VERSION "ADD"

NS_ :

BS_:

BU_: ADD

BO_ 341 ADD_ChassisCANFD_0x155: 32 ADD
 SG_ HPPAVPRecoverIndCtrl : 135|2@0+ (1,0) [0|3] "" Vector__XXX
 SG_ HPPAVPSteerReqSigGrpChks : 103|8@0+ (1,0) [0|255] "" Vector__XXX
 SG_ HPPAVPSteerReqSigGrpCntr : 107|4@0+ (1,0) [0|15] "" Vector__XXX
 SG_ HPPAVPSteerWhlAglReqVal : 119|15@0- (0.0625,0) [-780|780] "deg" Vector__XXX
 SG_ HPPAVPSteerWhlCtrlReqSts : 133|2@0+ (1,0) [0|3] "" Vector__XXX
 SG_ ParkAPBReqMainFrmADD : 73|2@0+ (1,0) [0|3] "" Vector__XXX
 SG_ ParkEPSLateralCtrlTypeFrmADD : 186|3@0+ (1,0) [0|7] "" Vector__XXX
 SG_ ParkRecoverIndCtrlFrmADD : 188|2@0+ (1,0) [0|3] "" Vector__XXX
 SG_ ParkSteerWhlAglReqValFrmADD : 199|15@0- (0.0625,0) [-1024|1023.9375] "deg" Vector__XXX
 SG_ ParkSteerWhlAngReqSigGrpChks : 175|8@0+ (1,0) [0|255] "" Vector__XXX
 SG_ ParkSteerWhlAngReqSigGrpCntr : 179|4@0+ (1,0) [0|15] "" Vector__XXX
 SG_ ParkSteerWhlCtrlReqStsFrmADD : 214|2@0+ (1,0) [0|3] "" Vector__XXX
 SG_ PASBrkFcnModMainFrmADD : 15|3@0+ (1,0) [0|7] "" Vector__XXX
 SG_ PASBrkFrmADDSigGrpChks : 7|8@0+ (1,0) [0|255] "" Vector__XXX
 SG_ PASBrkFrmADDSigGrpCntr : 11|4@0+ (1,0) [0|15] "" Vector__XXX
 SG_ PASEmgyBrkReqMainFrmADD : 77|1@0+ (1,0) [0|1] "" Vector__XXX
 SG_ PASLoLimForAccrCmftMainFrmADD : 47|8@0+ (0.01,0) [0|2.55] "mps2" Vector__XXX
 SG_ PASMaxAllwdJerkOfAccrMainFrmADD : 87|8@0+ (0.1,0) [0|25.5] "mps3" Vector__XXX
 SG_ PASMinAllwdJerkOfAccrMainFrmADD : 71|8@0+ (0.1,0) [0|25.5] "mps3" Vector__XXX
 SG_ PASRemaDstMainFrmADD : 55|12@0+ (1,0) [0|4095] "" Vector__XXX
 SG_ PASReqAccCtrlEnaMainFrmADD : 12|1@0+ (1,0) [0|1] "" Vector__XXX
 SG_ PASReqBrkPrfeMainFrmADD : 27|1@0+ (1,0) [0|1] "" Vector__XXX
 SG_ PASReqDclUtiStslMainFrmADD : 78|1@0+ (1,0) [0|1] "" Vector__XXX
 SG_ PASReqDrvOffMainFrmADD : 79|1@0+ (1,0) [0|1] "" Vector__XXX
 SG_ PASShdModReqMainFrmADD : 75|2@0+ (1,0) [0|3] "" Vector__XXX
 SG_ PASUpprLimForAccrCmftMainFrmADD : 39|8@0+ (0.01,0) [0|2.55] "mps2" Vector__XXX
 SG_ PASVlcTarAccFromPASMainFrmADD : 23|12@0+ (0.01,-10) [-10|30.95] "mps2" Vector__XXX

BO_ 483 ADD_ChassisCANFD_0x1E3: 16 ADD
 SG_ ADSBSDLCAEnableForSRR : 31|2@0+ (1,0) [0|3] "" Vector__XXX
 SG_ ADSDOWEnableForSRR : 29|2@0+ (1,0) [0|3] "" Vector__XXX
 SG_ ADSRCTABEnableForSRR : 27|2@0+ (1,0) [0|3] "" Vector__XXX
 SG_ ADSRCWEnableForSRR : 25|2@0+ (1,0) [0|3] "" Vector__XXX
 SG_ DvrSpclOpratDistFrmADD : 39|9@0+ (1,0) [0|500] "" Vector__XXX
 SG_ DvrSpclOpratIndFrmADD : 46|4@0+ (1,0) [0|10] "" Vector__XXX
 SG_ GroundAdhereConf : 7|7@0+ (1,0) [0|127] "" Vector__XXX
 SG_ GroundAdhereType : 23|3@0+ (1,0) [0|7] "" Vector__XXX
 SG_ GroundLayingConf : 15|7@0+ (1,0) [0|127] "" Vector__XXX
 SG_ GroundLayingType : 20|3@0+ (1,0) [0|7] "" Vector__XXX
 SG_ RoadMueDistFrmADD : 64|9@0+ (1,0) [0|500] "" Vector__XXX
 SG_ RoadMueFrmADD : 70|4@0+ (0.1,0) [0|1.5] "" Vector__XXX
 SG_ RoadMueLenthFrmADD : 87|9@0+ (1,0) [0|500] "" Vector__XXX

BO_ 769 ADD_ChassisCANFD_0x301: 24 ADD
 SG_ ACCInitSpdSwtFbFrmADD : 79|3@0+ (1,0) [0|7] "" Vector__XXX
 SG_ ACCInitSpdSwtUnavlRsnFrmADD : 135|3@0+ (1,0) [0|7] "" Vector__XXX
 SG_ ADSAEBFCWSwtFbFrmADD : 87|3@0+ (1,0) [0|5] "" Vector__XXX
 SG_ ADSAEBSwtUnavlRsnFrmADD : 95|4@0+ (1,0) [0|11] "" Vector__XXX
 SG_ ADSAESESSSwtFbFrmADD : 23|2@0+ (1,0) [0|3] "" Vector__XXX
 SG_ ADSAudModSwtStsFrmADD : 21|3@0+ (1,0) [0|7] "" Vector__XXX
 SG_ ADSBSDLCASwtFbFrmADD : 18|3@0+ (1,0) [0|7] "" Vector__XXX
 SG_ ADSBSDLCASwtUnavlRsnFrmADD : 91|4@0+ (1,0) [0|11] "" Vector__XXX
 SG_ ADSDOWSwtFbFrmADD : 76|3@0+ (1,0) [0|7] "" Vector__XXX
 SG_ ADSDOWSwtUnavlRsnFrmADD : 103|4@0+ (1,0) [0|11] "" Vector__XXX
 SG_ ADSELKSwtFbFrmADD : 26|3@0+ (1,0) [0|4] "" Vector__XXX
 SG_ ADSELKSwtUnavlRsnFrmADD : 99|4@0+ (1,0) [0|11] "" Vector__XXX
 SG_ ADSLDPWarnTypSwtUnavlRsnFrmADD : 111|4@0+ (1,0) [0|12] "" Vector__XXX
 SG_ ADSLDWPSwtFbFrmADD : 36|3@0+ (1,0) [0|4] "" Vector__XXX
 SG_ ADSLDWPSwtUnavlRsnFrmADD : 107|4@0+ (1,0) [0|11] "" Vector__XXX
 SG_ ADSLDWPWarnTypSwtFbFrmADD : 84|3@0+ (1,0) [0|4] "" Vector__XXX
 SG_ ADSMAISwtFbFrmADD : 175|3@0+ (1,0) [0|7] "" Vector__XXX
 SG_ ADSMAISwtUnavlRsnFrmADD : 179|4@0+ (1,0) [0|15] "" Vector__XXX
 SG_ ADSParkAudModSwtStsFrmADD : 29|3@0+ (1,0) [0|7] "" Vector__XXX
 SG_ ADSRCTABSwtFbFrmADD : 46|3@0+ (1,0) [0|7] "" Vector__XXX
 SG_ ADSRCTABSwtUnavlRsnFrmADD : 119|4@0+ (1,0) [0|11] "" Vector__XXX
 SG_ ADSRCWSwtFbFrmADD : 41|2@0+ (1,0) [0|3] "" Vector__XXX
 SG_ ADSRCWSwtUnavlRsnFrmADD : 115|4@0+ (1,0) [0|11] "" Vector__XXX
 SG_ ADSTLASwtFbFrmADD : 187|2@0+ (1,0) [0|3] "" Vector__XXX
 SG_ ADSTLASwtUnavlRsnFrmADD : 183|4@0+ (1,0) [0|11] "" Vector__XXX
 SG_ ADSwtStsSigGrpChks : 7|8@0+ (1,0) [0|255] "" Vector__XXX
 SG_ ADSwtStsSigGrpCntr : 11|4@0+ (1,0) [0|15] "" Vector__XXX
 SG_ ALCSwtStsFrmADD : 55|3@0+ (1,0) [0|7] "" Vector__XXX
 SG_ ALCSwtUnavlRsnFrmADD : 127|4@0+ (1,0) [0|15] "" Vector__XXX
 SG_ FxdSpdModValSwtStsFrmADD : 143|6@0+ (1,0) [0|63] "" Vector__XXX
 SG_ LaneChgCnfmSwtStsFrmADD : 52|2@0+ (1,0) [0|3] "" Vector__XXX
 SG_ LowPwrReqFrLRRFrmADD : 185|2@0+ (1,0) [0|3] "" Vector__XXX
 SG_ LowPwrSwtFbFrmADD : 50|3@0+ (1,0) [0|7] "" Vector__XXX
 SG_ LowPwrSwtUnavlRsnFrmADD : 71|3@0+ (1,0) [0|5] "" Vector__XXX
 SG_ LowPwrWarnFrmADD : 63|3@0+ (1,0) [0|7] "" Vector__XXX
 SG_ NOAautoChangingSrAnimation : 191|2@0+ (1,0) [0|3] "" Vector__XXX
 SG_ NOACtySwtStsFrmADD : 162|3@0+ (1,0) [0|7] "" Vector__XXX
 SG_ NOAHWSwtStsFrmADD : 58|3@0+ (1,0) [0|7] "" Vector__XXX
 SG_ NOASwtUnavlRsnFrmADD : 123|4@0+ (1,0) [0|15] "" Vector__XXX
 SG_ PcntgeSpdModValSwtStsFrmADD : 148|5@0+ (1,0) [0|31] "" Vector__XXX
 SG_ PltSwtStsFrmADD : 68|3@0+ (1,0) [0|7] "" Vector__XXX
 SG_ PltSwtUnavlRsnFrmADD : 159|4@0+ (1,0) [0|15] "" Vector__XXX
 SG_ PntCldSwtFbFrmADD : 65|2@0+ (1,0) [0|3] "" Vector__XXX
 SG_ PntCldSwtUnavlRsnFrmADD : 155|4@0+ (1,0) [0|15] "" Vector__XXX
 SG_ PrivacyModIniStsFrmADD : 137|2@0+ (1,0) [0|3] "" Vector__XXX
 SG_ PrivacyModSwtFbFrmADD : 167|2@0+ (1,0) [0|3] "" Vector__XXX
 SG_ SRLidarCldReqFrmADD : 189|2@0+ (1,0) [0|3] "" Vector__XXX
 SG_ VehSpdDvtionModSwtStsFrmADD : 165|3@0+ (1,0) [0|7] "" Vector__XXX

BO_ 131 ADD_ChassisCANFD_0x83: 16 ADD
 SG_ ChecksumADD2Radar : 15|8@0+ (1,0) [0|255] "" Vector__XXX
 SG_ OfsTimeNSecADD2Radar : 103|32@0+ (1,0) [0|4294967295] "" Vector__XXX
 SG_ OfsTimeSecADD2Radar : 71|32@0+ (1,0) [0|4294967295] "" Vector__XXX
 SG_ SyncMsgOvsADD2Radar : 25|2@0+ (1,0) [0|3] "" Vector__XXX
 SG_ SyncMsgSequenceCounterADD2Radar : 19|4@0+ (1,0) [0|15] "" Vector__XXX
 SG_ SyncMsgSgwADDtoRadar : 26|1@0+ (1,0) [0|1] "" Vector__XXX
 SG_ SyncMsgSyncTimeADD2Radar : 39|32@0+ (1,0) [0|4294967295] "" Vector__XXX
 SG_ SyncMsgTimeDomainADD2Radar : 23|4@0+ (1,0) [0|15] "" Vector__XXX
 SG_ SyncMsgTypeADD2Radar : 7|8@0+ (1,0) [0|255] "" Vector__XXX

BO_ 177 ADD_ChassisCANFD_0xB1: 32 ADD
 SG_ ADSABALvlFrmADD : 183|3@0+ (1,0) [0|7] "" Vector__XXX
 SG_ ADSABAReqFrmADD : 180|1@0+ (1,0) [0|1] "" Vector__XXX
 SG_ ADSABPReqFrmADD : 179|1@0+ (1,0) [0|1] "" Vector__XXX
 SG_ ADSAEBReqFrmADD : 178|3@0+ (1,0) [0|7] "" Vector__XXX
 SG_ ADSAEBTarDecelFrmADD : 191|10@0+ (0.03125,-16) [-16|15.96875] "mps2" Vector__XXX
 SG_ ADSAWBAESLvlFrmADD : 197|3@0+ (1,0) [0|7] "" Vector__XXX
 SG_ ADSAWBAESReqFrmADD : 194|2@0+ (1,0) [0|3] "" Vector__XXX
 SG_ ADSMAIAccrPerReqFrmADD : 231|8@0+ (1,0) [0|255] "%" Vector__XXX
 SG_ ADSMAIAccrPerReqVldFrmADD : 223|1@0+ (1,0) [0|1] "" Vector__XXX
 SG_ ADSMAIReqFrmADD : 222|1@0+ (1,0) [0|1] "" Vector__XXX
 SG_ ADSMAIReqVldFrmADD : 221|1@0+ (1,0) [0|1] "" Vector__XXX
 SG_ ADSVibActvFrmADD : 143|1@0+ (1,0) [0|1] "" Vector__XXX
 SG_ DrvAxTarEnaMainFrmADD : 31|1@0+ (1,0) [0|1] "" Vector__XXX
 SG_ DrvAxTarLowerComfBandMainFrmADD : 30|7@0+ (0.01,0) [0|1.27] "mps2" Vector__XXX
 SG_ DrvAxTarReqMainFrmADD : 55|15@0+ (0.001,-20.48) [-20.48|12.287] "mps2" Vector__XXX
 SG_ DrvAxTarUpperComfBandMainFrmADD : 22|7@0+ (0.01,0) [0|1.27] "mps2" Vector__XXX
 SG_ DrvBrakePreferredMainFrmADD : 47|1@0+ (1,0) [0|1] "" Vector__XXX
 SG_ DrvCtrlAvailabilityMainFrmADD : 15|1@0+ (1,0) [0|1] "" Vector__XXX
 SG_ DrvdAxTarLowerLimitMainFrmADD : 46|7@0+ (0.1,0) [0|12.7] "mps3" Vector__XXX
 SG_ DrvdAxTarUpperLimitMainFrmADD : 70|7@0+ (0.1,0) [0|12.7] "mps3" Vector__XXX
 SG_ DrvDriveAwayReqMainFrmADD : 36|1@0+ (1,0) [0|1] "" Vector__XXX
 SG_ DrvFcn2FrmADDSigGrpChks : 7|8@0+ (1,0) [0|255] "" Vector__XXX
 SG_ DrvFcn2FrmADDSigGrpCntr : 11|4@0+ (1,0) [0|15] "" Vector__XXX
 SG_ DrvFcn3FrmADDSigGrpChks : 167|8@0+ (1,0) [0|255] "" Vector__XXX
 SG_ DrvFcn3FrmADDSigGrpCntr : 171|4@0+ (1,0) [0|15] "" Vector__XXX
 SG_ DrvFcn4FrmADDSigGrpChks : 215|8@0+ (1,0) [0|255] "" Vector__XXX
 SG_ DrvFcn4FrmADDSigGrpCntr : 219|4@0+ (1,0) [0|15] "" Vector__XXX
 SG_ DrvPinStrAglReqStsFrmADD : 129|2@0+ (1,0) [0|3] "" Vector__XXX
 SG_ DrvPinStrAglReqValFrmADD : 102|15@0+ (0.05,-819.2) [-819.2|819.15] "deg" Vector__XXX
 SG_ DrvPrecsReqFrmADD : 142|7@0+ (1,0) [0|126] "%" Vector__XXX
 SG_ DrvReqModeMainFrmADD : 13|2@0+ (1,0) [0|3] "" Vector__XXX
 SG_ DrvReqTypeMainFrmADD : 14|1@0+ (1,0) [0|1] "" Vector__XXX
 SG_ DrvSecureReqMainFrmADD : 23|1@0+ (1,0) [0|1] "" Vector__XXX
 SG_ DrvShutdownModeMainFrmADD : 38|2@0+ (1,0) [0|3] "" Vector__XXX
 SG_ DrvSteerWhlReqFrmADDSigGrpChks : 87|8@0+ (1,0) [0|255] "" Vector__XXX
 SG_ DrvSteerWhlReqFrmADDSigGrpCntr : 91|4@0+ (1,0) [0|15] "" Vector__XXX
 SG_ DrvSteerWhlTqLimFrmADD : 119|11@0+ (0.01,-10.24) [-10.24|10.23] "Nm" Vector__XXX
 SG_ DrvUseUpperComfBandMainFrmADD : 39|1@0+ (1,0) [0|1] "" Vector__XXX
 SG_ DrvVehStopReqMainFrmADD : 56|1@0+ (1,0) [0|1] "" Vector__XXX

BO_ 193 ADD_ChassisCANFD_0xC1: 16 ADD
 SG_ ADASGearFcnModMainFrmADD : 55|3@0+ (1,0) [0|7] "" Vector__XXX
 SG_ ADASParkDrvFcnModMainFrmADD : 52|3@0+ (1,0) [0|7] "" Vector__XXX
 SG_ ADASParkDrvModOverrideFrmADD : 49|2@0+ (1,0) [0|3] "" Vector__XXX
 SG_ ADASParkDrvVehWheelTqEnaFrmADD : 63|1@0+ (1,0) [0|1] "" Vector__XXX
 SG_ ADASParkDrvVehWheelTqReqFrmADD : 39|16@0+ (1,-30000) [-30000|30000] "" Vector__XXX
 SG_ ADSAVHReqFrmADD : 62|2@0+ (1,0) [0|3] "" Vector__XXX
 SG_ ADSBCSTqReqChks : 7|8@0+ (1,0) [0|255] "" Vector__XXX
 SG_ ADSBCSTqReqCntr : 11|4@0+ (1,0) [0|15] "" Vector__XXX
 SG_ ADSEPBReqMainFrmADD : 13|2@0+ (1,0) [0|3] "" Vector__XXX
 SG_ ADSReqModeMainFrmADD : 60|3@0+ (1,0) [0|7] "" Vector__XXX
 SG_ ADSTqTarEnaMainTypeFrmADD : 57|2@0+ (1,0) [0|3] "" Vector__XXX
 SG_ ADSTqTarReqMainFrmADD : 23|16@0+ (1,-30000) [-30000|0] "" Vector__XXX

BO_ 237 ADD_ChassisCANFD_0xED: 16 ADD
 SG_ ADSACCStsFrmADD : 18|3@0+ (1,0) [0|7] "" Vector__XXX
 SG_ ADSWarnRemdSigGrpChks : 39|8@0+ (1,0) [0|255] "" Vector__XXX
 SG_ ADSWarnRemdSigGrpCntr : 43|4@0+ (1,0) [0|15] "" Vector__XXX
 SG_ CNOAAlrtWarnLv1FrmADD : 93|3@0+ (1,0) [0|7] "" Vector__XXX
 SG_ CNOAAlrtWarnLv3FrmADD : 90|3@0+ (1,0) [0|7] "" Vector__XXX
 SG_ CNOAIntrctvCompntTypFrmADD : 119|5@0+ (1,0) [0|31] "" Vector__XXX
 SG_ CNOARemd2FrmADD : 47|4@0+ (1,0) [0|15] "" Vector__XXX
 SG_ CNOARemdFrmADD : 127|5@0+ (1,0) [0|31] "" Vector__XXX
 SG_ DistLvlLmtDispFrmADD : 55|2@0+ (1,0) [0|3] "" Vector__XXX
 SG_ DrvAlrtWarnLv1FrmADD : 53|3@0+ (1,0) [0|7] "" Vector__XXX
 SG_ DrvAlrtWarnLv2FrmADD : 50|3@0+ (1,0) [0|7] "" Vector__XXX
 SG_ DrvAlrtWarnLv3FrmADD : 71|3@0+ (1,0) [0|7] "" Vector__XXX
 SG_ DrvFcn1FrmADDSigGrpChks : 7|8@0+ (1,0) [0|255] "" Vector__XXX
 SG_ DrvFcn1FrmADDSigGrpCntr : 11|4@0+ (1,0) [0|15] "" Vector__XXX
 SG_ DrvFltStsFrmADD : 21|3@0+ (1,0) [0|7] "" Vector__XXX
 SG_ DrvFltStsVldFrmADD : 22|1@0+ (1,0) [0|1] "" Vector__XXX
 SG_ DrvLatIcnDispStsFrmADD : 63|4@0+ (1,0) [0|15] "" Vector__XXX
 SG_ DrvLongIcnDispFrmADD : 68|3@0+ (1,0) [0|7] "" Vector__XXX
 SG_ DrvRemd2FrmADD : 59|4@0+ (1,0) [0|15] "" Vector__XXX
 SG_ DrvRemdFrmADD : 103|7@0+ (1,0) [0|127] "" Vector__XXX
 SG_ DrvrSelTarSpdFrmADD : 96|9@0+ (1,0) [0|255] "kmph" Vector__XXX
 SG_ DrvSteerWhlBtnLi : 65|2@0+ (1,0) [0|3] "" Vector__XXX
 SG_ DrvStlDispFrmADD : 79|3@0+ (1,0) [0|7] "" Vector__XXX
 SG_ IntrctvCompntTypFrmADD : 87|6@0+ (1,0) [0|63] "" Vector__XXX
 SG_ LaneChangeModFrmADD : 76|2@0+ (1,0) [0|3] "" Vector__XXX
 SG_ ScrnDrvFuncTypFrmADD : 74|3@0+ (1,0) [0|7] "" Vector__XXX
 SG_ SpdLvlLmtDispFrmADD : 81|2@0+ (1,0) [0|3] "" Vector__XXX
 SG_ TarSpdSetMothodFrmADD : 95|2@0+ (1,0) [0|3] "" Vector__XXX

BO_ 1329 ADDChassisCanfdNMFrA: 8 ADD
 SG_ ADDChassisCanfdActiveWakeup : 12|1@0+ (1,0) [0|1] "" Vector__XXX
 SG_ ADDChassisCanfdNodeAddress : 7|8@0+ (1,0) [0|255] "" Vector__XXX
 SG_ ADDChassisCanfdRepeatMsgReq : 8|1@0+ (1,0) [0|1] "" Vector__XXX
 SG_ ADDChassisCanfdRepeatMsgSt : 16|1@0+ (1,0) [0|1] "" Vector__XXX
 SG_ NMKeepAwkRsnADD : 48|9@0+ (1,0) [0|511] "" Vector__XXX
 SG_ UDB17ADD : 17|1@0+ (1,0) [0|1] "" Vector__XXX
 SG_ UDB18ADD : 18|1@0+ (1,0) [0|1] "" Vector__XXX
 SG_ UDB19ADD : 19|1@0+ (1,0) [0|1] "" Vector__XXX
 SG_ UDB20ADD : 20|1@0+ (1,0) [0|1] "" Vector__XXX
 SG_ UDB21ADD : 21|1@0+ (1,0) [0|1] "" Vector__XXX
 SG_ UDB22ADD : 22|1@0+ (1,0) [0|1] "" Vector__XXX
 SG_ UDB23ADD : 23|1@0+ (1,0) [0|1] "" Vector__XXX
 SG_ UDB24ADD : 24|1@0+ (1,0) [0|1] "" Vector__XXX
 SG_ UDB25ADD : 25|1@0+ (1,0) [0|1] "" Vector__XXX
 SG_ UDB26ADD : 26|1@0+ (1,0) [0|1] "" Vector__XXX
 SG_ UDB27ADD : 27|1@0+ (1,0) [0|1] "" Vector__XXX
 SG_ UDB28ADD : 28|1@0+ (1,0) [0|1] "" Vector__XXX
 SG_ UDB29ADD : 29|1@0+ (1,0) [0|1] "" Vector__XXX
 SG_ UDB30ADD : 30|1@0+ (1,0) [0|1] "" Vector__XXX
 SG_ UDB31ADD : 31|1@0+ (1,0) [0|1] "" Vector__XXX
 SG_ UDB32ADD : 32|1@0+ (1,0) [0|1] "" Vector__XXX
 SG_ UDB33ADD : 33|1@0+ (1,0) [0|1] "" Vector__XXX
 SG_ UDB34ADD : 34|1@0+ (1,0) [0|1] "" Vector__XXX
 SG_ UDB35ADD : 35|1@0+ (1,0) [0|1] "" Vector__XXX
 SG_ UDB36ADD : 36|1@0+ (1,0) [0|1] "" Vector__XXX
 SG_ UDB37ADD : 37|1@0+ (1,0) [0|1] "" Vector__XXX
 SG_ UDB38ADD : 38|1@0+ (1,0) [0|1] "" Vector__XXX
 SG_ UDB39ADD : 39|1@0+ (1,0) [0|1] "" Vector__XXX
 SG_ UDB40ADD : 40|1@0+ (1,0) [0|1] "" Vector__XXX
 SG_ UDB41ADD : 41|1@0+ (1,0) [0|1] "" Vector__XXX
 SG_ UDB42ADD : 42|1@0+ (1,0) [0|1] "" Vector__XXX
 SG_ UDB43ADD : 43|1@0+ (1,0) [0|1] "" Vector__XXX
 SG_ UDB44ADD : 44|1@0+ (1,0) [0|1] "" Vector__XXX
 SG_ UDB45ADD : 45|1@0+ (1,0) [0|1] "" Vector__XXX
 SG_ UDB46ADD : 46|1@0+ (1,0) [0|1] "" Vector__XXX
 SG_ UDB47ADD : 47|1@0+ (1,0) [0|1] "" Vector__XXX

BO_ 1325 ADDChassisCanfdNMFrB: 8 ADD
 SG_ ADDChassisCanfdActiveWakeup1 : 12|1@0+ (1,0) [0|1] "" Vector__XXX
 SG_ ADDChassisCanfdNodeAddress1 : 7|8@0+ (1,0) [0|255] "" Vector__XXX
 SG_ ADDChassisCanfdRepeatMsgReq1 : 8|1@0+ (1,0) [0|1] "" Vector__XXX
 SG_ ADDChassisCanfdRepeatMsgSt1 : 16|1@0+ (1,0) [0|1] "" Vector__XXX
 SG_ NMKeepAwkRsnADD : 48|9@0+ (1,0) [0|511] "" Vector__XXX
 SG_ UDB17ADD : 17|1@0+ (1,0) [0|1] "" Vector__XXX
 SG_ UDB18ADD : 18|1@0+ (1,0) [0|1] "" Vector__XXX
 SG_ UDB19ADD : 19|1@0+ (1,0) [0|1] "" Vector__XXX
 SG_ UDB20ADD : 20|1@0+ (1,0) [0|1] "" Vector__XXX
 SG_ UDB21ADD : 21|1@0+ (1,0) [0|1] "" Vector__XXX
 SG_ UDB22ADD : 22|1@0+ (1,0) [0|1] "" Vector__XXX
 SG_ UDB23ADD : 23|1@0+ (1,0) [0|1] "" Vector__XXX
 SG_ UDB24ADD : 24|1@0+ (1,0) [0|1] "" Vector__XXX
 SG_ UDB25ADD : 25|1@0+ (1,0) [0|1] "" Vector__XXX
 SG_ UDB26ADD : 26|1@0+ (1,0) [0|1] "" Vector__XXX
 SG_ UDB27ADD : 27|1@0+ (1,0) [0|1] "" Vector__XXX
 SG_ UDB28ADD : 28|1@0+ (1,0) [0|1] "" Vector__XXX
 SG_ UDB29ADD : 29|1@0+ (1,0) [0|1] "" Vector__XXX
 SG_ UDB30ADD : 30|1@0+ (1,0) [0|1] "" Vector__XXX
 SG_ UDB31ADD : 31|1@0+ (1,0) [0|1] "" Vector__XXX
 SG_ UDB32ADD : 32|1@0+ (1,0) [0|1] "" Vector__XXX
 SG_ UDB33ADD : 33|1@0+ (1,0) [0|1] "" Vector__XXX
 SG_ UDB34ADD : 34|1@0+ (1,0) [0|1] "" Vector__XXX
 SG_ UDB35ADD : 35|1@0+ (1,0) [0|1] "" Vector__XXX
 SG_ UDB36ADD : 36|1@0+ (1,0) [0|1] "" Vector__XXX
 SG_ UDB37ADD : 37|1@0+ (1,0) [0|1] "" Vector__XXX
 SG_ UDB38ADD : 38|1@0+ (1,0) [0|1] "" Vector__XXX
 SG_ UDB39ADD : 39|1@0+ (1,0) [0|1] "" Vector__XXX
 SG_ UDB40ADD : 40|1@0+ (1,0) [0|1] "" Vector__XXX
 SG_ UDB41ADD : 41|1@0+ (1,0) [0|1] "" Vector__XXX
 SG_ UDB42ADD : 42|1@0+ (1,0) [0|1] "" Vector__XXX
 SG_ UDB43ADD : 43|1@0+ (1,0) [0|1] "" Vector__XXX
 SG_ UDB44ADD : 44|1@0+ (1,0) [0|1] "" Vector__XXX
 SG_ UDB45ADD : 45|1@0+ (1,0) [0|1] "" Vector__XXX
 SG_ UDB46ADD : 46|1@0+ (1,0) [0|1] "" Vector__XXX
 SG_ UDB47ADD : 47|1@0+ (1,0) [0|1] "" Vector__XXX

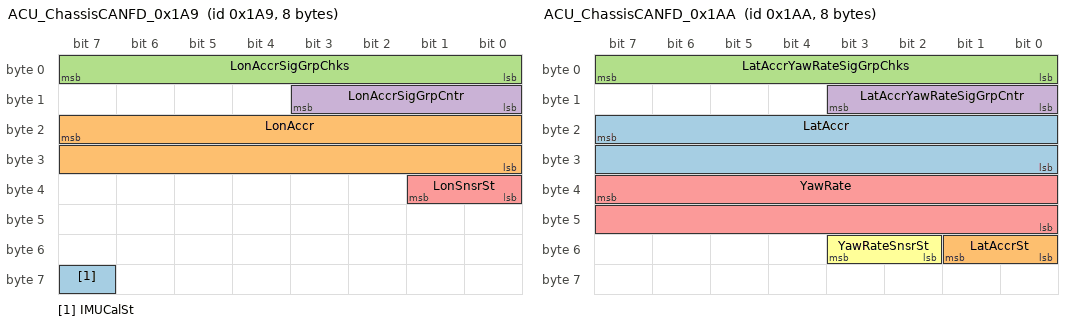
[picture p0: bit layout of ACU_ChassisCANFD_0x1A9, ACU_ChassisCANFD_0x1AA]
BO_ 425 ACU_ChassisCANFD_0x1A9: 8 Vector__XXX
 SG_ IMUCalSt : 63|1@0+ (1,0) [0|1] ""  ADD
 SG_ LonAccr : 23|16@0+ (0.0002,-5) [-5|5] "g"  ADD
 SG_ LonAccrSigGrpChks : 7|8@0+ (1,0) [0|255] ""  ADD
 SG_ LonAccrSigGrpCntr : 11|4@0+ (1,0) [0|15] ""  ADD
 SG_ LonSnsrSt : 33|2@0+ (1,0) [0|3] ""  ADD

BO_ 426 ACU_ChassisCANFD_0x1AA: 8 Vector__XXX
 SG_ LatAccr : 23|16@0+ (0.0002,-5) [-5|5] "g"  ADD
 SG_ LatAccrSt : 49|2@0+ (1,0) [0|3] ""  ADD
 SG_ LatAccrYawRateSigGrpChks : 7|8@0+ (1,0) [0|255] ""  ADD
 SG_ LatAccrYawRateSigGrpCntr : 11|4@0+ (1,0) [0|15] ""  ADD
 SG_ YawRate : 39|16@0+ (0.01,-300) [-300|300] "deg/s"  ADD
 SG_ YawRateSnsrSt : 51|2@0+ (1,0) [0|3] ""  ADD

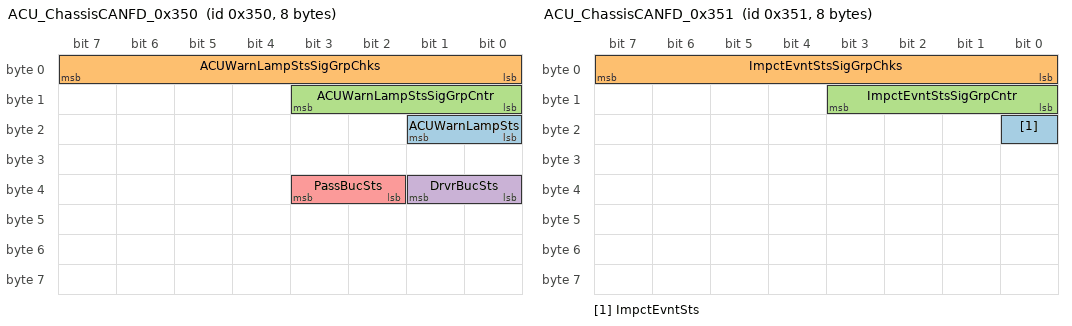
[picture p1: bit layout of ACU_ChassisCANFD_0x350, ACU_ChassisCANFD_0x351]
BO_ 848 ACU_ChassisCANFD_0x350: 8 Vector__XXX
 SG_ ACUWarnLampSts : 17|2@0+ (1,0) [0|3] ""  ADD
 SG_ ACUWarnLampStsSigGrpChks : 7|8@0+ (1,0) [0|255] ""  ADD
 SG_ ACUWarnLampStsSigGrpCntr : 11|4@0+ (1,0) [0|15] ""  ADD
 SG_ DrvrBucSts : 33|2@0+ (1,0) [0|3] ""  ADD
 SG_ PassBucSts : 35|2@0+ (1,0) [0|3] ""  ADD

BO_ 849 ACU_ChassisCANFD_0x351: 8 Vector__XXX
 SG_ ImpctEvntSts : 16|1@0+ (1,0) [0|1] ""  ADD
 SG_ ImpctEvntStsSigGrpChks : 7|8@0+ (1,0) [0|255] ""  ADD
 SG_ ImpctEvntStsSigGrpCntr : 11|4@0+ (1,0) [0|15] ""  ADD

BO_ 336 BCP_ChassisCANFD_0x150: 16 Vector__XXX
 SG_ ABAActv : 94|1@0+ (1,0) [0|1] ""  ADD
 SG_ ABAAvl : 95|1@0+ (1,0) [0|1] ""  ADD
 SG_ APBAplAvlBCP : 61|2@0+ (1,0) [0|2] ""  ADD
 SG_ APBRelAvlBCP : 59|2@0+ (1,0) [0|3] ""  ADD
 SG_ APBStsBkp : 91|3@0+ (1,0) [0|7] ""  ADD
 SG_ BCPBrkLiIllmnReq : 19|1@0+ (1,0) [0|1] ""  ADD
 SG_ BCPBrkSysWarnText : 45|3@0+ (1,0) [0|7] ""  ADD
 SG_ BCPMstCylP : 57|10@0+ (0.3,-30) [-30|276.6] "bar"  ADD
 SG_ BCPMstCylPVld : 15|2@0+ (1,0) [0|2] ""  ADD
 SG_ BCPSimulatorP : 41|10@0+ (0.3,-30) [-30|276.6] "bar"  ADD
 SG_ BCPSimulatorPVld : 63|2@0+ (1,0) [0|2] ""  ADD
 SG_ BCPSysSts : 47|2@0+ (1,0) [0|3] ""  ADD
 SG_ BcpSysStsSigGrpChks : 7|8@0+ (1,0) [0|255] ""  ADD
 SG_ BcpSysStsSigGrpCntr : 11|4@0+ (1,0) [0|15] ""  ADD
 SG_ BrkAssSigGrpChks : 79|8@0+ (1,0) [0|255] ""  ADD
 SG_ BrkAssSigGrpCntr : 83|4@0+ (1,0) [0|15] ""  ADD
 SG_ BrkFldWarn : 23|1@0+ (1,0) [0|1] ""  ADD
 SG_ BrkFldWarnVld : 42|1@0+ (1,0) [0|1] ""  ADD
 SG_ BrkPedlAppld : 22|1@0+ (1,0) [0|1] ""  ADD
 SG_ BrkPedlAppldVld : 21|2@0+ (1,0) [0|3] ""  ADD
 SG_ BrkPedlPerct : 38|7@0+ (1,0) [0|100] "%"  ADD
 SG_ BrkPedlPerctVld : 39|1@0+ (1,0) [0|1] ""  ADD
 SG_ HBAActv : 92|1@0+ (1,0) [0|1] ""  ADD
 SG_ HBAAvl : 93|1@0+ (1,0) [0|1] ""  ADD
 SG_ HBBActv : 110|1@0+ (1,0) [0|1] ""  ADD
 SG_ InpRodStk : 17|10@0+ (0.05,-5) [-5|46.1] "mm"  ADD
 SG_ InpRodStkVld : 18|1@0+ (1,0) [0|1] ""  ADD

BO_ 337 BCS_ChassisCANFD_0x151: 32 Vector__XXX
 SG_ ABPActv : 191|1@0+ (1,0) [0|1] ""  ADD
 SG_ ABPAvl : 197|1@0+ (1,0) [0|1] ""  ADD
 SG_ ABSActv : 16|1@0+ (1,0) [0|1] ""  ADD
 SG_ ABSErrDetd : 29|1@0+ (1,0) [0|1] ""  ADD
 SG_ AEBActv : 189|1@0+ (1,0) [0|1] ""  ADD
 SG_ AEBAvl : 190|1@0+ (1,0) [0|1] ""  ADD
 SG_ APBAplAvlBCS : 135|2@0+ (1,0) [0|2] ""  ADD
 SG_ APBErrDetd : 115|2@0+ (1,0) [0|3] ""  ADD
 SG_ APBRelAvlBCS : 133|2@0+ (1,0) [0|3] ""  ADD
 SG_ APBSts : 118|3@0+ (1,0) [0|7] ""  ADD
 SG_ APBTxtDip : 43|4@0+ (1,0) [0|15] ""  ADD
 SG_ AVHAvl : 139|1@0+ (1,0) [0|1] ""  ADD
 SG_ AVHSts : 141|2@0+ (1,0) [0|3] ""  ADD
 SG_ AWBActv : 198|1@0+ (1,0) [0|1] ""  ADD
 SG_ AWBAvl : 199|1@0+ (1,0) [0|1] ""  ADD
 SG_ BcsBasicFcnSigGrpChks : 87|8@0+ (1,0) [0|255] ""  ADD
 SG_ BcsBasicFcnSigGrpCntr : 91|4@0+ (1,0) [0|15] ""  ADD
 SG_ BCSBrkSysWarnText : 52|3@0+ (1,0) [0|7] ""  ADD
 SG_ BcsExtdFcnSigGrpChks : 175|8@0+ (1,0) [0|255] ""  ADD
 SG_ BcsExtdFcnSigGrpCntr : 179|4@0+ (1,0) [0|15] ""  ADD
 SG_ BcsSysCtrSigGrpChks : 7|8@0+ (1,0) [0|255] ""  ADD
 SG_ BcsSysCtrSigGrpCntr : 11|4@0+ (1,0) [0|15] ""  ADD
 SG_ BrkLiIllmnReq : 15|1@0+ (1,0) [0|1] ""  ADD
 SG_ BrkSysWarnLamp : 23|2@0+ (1,0) [0|3] ""  ADD
 SG_ CDPActv : 137|1@0+ (1,0) [0|1] ""  ADD
 SG_ CDPAvl : 136|1@0+ (1,0) [0|1] ""  ADD
 SG_ CSTSts : 58|2@0+ (1,0) [0|3] ""  ADD
 SG_ DrvOffTqThd : 103|15@0+ (1,0) [0|30000] "Nm"  ADD
 SG_ DSTActv : 119|1@0+ (1,0) [0|1] ""  ADD
 SG_ DSTSteerTqReq : 112|9@0- (0.1,0) [-6|6] "Nm"  ADD
 SG_ EBAActv : 188|1@0+ (1,0) [0|1] ""  ADD
 SG_ EBDActv : 31|1@0+ (1,0) [0|1] ""  ADD
 SG_ EBDErrDetd : 28|1@0+ (1,0) [0|1] ""  ADD
 SG_ EmgyBrkLiReq : 27|1@0+ (1,0) [0|1] ""  ADD
 SG_ ESCErrDetd : 30|1@0+ (1,0) [0|1] ""  ADD
 SG_ ESCIntvLamp : 19|1@0+ (1,0) [0|1] ""  ADD
 SG_ ESCPataLamp : 21|2@0+ (1,0) [0|3] ""  ADD
 SG_ ESCSwitchAvl : 55|3@0+ (1,0) [0|7] ""  ADD
 SG_ EstimdSumOfVehHydBrkEachWhl : 71|15@0+ (8,-250000) [-250000|0] "N"  ADD
 SG_ HBBActive : 72|1@0+ (1,0) [0|1] ""  ADD
 SG_ HBBSts : 63|2@0+ (1,0) [0|3] ""  ADD
 SG_ HBCActv : 56|1@0+ (1,0) [0|1] ""  ADD
 SG_ HDCAvl : 61|1@0+ (1,0) [0|1] ""  ADD
 SG_ HDCCtrlSts : 60|2@0+ (1,0) [0|3] ""  ADD
 SG_ HHCActv : 143|1@0+ (1,0) [0|1] ""  ADD
 SG_ HHCAvl : 142|1@0+ (1,0) [0|1] ""  ADD
 SG_ HRBActv : 25|1@0+ (1,0) [0|1] ""  ADD
 SG_ HRBAvl : 26|1@0+ (1,0) [0|1] ""  ADD
 SG_ HydBrkFExist : 14|1@0+ (1,0) [0|1] ""  ADD
 SG_ MstCylPCmp : 39|12@0+ (0.1,0) [0|250] "bar"  ADD
 SG_ MstCylPVld : 48|1@0+ (1,0) [0|1] ""  ADD
 SG_ SCMActv : 104|1@0+ (1,0) [0|1] ""  ADD
 SG_ SCMAvl : 138|1@0+ (1,0) [0|1] ""  ADD
 SG_ TCSActv : 17|1@0+ (1,0) [0|1] ""  ADD
 SG_ VDCActv : 18|1@0+ (1,0) [0|1] ""  ADD
 SG_ VehStandStillIndcr : 13|1@0+ (1,0) [0|1] ""  ADD
 SG_ VehStandStillIndcrVld : 12|1@0+ (1,0) [0|1] ""  ADD

BO_ 338 BCS_ChassisCANFD_0x152: 24 Vector__XXX
 SG_ APAActrAvl : 163|1@0+ (1,0) [0|1] ""  ADD
 SG_ APCActvVehHld : 175|1@0+ (1,0) [0|1] ""  ADD
 SG_ APCDrvrBrkOvrdFlg : 174|1@0+ (1,0) [0|1] ""  ADD
 SG_ APCFailrSts : 167|4@0+ (1,0) [0|15] ""  ADD
 SG_ ApcFcnSigGrpChks : 151|8@0+ (1,0) [0|255] ""  ADD
 SG_ ApcFcnSigGrpCntr : 155|4@0+ (1,0) [0|15] ""  ADD
 SG_ APCSts : 162|3@0+ (1,0) [0|4] ""  ADD
 SG_ BCSLgtCtrlPtTarTq : 39|16@0- (1,0) [-30000|30000] "Nm"  ADD
 SG_ BCSLgtCtrlPtTarTqEna : 24|1@0+ (1,0) [0|1] ""  ADD
 SG_ BcsTqCtrlSigGrpChks : 7|8@0+ (1,0) [0|255] ""  ADD
 SG_ BcsTqCtrlSigGrpCntr : 11|4@0+ (1,0) [0|15] ""  ADD
 SG_ BiasMaxFrntAxle : 119|7@0+ (1,0) [0|100] "%"  ADD
 SG_ BiasMaxReAxle : 127|7@0+ (1,0) [0|100] "%"  ADD
 SG_ CstRgnBlendSts : 135|2@0+ (1,0) [0|3] ""  ADD
 SG_ CstRgnBlendTqReqFA : 55|16@0- (1,0) [-30000|30000] "Nm"  ADD
 SG_ CstRgnBlendTqReqRA : 71|16@0- (1,0) [-30000|30000] "Nm"  ADD
 SG_ DrgTqCtrlActvFA : 112|1@0+ (1,0) [0|1] ""  ADD
 SG_ DrgTqCtrlActvRA : 120|1@0+ (1,0) [0|1] ""  ADD
 SG_ PtTqRednActvFA : 14|1@0+ (1,0) [0|1] ""  ADD
 SG_ PtTqRednActvRA : 15|1@0+ (1,0) [0|1] ""  ADD
 SG_ RPAAVPActrAvl : 173|2@0+ (1,0) [0|3] ""  ADD
 SG_ TarRdcdPtTqFA : 87|16@0- (1,0) [-30000|30000] "Nm"  ADD
 SG_ TarRdcdPtTqRA : 103|16@0- (1,0) [-30000|30000] "Nm"  ADD
 SG_ TarRecuTqReq : 23|15@0+ (1,-32767) [-32767|0] "Nm"  ADD
 SG_ TarRecuTqReqSts : 13|2@0+ (1,0) [0|3] ""  ADD

BO_ 352 BCS_ChassisCANFD_0x160: 32 Vector__XXX
 SG_ BcsDrvMonSigGrpChks : 39|8@0+ (1,0) [0|255] ""  ADD
 SG_ BcsDrvMonSigGrpCntr : 43|4@0+ (1,0) [0|15] ""  ADD
 SG_ BrkDiscTFrntLe : 55|8@0+ (5,-100) [-100|1000] "��"  ADD
 SG_ BrkDiscTFrntRi : 63|8@0+ (5,-100) [-100|1000] "��"  ADD
 SG_ BrkDiscTReLe : 71|8@0+ (5,-100) [-100|1000] "��"  ADD
 SG_ BrkDiscTReRi : 79|8@0+ (5,-100) [-100|1000] "��"  ADD
 SG_ BrkDiscTSts : 45|2@0+ (1,0) [0|3] ""  ADD
 SG_ BrkDiscTStsAval : 47|2@0+ (1,0) [0|2] ""  ADD
 SG_ RgnTqCorrnOffs1 : 87|16@0+ (0.05625,0) [0|360] ""  ADD
 SG_ RgnTqCorrnOffs2 : 103|8@0+ (1,-100) [-100|100] ""  ADD
 SG_ RgnTqCorrnOffs3 : 111|8@0+ (0.01,0) [0|1.5] ""  ADD
 SG_ RgnTqCorrnOffs4 : 119|16@0- (0.01,0) [-250|250] ""  ADD
 SG_ RgnTqCorrnOffs5 : 135|14@0+ (0.1,-100) [-100|1000] ""  ADD
 SG_ RgnTqCorrnOffs6 : 151|14@0+ (0.1,-100) [-100|1000] ""  ADD
 SG_ RgnTqCorrnOffs7 : 167|14@0+ (0.1,-100) [-100|1000] ""  ADD
 SG_ WhlPEstimdFrntLe : 199|8@0+ (1,0) [0|255] "bar"  ADD
 SG_ WhlPEstimdFrntLeVld : 231|1@0+ (1,0) [0|1] ""  ADD
 SG_ WhlPEstimdFrntRi : 207|8@0+ (1,0) [0|255] "bar"  ADD
 SG_ WhlPEstimdFrntRiVld : 230|1@0+ (1,0) [0|1] ""  ADD
 SG_ WhlPEstimdReLe : 215|8@0+ (1,0) [0|255] "bar"  ADD
 SG_ WhlPEstimdReLeVld : 229|1@0+ (1,0) [0|1] ""  ADD
 SG_ WhlPEstimdReRi : 223|8@0+ (1,0) [0|255] "bar"  ADD
 SG_ WhlPEstimdReRiVld : 228|1@0+ (1,0) [0|1] ""  ADD

BO_ 179 BCS_ChassisCANFD_0xB3: 32 Vector__XXX
 SG_ AdcFcnSigGrpChks : 223|8@0+ (1,0) [0|255] ""  ADD
 SG_ AdcFcnSigGrpCntr : 227|4@0+ (1,0) [0|15] ""  ADD
 SG_ BCSActrActvForADC : 231|2@0+ (1,0) [0|3] ""  ADD
 SG_ BCSActrAvlStsForADC : 239|3@0+ (1,0) [0|7] ""  ADD
 SG_ BCSActrAvlStsForADCL3 : 236|3@0+ (1,0) [0|7] ""  ADD
 SG_ BCSActrRampOffStsForADC : 229|2@0+ (1,0) [0|3] ""  ADD
 SG_ BCSActrVldForADC : 233|1@0+ (1,0) [0|1] ""  ADD
 SG_ VehSpd : 87|16@0+ (0.05625,0) [0|360] "kph"  ADD
 SG_ VehSpdVld : 103|1@0+ (1,0) [0|1] ""  ADD
 SG_ WhlDirFrntLe : 101|2@0+ (1,0) [0|3] ""  ADD
 SG_ WhlDirFrntLeVld : 102|1@0+ (1,0) [0|1] ""  ADD
 SG_ WhlDirFrntRi : 97|2@0+ (1,0) [0|3] ""  ADD
 SG_ WhlDirFrntRiVld : 98|1@0+ (1,0) [0|1] ""  ADD
 SG_ WhlDirReLe : 117|2@0+ (1,0) [0|3] ""  ADD
 SG_ WhlDirReLeVld : 118|1@0+ (1,0) [0|1] ""  ADD
 SG_ WhlDirReRi : 113|2@0+ (1,0) [0|3] ""  ADD
 SG_ WhlDirReRiVld : 114|1@0+ (1,0) [0|1] ""  ADD
 SG_ WhlDstTiStampFrntLe : 159|16@0+ (1,0) [0|65535] "ms"  ADD
 SG_ WhlDstTiStampFrntRi : 175|16@0+ (1,0) [0|65535] "ms"  ADD
 SG_ WhlDstTiStampReLe : 191|16@0+ (1,0) [0|65535] "ms"  ADD
 SG_ WhlDstTiStampReRi : 207|16@0+ (1,0) [0|65535] "ms"  ADD
 SG_ WhlSpdEdgeFrntLe : 111|8@0+ (1,0) [0|255] ""  ADD
 SG_ WhlSpdEdgeFrntLeVld : 99|1@0+ (1,0) [0|1] ""  ADD
 SG_ WhlSpdEdgeFrntRi : 127|8@0+ (1,0) [0|255] ""  ADD
 SG_ WhlSpdEdgeFrntRiVld : 119|1@0+ (1,0) [0|1] ""  ADD
 SG_ WhlSpdEdgeReLe : 135|8@0+ (1,0) [0|255] ""  ADD
 SG_ WhlSpdEdgeReLeVld : 115|1@0+ (1,0) [0|1] ""  ADD
 SG_ WhlSpdEdgeReRi : 151|8@0+ (1,0) [0|255] ""  ADD
 SG_ WhlSpdEdgeReRiVld : 143|1@0+ (1,0) [0|1] ""  ADD
 SG_ WhlSpdFrntLe : 23|16@0+ (0.05625,0) [0|360] "kph"  ADD
 SG_ WhlSpdFrntLeVld : 15|1@0+ (1,0) [0|1] ""  ADD
 SG_ WhlSpdFrntRi : 39|16@0+ (0.05625,0) [0|360] "kph"  ADD
 SG_ WhlSpdFrntRiVld : 14|1@0+ (1,0) [0|1] ""  ADD
 SG_ WhlSpdReLe : 55|16@0+ (0.05625,0) [0|360] "kph"  ADD
 SG_ WhlSpdReLeVld : 13|1@0+ (1,0) [0|1] ""  ADD
 SG_ WhlSpdReRi : 71|16@0+ (0.05625,0) [0|360] "kph"  ADD
 SG_ WhlSpdReRiVld : 12|1@0+ (1,0) [0|1] ""  ADD
 SG_ WhlStsSigGrpChks : 7|8@0+ (1,0) [0|255] ""  ADD
 SG_ WhlStsSigGrpCntr : 11|4@0+ (1,0) [0|15] ""  ADD

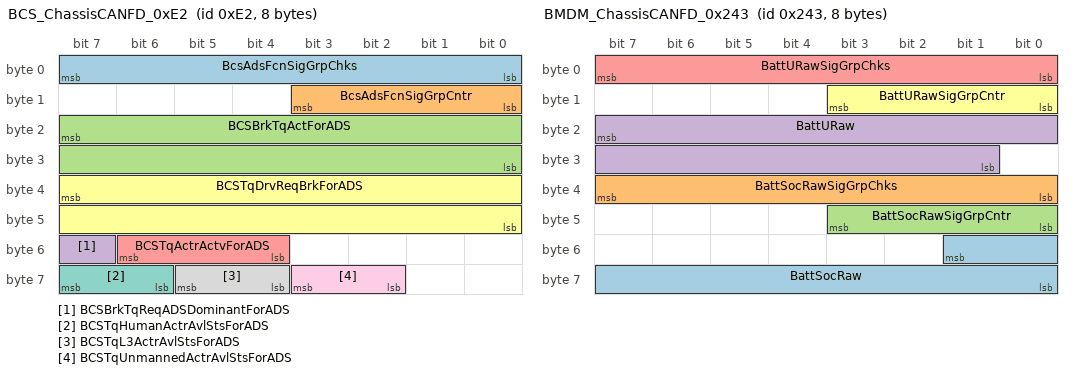
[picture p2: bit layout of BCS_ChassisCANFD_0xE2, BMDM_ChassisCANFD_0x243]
BO_ 226 BCS_ChassisCANFD_0xE2: 8 Vector__XXX
 SG_ BcsAdsFcnSigGrpChks : 7|8@0+ (1,0) [0|255] ""  ADD
 SG_ BcsAdsFcnSigGrpCntr : 11|4@0+ (1,0) [0|15] ""  ADD
 SG_ BCSBrkTqActForADS : 23|16@0+ (1,-30000) [-30000|0] ""  ADD
 SG_ BCSBrkTqReqADSDominantForADS : 55|1@0+ (1,0) [0|1] ""  ADD
 SG_ BCSTqActrActvForADS : 54|3@0+ (1,0) [0|7] ""  ADD
 SG_ BCSTqDrvReqBrkForADS : 39|16@0+ (1,0) [0|30000] ""  ADD
 SG_ BCSTqHumanActrAvlStsForADS : 63|2@0+ (1,0) [0|3] ""  ADD
 SG_ BCSTqL3ActrAvlStsForADS : 61|2@0+ (1,0) [0|3] ""  ADD
 SG_ BCSTqUnmannedActrAvlStsForADS : 59|2@0+ (1,0) [0|3] ""  ADD

BO_ 579 BMDM_ChassisCANFD_0x243: 8 Vector__XXX
 SG_ BattSocRaw : 49|10@0+ (0.1,0) [0|102.3] "%"  ADD
 SG_ BattSocRawSigGrpChks : 39|8@0+ (1,0) [0|255] ""  ADD
 SG_ BattSocRawSigGrpCntr : 43|4@0+ (1,0) [0|15] ""  ADD
 SG_ BattURaw : 23|15@0+ (0.001,0) [0|18] "V"  ADD
 SG_ BattURawSigGrpChks : 7|8@0+ (1,0) [0|255] ""  ADD
 SG_ BattURawSigGrpCntr : 11|4@0+ (1,0) [0|15] ""  ADD

BO_ 353 EPS_ChassisCANFD_0x161: 16 Vector__XXX
 SG_ AVPHPPCtrlAvlSts : 83|2@0+ (1,0) [0|3] ""  ADD
 SG_ AVPHPPCtrSts : 76|1@0+ (1,0) [0|1] ""  ADD
 SG_ AVPHPPReqFbSts : 79|3@0+ (1,0) [0|7] ""  ADD
 SG_ AVPHPPReqFltSts : 87|4@0+ (1,0) [0|15] ""  ADD
 SG_ DSTReqCtrlSts : 23|3@0+ (1,0) [0|7] ""  ADD
 SG_ EPSAVPHPPCtrlStsSigGrpChks : 71|8@0+ (1,0) [0|255] ""  ADD
 SG_ EPSAVPHPPCtrlStsSigGrpCntr : 75|4@0+ (1,0) [0|15] ""  ADD
 SG_ FailrSts : 15|3@0+ (1,0) [0|7] ""  ADD
 SG_ FailrStsSigGrpChks : 7|8@0+ (1,0) [0|255] ""  ADD
 SG_ FailrStsSigGrpCntr : 11|4@0+ (1,0) [0|15] ""  ADD
 SG_ HODQly : 31|8@0+ (1,0) [0|100] "%"  ADD
 SG_ HODSts : 20|2@0+ (1,0) [0|3] ""  ADD
 SG_ HODVld : 18|1@0+ (1,0) [0|1] ""  ADD
 SG_ PASReqFbSts : 55|3@0+ (1,0) [0|7] ""  ADD
 SG_ PASReqFltSts : 52|4@0+ (1,0) [0|15] ""  ADD
 SG_ PasReqSigGrpChks : 39|8@0+ (1,0) [0|255] ""  ADD
 SG_ PasReqSigGrpCntr : 43|4@0+ (1,0) [0|15] ""  ADD

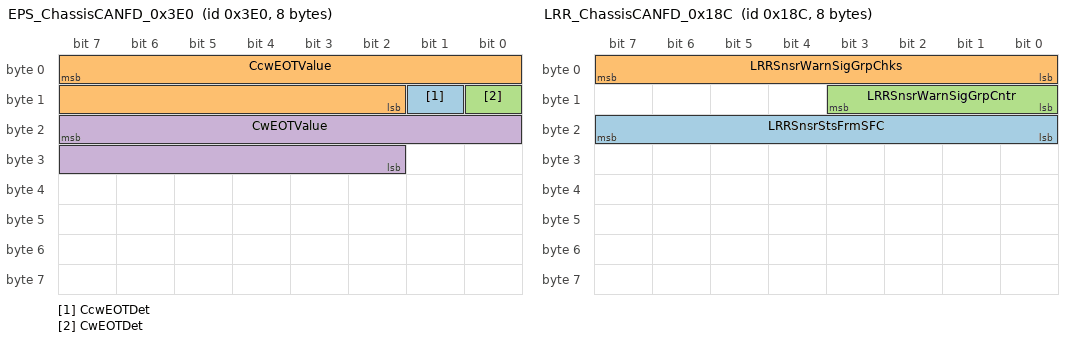
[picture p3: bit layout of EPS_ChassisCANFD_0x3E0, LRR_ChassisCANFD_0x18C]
BO_ 992 EPS_ChassisCANFD_0x3E0: 8 Vector__XXX
 SG_ CcwEOTDet : 9|1@0+ (1,0) [0|1] ""  ADD
 SG_ CcwEOTValue : 7|14@0+ (0.0625,0) [0|780] "deg"  ADD
 SG_ CwEOTDet : 8|1@0+ (1,0) [0|1] ""  ADD
 SG_ CwEOTValue : 23|14@0+ (0.0625,-780) [-780|0] ""  ADD

BO_ 181 EPS_ChassisCANFD_0xB5: 32 Vector__XXX
 SG_ AdasReqCtrlADDSigGrpChks : 39|8@0+ (1,0) [0|255] ""  ADD
 SG_ AdasReqCtrlADDSigGrpCntr : 43|4@0+ (1,0) [0|15] ""  ADD
 SG_ ADASReqFbStsADD : 50|3@0+ (1,0) [0|7] ""  ADD
 SG_ ADASReqFltStsADD : 53|3@0+ (1,0) [0|7] ""  ADD
 SG_ ADASReqOvlySteerWhlTqADD : 63|11@0- (0.01,0) [-10.24|10.23] "Nm"  ADD
 SG_ ADASReqOvlyTqADD : 79|14@0- (0.00390625,0) [-30|30] "Nm"  ADD
 SG_ DrvrSteerActvADD : 55|1@0+ (1,0) [0|1] ""  ADD
 SG_ PinionAglSpdV2C : 199|12@0- (1,0) [-2048|2047] "deg/s"  ADD
 SG_ PinionSteerAgl : 151|15@0- (0.0625,0) [-780|780] "��(deg)"  ADD
 SG_ PinionSteerAglSpd : 183|12@0- (1,0) [-2048|2047] "deg/s"  ADD
 SG_ PinionSteerAglSpdVld : 187|1@0+ (1,0) [0|1] ""  ADD
 SG_ PinionSteerAglSpdVldV2C : 186|1@0+ (1,0) [0|1] ""  ADD
 SG_ PinionSteerAglV2C : 215|15@0- (0.0625,0) [-780|780] "�㣨deg��"  ADD
 SG_ PinionSteerAglVld : 152|1@0+ (1,0) [0|1] ""  ADD
 SG_ PinionSteerAglVldV2C : 185|1@0+ (1,0) [0|1] ""  ADD
 SG_ PinionSteerSigGrpChks : 135|8@0+ (1,0) [0|255] ""  ADD
 SG_ PinionSteerSigGrpCntr : 139|4@0+ (1,0) [0|15] ""  ADD
 SG_ SteerWhlTq : 167|11@0- (0.01,0) [-10.24|10.23] "Nm"  ADD
 SG_ SteerWhlTqVld : 172|1@0+ (1,0) [0|1] ""  ADD
 SG_ SteerWhlVibStsADD : 54|1@0+ (1,0) [0|1] ""  ADD

BO_ 343 FZCU_ChassisCANFD_0x157: 24 Vector__XXX
 SG_ SpclRoadSurfTypSigGrpChks : 7|8@0+ (1,0) [0|255] ""  ADD
 SG_ SpclRoadSurfTypSigGrpCntr : 11|4@0+ (1,0) [0|15] ""  ADD
 SG_ VCUGearChgFailrSts : 167|1@0+ (1,0) [0|1] ""  ADD
 SG_ VCULatSlopForDisp : 31|12@0+ (0.1,-45) [-45|45] "deg"  ADD
 SG_ VCULgtSlopForDisp : 35|12@0+ (0.1,-45) [-45|45] "deg"  ADD
 SG_ VCUSpclRoadSurfTypForDisp : 23|4@0+ (1,0) [0|15] ""  ADD

BO_ 481 FZCU_ChassisCANFD_0x1E1: 24 Vector__XXX
 SG_ DvrSpclOpratIndForADD : 47|8@0+ (1,0) [0|10] ""  ADD
 SG_ LVPwrSplyBattErrSts : 71|1@0+ (1,0) [0|1] ""  ADD
 SG_ LVPwrSplyBattErrStsSigGrpChks : 55|8@0+ (1,0) [0|255] ""  ADD
 SG_ LVPwrSplyBattErrStsSigGrpCntr : 59|4@0+ (1,0) [0|15] ""  ADD
 SG_ LVPwrSplyDCDCErrSts : 182|1@0+ (1,0) [0|1] ""  ADD
 SG_ LVPwrSplyHiErrSts : 183|1@0+ (1,0) [0|1] ""  ADD
 SG_ LVPwrSplyHiErrStsSigGrpChks : 167|8@0+ (1,0) [0|255] ""  ADD
 SG_ LVPwrSplyHiErrStsSigGrpCntr : 171|4@0+ (1,0) [0|15] ""  ADD
 SG_ LVPwrSplyLoErrSts : 159|1@0+ (1,0) [0|1] ""  ADD
 SG_ LVPwrSplyLoErrStsSigGrpChks : 151|8@0+ (1,0) [0|255] ""  ADD
 SG_ LVPwrSplyLoErrStsSigGrpCntr : 155|4@0+ (1,0) [0|15] ""  ADD
 SG_ VCUAccrPrmSetAllwd : 23|1@0+ (1,0) [0|1] ""  ADD
 SG_ VCUBatModAllwd : 31|1@0+ (1,0) [0|1] ""  ADD
 SG_ VCUDriftModSetSts : 99|1@0+ (1,0) [0|1] ""  ADD
 SG_ VCUDrvModRgnPrmSts : 22|7@0+ (1,1) [1|100] ""  ADD
 SG_ VCUDrvModStSts : 98|1@0+ (1,0) [0|1] ""  ADD
 SG_ VCUExtmECOModStReq : 30|1@0+ (1,0) [0|1] ""  ADD
 SG_ VCULnchPlusSts : 97|2@0+ (1,0) [0|2] ""  ADD
 SG_ VCURgnPrmSetAllwd : 29|1@0+ (1,0) [0|1] ""  ADD
 SG_ VCUSteerAsstPrmSetAllwd : 28|1@0+ (1,0) [0|1] ""  ADD
 SG_ VCUSuspDampgPrmSetAllwd : 27|1@0+ (1,0) [0|1] ""  ADD
 SG_ VCUSuspLvlgPrm1Allwd : 26|1@0+ (1,0) [0|1] ""  ADD
 SG_ VCUSuspLvlgPrm2Allwd : 25|1@0+ (1,0) [0|1] ""  ADD
 SG_ VCUSuspLvlgPrm3Allwd : 24|1@0+ (1,0) [0|1] ""  ADD
 SG_ VCUSuspLvlgPrm4Allwd : 39|1@0+ (1,0) [0|1] ""  ADD
 SG_ VCUSuspLvlgPrm5Allwd : 38|1@0+ (1,0) [0|1] ""  ADD
 SG_ VCUWashModEntryAllwd : 37|1@0+ (1,0) [0|1] ""  ADD
 SG_ VCUWashModExtAllwd : 36|1@0+ (1,0) [0|1] ""  ADD

BO_ 514 FZCU_ChassisCANFD_0x202: 16 Vector__XXX
 SG_ StsOfIndcr : 34|3@0+ (1,0) [0|7] ""  ADD
 SG_ SwtIndcr : 13|3@0+ (1,0) [0|7] ""  ADD
 SG_ SwtIndcrSts : 10|3@0+ (1,0) [0|7] ""  ADD

BO_ 547 FZCU_ChassisCANFD_0x223: 64 Vector__XXX
 SG_ ExtrLtgStsHiBeam : 404|2@0+ (1,0) [0|3] ""  ADD
 SG_ ExtrLtgStsLoBeam : 413|2@0+ (1,0) [0|3] ""  ADD
 SG_ ExtrLtgStsStop : 402|2@0+ (1,0) [0|3] ""  ADD
 SG_ ExtrLtgStsTurnIndrLe : 415|2@0+ (1,0) [0|3] ""  ADD
 SG_ ExtrLtgStsTurnIndrRi : 411|2@0+ (1,0) [0|3] ""  ADD
 SG_ VCUSpdLimrSts : 110|1@0+ (1,0) [0|1] ""  ADD
 SG_ VCUSpdLimrValSts : 104|9@0+ (1,0) [0|510] "km/h"  ADD

BO_ 724 FZCU_ChassisCANFD_0x2D4: 32 Vector__XXX
 SG_ VCUChrgnModSts : 99|4@0+ (1,0) [0|15] ""  ADD
 SG_ VCUHVExtPortConnectnTypInfo : 119|4@0+ (1,0) [0|15] ""  ADD

BO_ 144 FZCU_ChassisCANFD_0x90: 24 Vector__XXX
 SG_ CarModSts : 126|3@0+ (1,0) [0|7] ""  ADD
 SG_ DrvActvSts : 29|1@0+ (1,0) [0|1] ""  ADD
 SG_ PwrModSigGrpChks : 7|8@0+ (1,0) [0|255] ""  ADD
 SG_ PwrModSigGrpCntr : 11|4@0+ (1,0) [0|15] ""  ADD
 SG_ PwrModSts : 23|3@0+ (1,0) [0|7] ""  ADD
 SG_ PwrModVld : 20|1@0+ (1,0) [0|1] ""  ADD
 SG_ VCUAccrPedlRat : 87|15@0+ (0.004,0) [0|100] "pct"  ADD
 SG_ VCUAccrPedlRatVld : 111|1@0+ (1,0) [0|1] ""  ADD
 SG_ VCUActDrvMod : 123|4@0+ (1,0) [0|15] ""  ADD
 SG_ VCUActGearLvr : 55|3@0+ (1,0) [0|7] ""  ADD
 SG_ VCUActGearLvrVld : 52|1@0+ (1,0) [0|1] ""  ADD
 SG_ VCUActGearSigGrpChks : 47|8@0+ (1,0) [0|255] ""  ADD
 SG_ VCUActGearSigGrpCntr : 51|4@0+ (1,0) [0|15] ""  ADD
 SG_ VCUDrvOffFcnLim : 119|1@0+ (1,0) [0|1] ""  ADD
 SG_ VCUFrntEmTqRdy : 110|1@0+ (1,0) [0|1] ""  ADD
 SG_ VCUGearLvrAvail : 118|1@0+ (1,0) [0|1] ""  ADD
 SG_ VcuInpSigGrpChks : 63|8@0+ (1,0) [0|255] ""  ADD
 SG_ VcuInpSigGrpCntr : 67|4@0+ (1,0) [0|15] ""  ADD
 SG_ VCUPrkgBtnPsd : 88|1@0+ (1,0) [0|1] ""  ADD
 SG_ VCUPtRdyFlg : 127|1@0+ (1,0) [0|1] ""  ADD
 SG_ VCUReEmTqRdy : 109|1@0+ (1,0) [0|1] ""  ADD
 SG_ VCURgnTqCorrnFac : 71|4@0+ (0.1,0) [0|1] ""  ADD
 SG_ VCUShifterMoveFlg : 104|1@0+ (1,0) [0|1] ""  ADD
 SG_ VCUStsModCst : 79|8@0+ (1,0) [0|255] ""  ADD
 SG_ VCUTarGearLvr : 108|3@0+ (1,0) [0|7] ""  ADD
 SG_ VCUTarGearLvrVld : 96|1@0+ (1,0) [0|1] ""  ADD
 SG_ VCUVirtAccrPedl : 103|7@0+ (1,0) [0|100] "%"  ADD
 SG_ VCUVirtAccrPedlVld : 105|1@0+ (1,0) [0|1] ""  ADD

BO_ 195 FZCU_ChassisCANFD_0xC3: 24 Vector__XXX
 SG_ ActiveOfADB : 55|1@0+ (1,0) [0|1] ""  ADD
 SG_ ActnOfDayRunngLampLe : 54|1@0+ (1,0) [0|1] ""  ADD
 SG_ ActnOfDayRunngLampRi : 64|1@0+ (1,0) [0|1] ""  ADD
 SG_ ActnOfLedFrntPosnLamp : 53|1@0+ (1,0) [0|1] ""  ADD
 SG_ ActnOfLedHiBeam : 52|1@0+ (1,0) [0|1] ""  ADD
 SG_ ActnOfParkLampLe : 44|1@0+ (1,0) [0|1] ""  ADD
 SG_ ActnOfParkLampRi : 45|1@0+ (1,0) [0|1] ""  ADD
 SG_ FarewellFuncSet : 56|1@0+ (1,0) [0|1] ""  ADD
 SG_ LampSigGrp2Chks : 39|8@0+ (1,0) [0|255] ""  ADD
 SG_ LampSigGrp2Cntr : 43|4@0+ (1,0) [0|15] ""  ADD
 SG_ SBLDmValSetLe : 63|7@0+ (1,0) [0|127] "%"  ADD
 SG_ SBLDmValSetRi : 71|7@0+ (1,0) [0|127] "%"  ADD
 SG_ SegmtDirCtrlSet : 51|4@0+ (1,0) [0|15] ""  ADD
 SG_ WelcomeFuncSet : 78|1@0+ (1,0) [0|1] ""  ADD
 SG_ WipSpdReqHi : 135|1@0+ (1,0) [0|1] ""  ADD
 SG_ WipSpdReqLo : 134|1@0+ (1,0) [0|1] ""  ADD
 SG_ WipSpdReqSigGrpChks : 127|8@0+ (1,0) [0|255] ""  ADD
 SG_ WipSpdReqSigGrpCntr : 131|4@0+ (1,0) [0|15] ""  ADD

BO_ 198 FZCU_ChassisCANFD_0xC6: 32 Vector__XXX
 SG_ VCUAccrPedlFlg : 34|1@0+ (1,0) [0|1] ""  ADD
 SG_ VCUAccrPedlRatGrdt : 7|15@0- (0.0625,0) [-1000|1000] ""  ADD
 SG_ VCUADASDrvrWhlTqReq : 215|16@0+ (1,-30000) [-30000|30000] "Nm"  ADD
 SG_ VCUADASTorqueAvailableSt : 207|1@0+ (1,0) [0|1] ""  ADD
 SG_ VCUADASTqModeFeedback : 206|3@0+ (1,0) [0|7] ""  ADD
 SG_ VCUAlwParkRels : 33|1@0+ (1,0) [0|1] ""  ADD
 SG_ VCUCstFlg : 105|1@0+ (1,0) [0|1] ""  ADD
 SG_ VCUCstRgnTqReq : 103|14@0+ (1,-16383) [-16383|0] "Nm"  ADD
 SG_ VCUCstRgnTqReqFA : 119|14@0+ (1,-16383) [-16383|0] "Nm"  ADD
 SG_ VCUCstRgnTqReqRA : 135|14@0+ (1,-16383) [-16383|0] ""  ADD
 SG_ VcuEgyMonSigGrpChks : 71|8@0+ (1,0) [0|255] ""  ADD
 SG_ VcuEgyMonSigGrpCntr : 75|4@0+ (1,0) [0|15] ""  ADD
 SG_ VCUHVSt : 47|3@0+ (1,0) [0|7] ""  ADD
 SG_ VCUHydTqReq : 87|14@0+ (1,-16383) [-16383|0] "Nm"  ADD
 SG_ VCUHydTqReqVld : 89|1@0+ (1,0) [0|1] ""  ADD
 SG_ VcuInp3SigGrpChks : 199|8@0+ (1,0) [0|255] ""  ADD
 SG_ VcuInp3SigGrpCntr : 203|4@0+ (1,0) [0|15] ""  ADD
 SG_ VCULoSocLampReq : 44|1@0+ (1,0) [0|1] ""  ADD
 SG_ VCUMaxRgnTqAvl : 151|14@0+ (1,-16383) [-16383|0] "Nm"  ADD
 SG_ VCUMaxRgnTqAvlFA : 167|14@0+ (1,-16383) [-16383|0] "Nm"  ADD
 SG_ VCUMaxRgnTqAvlFAVld : 169|1@0+ (1,0) [0|1] ""  ADD
 SG_ VCUMaxRgnTqAvlRA : 183|14@0+ (1,-16383) [-16383|0] "Nm"  ADD
 SG_ VCUMaxRgnTqAvlRAVld : 185|1@0+ (1,0) [0|1] ""  ADD
 SG_ VCUMaxRgnTqAvlVld : 184|1@0+ (1,0) [0|1] ""  ADD
 SG_ VCUPedlTqOvrdAdsFlg : 43|1@0+ (1,0) [0|1] ""  ADD
 SG_ VCUPrkgBtnPsdVld : 229|1@0+ (1,0) [0|1] ""  ADD
 SG_ VCUVehMaxFltLvl : 42|3@0+ (1,0) [0|4] ""  ADD
 SG_ WiprSpdModSts : 55|6@0+ (1,0) [0|63] ""  ADD

BO_ 396 LRR_ChassisCANFD_0x18C: 8 Vector__XXX
 SG_ LRRSnsrStsFrmSFC : 23|8@0+ (1,0) [0|255] ""  ADD
 SG_ LRRSnsrWarnSigGrpChks : 7|8@0+ (1,0) [0|255] ""  ADD
 SG_ LRRSnsrWarnSigGrpCntr : 11|4@0+ (1,0) [0|15] ""  ADD

BO_ 434 LZCU_ChassisCANFD_0x1B2: 32 Vector__XXX
 SG_ DoorDrvrOutPwrRelsBtnSts : 125|2@0+ (1,0) [0|3] ""  ADD
 SG_ DoorDrvrPwrRelsDlyActv : 199|2@0+ (1,0) [0|3] ""  ADD
 SG_ DoorDrvrPwrRelsMotDrvSts : 255|3@0+ (1,0) [0|7] ""  ADD
 SG_ DoorDrvrSts : 197|2@0+ (1,0) [0|3] ""  ADD
 SG_ DoorLeReOutPwrRelsBtnSts : 123|2@0+ (1,0) [0|3] ""  ADD
 SG_ DoorLeRePwrRelsDlyActv : 207|2@0+ (1,0) [0|3] ""  ADD
 SG_ DoorLeReSts : 205|2@0+ (1,0) [0|3] ""  ADD
 SG_ ExtrMirrFoldEnaFailr : 215|4@0+ (1,0) [0|15] ""  ADD
 SG_ ExtrMirrFoldSts : 211|3@0+ (1,0) [0|7] ""  ADD
 SG_ LeMirrFoldCmd : 115|2@0+ (1,0) [0|3] ""  ADD
 SG_ PwrRelsMotDrvStsGrpChks : 247|8@0+ (1,0) [0|255] ""  ADD
 SG_ PwrRelsMotDrvStsGrpCntr : 251|4@0+ (1,0) [0|15] ""  ADD
 SG_ SwsLinComFltSts : 47|1@0+ (1,0) [0|1] ""  ADD

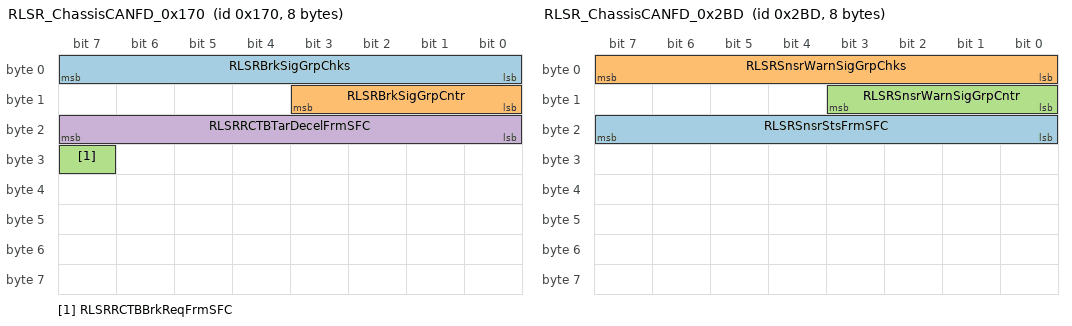
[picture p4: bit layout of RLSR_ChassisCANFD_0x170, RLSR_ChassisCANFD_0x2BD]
BO_ 368 RLSR_ChassisCANFD_0x170: 8 Vector__XXX
 SG_ RLSRBrkSigGrpChks : 7|8@0+ (1,0) [0|255] ""  ADD
 SG_ RLSRBrkSigGrpCntr : 11|4@0+ (1,0) [0|15] ""  ADD
 SG_ RLSRRCTBBrkReqFrmSFC : 31|1@0+ (1,0) [0|1] ""  ADD
 SG_ RLSRRCTBTarDecelFrmSFC : 23|8@0+ (0.05,-10) [-10|2.75] "mps2"  ADD

BO_ 391 RLSR_ChassisCANFD_0x187: 16 Vector__XXX
 SG_ RLSRBSDLCAStsFrmSFC : 21|2@0+ (1,0) [0|3] ""  ADD
 SG_ RLSRBSDLCASwtFbFrmSFC : 34|3@0+ (1,0) [0|4] ""  ADD
 SG_ RLSRBSDLCASwtUnavlRsnFrmSFC : 55|4@0+ (1,0) [0|11] ""  ADD
 SG_ RLSRBSDLCAWarnReqFrmSFC : 23|2@0+ (1,0) [0|3] ""  ADD
 SG_ RLSRDOWStsFrmSFC : 17|2@0+ (1,0) [0|3] ""  ADD
 SG_ RLSRDOWSwtFbFrmSFC : 46|3@0+ (1,0) [0|4] ""  ADD
 SG_ RLSRDOWSwtUnavlRsnFrmSFC : 51|4@0+ (1,0) [0|11] ""  ADD
 SG_ RLSRDOWWarnReqFrFrmSFC : 19|2@0+ (1,0) [0|3] ""  ADD
 SG_ RLSRDOWWarnReqReFrmSFC : 31|2@0+ (1,0) [0|3] ""  ADD
 SG_ RLSRRCTABSwtFbFrmSFC : 37|3@0+ (1,0) [0|4] ""  ADD
 SG_ RLSRRCTABSwtUnavlRsnFrmSFC : 63|4@0+ (1,0) [0|11] ""  ADD
 SG_ RLSRRCTAStsFrmSFC : 13|2@0+ (1,0) [0|3] ""  ADD
 SG_ RLSRRCTAWarnReqFrmSFC : 15|2@0+ (1,0) [0|3] ""  ADD
 SG_ RLSRRCTBStsFrmSFC : 29|2@0+ (1,0) [0|3] ""  ADD
 SG_ RLSRRCTBWarnReqFrmSFC : 43|2@0+ (1,0) [0|3] ""  ADD
 SG_ RLSRRCWStsFrmSFC : 25|2@0+ (1,0) [0|3] ""  ADD
 SG_ RLSRRCWSwtFbFrmSFC : 41|2@0+ (1,0) [0|3] ""  ADD
 SG_ RLSRRCWSwtUnavlRsnFrmSFC : 59|4@0+ (1,0) [0|11] ""  ADD
 SG_ RLSRRCWWarnReqFrmSFC : 27|2@0+ (1,0) [0|3] ""  ADD
 SG_ RLSRWarnSigGrpChks : 7|8@0+ (1,0) [0|255] ""  ADD
 SG_ RLSRWarnSigGrpCntr : 11|4@0+ (1,0) [0|15] ""  ADD

BO_ 701 RLSR_ChassisCANFD_0x2BD: 8 Vector__XXX
 SG_ RLSRSnsrStsFrmSFC : 23|8@0+ (1,0) [0|255] ""  ADD
 SG_ RLSRSnsrWarnSigGrpChks : 7|8@0+ (1,0) [0|255] ""  ADD
 SG_ RLSRSnsrWarnSigGrpCntr : 11|4@0+ (1,0) [0|15] ""  ADD

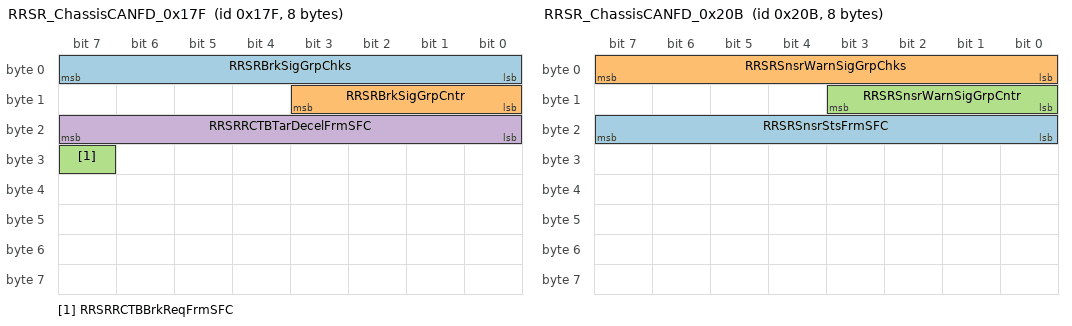
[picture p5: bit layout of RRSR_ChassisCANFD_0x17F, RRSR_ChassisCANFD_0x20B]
BO_ 383 RRSR_ChassisCANFD_0x17F: 8 Vector__XXX
 SG_ RRSRBrkSigGrpChks : 7|8@0+ (1,0) [0|255] ""  ADD
 SG_ RRSRBrkSigGrpCntr : 11|4@0+ (1,0) [0|15] ""  ADD
 SG_ RRSRRCTBBrkReqFrmSFC : 31|1@0+ (1,0) [0|1] ""  ADD
 SG_ RRSRRCTBTarDecelFrmSFC : 23|8@0+ (0.05,-10) [-10|2.75] "mps2"  ADD

BO_ 392 RRSR_ChassisCANFD_0x188: 16 Vector__XXX
 SG_ RRSRBSDLCAStsFrmSFC : 21|2@0+ (1,0) [0|3] ""  ADD
 SG_ RRSRBSDLCASwtFbFrmSFC : 34|3@0+ (1,0) [0|4] ""  ADD
 SG_ RRSRBSDLCASwtUnavlRsnFrmSFC : 55|4@0+ (1,0) [0|11] ""  ADD
 SG_ RRSRBSDLCAWarnReqFrmSFC : 23|2@0+ (1,0) [0|3] ""  ADD
 SG_ RRSRDOWStsFrmSFC : 17|2@0+ (1,0) [0|3] ""  ADD
 SG_ RRSRDOWSwtFbFrmSFC : 46|3@0+ (1,0) [0|4] ""  ADD
 SG_ RRSRDOWSwtUnavlRsnFrmSFC : 51|4@0+ (1,0) [0|11] ""  ADD
 SG_ RRSRDOWWarnReqFrFrmSFC : 19|2@0+ (1,0) [0|3] ""  ADD
 SG_ RRSRDOWWarnReqReFrmSFC : 31|2@0+ (1,0) [0|3] ""  ADD
 SG_ RRSRRCTABSwtFbFrmSFC : 37|3@0+ (1,0) [0|4] ""  ADD
 SG_ RRSRRCTABSwtUnavlRsnFrmSFC : 63|4@0+ (1,0) [0|11] ""  ADD
 SG_ RRSRRCTAStsFrmSFC : 13|2@0+ (1,0) [0|3] ""  ADD
 SG_ RRSRRCTAWarnReqFrmSFC : 15|2@0+ (1,0) [0|3] ""  ADD
 SG_ RRSRRCTBStsFrmSFC : 29|2@0+ (1,0) [0|3] ""  ADD
 SG_ RRSRRCTBWarnReqFrmSFC : 43|2@0+ (1,0) [0|3] ""  ADD
 SG_ RRSRRCWStsFrmSFC : 25|2@0+ (1,0) [0|3] ""  ADD
 SG_ RRSRRCWSwtFbFrmSFC : 41|2@0+ (1,0) [0|3] ""  ADD
 SG_ RRSRRCWSwtUnavlRsnFrmSFC : 59|4@0+ (1,0) [0|11] ""  ADD
 SG_ RRSRRCWWarnReqFrmSFC : 27|2@0+ (1,0) [0|3] ""  ADD
 SG_ RRSRWarnSigGrpChks : 7|8@0+ (1,0) [0|255] ""  ADD
 SG_ RRSRWarnSigGrpCntr : 11|4@0+ (1,0) [0|15] ""  ADD

BO_ 523 RRSR_ChassisCANFD_0x20B: 8 Vector__XXX
 SG_ RRSRSnsrStsFrmSFC : 23|8@0+ (1,0) [0|255] ""  ADD
 SG_ RRSRSnsrWarnSigGrpChks : 7|8@0+ (1,0) [0|255] ""  ADD
 SG_ RRSRSnsrWarnSigGrpCntr : 11|4@0+ (1,0) [0|15] ""  ADD

BO_ 403 RZCU_ChassisCANFD_0x193: 24 Vector__XXX
 SG_ DoorRiRePwrRelsDlyActv : 15|2@0+ (1,0) [0|3] ""  ADD
 SG_ DoorRiReSts : 13|2@0+ (1,0) [0|3] ""  ADD
 SG_ RiMirrFoldCmd : 25|2@0+ (1,0) [0|3] ""  ADD

BO_ 502 RZCU_ChassisCANFD_0x1F6: 32 Vector__XXX
 SG_ DoorPassOutPwrRelsBtnSts : 124|2@0+ (1,0) [0|3] ""  ADD
 SG_ DoorPassPwrRelsDlyActv : 165|2@0+ (1,0) [0|3] ""  ADD
 SG_ DoorPassSts : 163|2@0+ (1,0) [0|3] ""  ADD
 SG_ DoorRiReOutPwrRelsBtnSts : 131|2@0+ (1,0) [0|3] ""  ADD

BO_ 602 RZCU_ChassisCANFD_0x25A: 16 Vector__XXX
 SG_ RlsFrntWinHum : 7|10@0+ (0.1,0) [0|100] "%"  ADD
 SG_ RlsFrntWinT : 23|11@0+ (0.1,-40) [-40|160] "degC"  ADD
 SG_ RlsRainFallAmnt : 39|4@0+ (1,0) [0|15] ""  ADD
 SG_ RlsRainFallSts : 35|4@0+ (1,0) [0|15] ""  ADD
 SG_ RlsRainSnsrFlt : 11|1@0+ (1,0) [0|1] ""  ADD
 SG_ RlsTHumSnsrFlt : 8|1@0+ (1,0) [0|1] ""  ADD

BO_ 182 SCU_ChassisCANFD_0xB6: 32 Vector__XXX
 SG_ CurHeiSigGrpChks : 7|8@0+ (1,0) [0|255] ""  ADD
 SG_ CurHeiSigGrpCntr : 11|4@0+ (1,0) [0|15] ""  ADD
 SG_ FrntLeCurHei : 23|8@0+ (1,-127) [-127|128] "mm"  ADD
 SG_ FrntLeCurHeiSts : 15|1@0+ (1,0) [0|1] ""  ADD
 SG_ FrntRiCurHei : 39|8@0+ (1,-127) [-127|128] "mm"  ADD
 SG_ FrntRiCurHeiSts : 13|1@0+ (1,0) [0|1] ""  ADD
 SG_ ReLeCurHei : 31|8@0+ (1,-127) [-127|128] "mm"  ADD
 SG_ ReLeCurHeiSts : 14|1@0+ (1,0) [0|1] ""  ADD
 SG_ ReRiCurHei : 47|8@0+ (1,-127) [-127|128] "mm"  ADD
 SG_ ReRiCurHeiSts : 12|1@0+ (1,0) [0|1] ""  ADD

BO_ 419 SWM_ChassisCANFD_0x1A3: 16 Vector__XXX
 SG_ SwtIndcrRaw : 42|3@0+ (1,0) [0|7] ""  ADD
 SG_ SwtIndcrRawSigGrpChks : 31|8@0+ (1,0) [0|255] ""  ADD
 SG_ SwtIndcrRawSigGrpCntr : 35|4@0+ (1,0) [0|15] ""  ADD

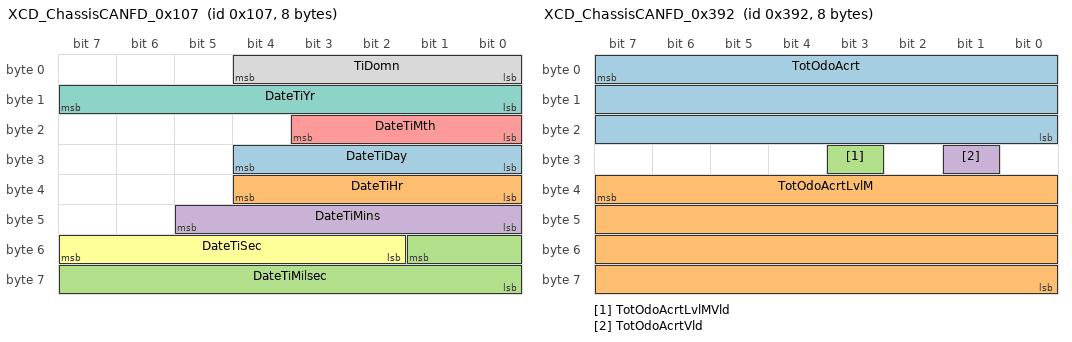
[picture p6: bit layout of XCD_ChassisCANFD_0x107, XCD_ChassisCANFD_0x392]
BO_ 263 XCD_ChassisCANFD_0x107: 8 Vector__XXX
 SG_ DateTiDay : 28|5@0+ (1,0) [0|31] ""  ADD
 SG_ DateTiHr : 36|5@0+ (1,0) [0|24] "hour"  ADD
 SG_ DateTiMilsec : 49|10@0+ (1,0) [0|1000] "Msec"  ADD
 SG_ DateTiMins : 45|6@0+ (1,0) [0|59] "minute"  ADD
 SG_ DateTiMth : 19|4@0+ (1,0) [0|12] ""  ADD
 SG_ DateTiSec : 55|6@0+ (1,0) [0|59] "second"  ADD
 SG_ DateTiYr : 15|8@0+ (1,2000) [2000|2254] "year"  ADD
 SG_ TiDomn : 4|5@0+ (1,0) [0|31] ""  ADD

BO_ 582 XCD_ChassisCANFD_0x246: 8 Vector__XXX
 SG_ DCDSteerWhlExtrMirrHUDAdjFlg : 5|3@0+ (1,0) [0|7] ""  ADD
 SG_ OTAMode : 7|1@0+ (1,0) [0|1] ""  ADD

BO_ 720 XCD_ChassisCANFD_0x2D0: 24 Vector__XXX
 SG_ DCDAvmCamTrigMod : 59|2@0+ (1,0) [0|3] ""  ADD
 SG_ DCDDMSCameraFltSts : 104|1@0+ (1,0) [0|1] ""  ADD
 SG_ DCDDMSdstrctnDetnSts : 60|1@0+ (1,0) [0|1] ""  ADD
 SG_ DCDDMSdstrctnSts : 106|2@0+ (1,0) [0|3] ""  ADD
 SG_ DCDDMSFatgDetnSts : 61|1@0+ (1,0) [0|1] ""  ADD
 SG_ DCDDMSfatgSts : 108|2@0+ (1,0) [0|3] ""  ADD
 SG_ DCDDMSSigGrpChks : 95|8@0+ (1,0) [0|255] ""  ADD
 SG_ DCDDMSSigGrpCntr : 99|4@0+ (1,0) [0|15] ""  ADD
 SG_ DCDDMSSysFltSts : 109|1@0+ (1,0) [0|1] ""  ADD
 SG_ DCDDVRSrvReq : 62|1@0+ (1,0) [0|1] ""  ADD
 SG_ DCDGameModSts : 121|1@0+ (1,0) [0|1] ""  ADD
 SG_ DCDPrivacyModeStatus : 57|2@0+ (1,0) [0|3] ""  ADD
 SG_ DCDsentryModReq : 67|1@0+ (1,0) [0|1] ""  ADD
 SG_ DCDsentryModSts : 71|3@0+ (1,0) [0|7] ""  ADD
 SG_ DCDTSASLIFSwtSts : 135|2@0+ (1,0) [0|3] ""  ADD
 SG_ DCDVehRunningTiAftLstChrgn : 159|32@0+ (0.1,0) [0|429496729.5] "s"  ADD
 SG_ OTALinkMgr : 1|1@0+ (1,0) [0|1] ""  ADD
 SG_ SRMode : 116|2@0+ (1,0) [0|3] ""  ADD
 SG_ VehRunngTiAftRdy : 23|32@0+ (0.1,0) [0|429496729.5] "s"  ADD

BO_ 833 XCD_ChassisCANFD_0x341: 32 Vector__XXX
 SG_ ALCLrnSts : 239|1@0+ (1,0) [0|1] ""  ADD
 SG_ AVPLrnSts : 237|1@0+ (1,0) [0|1] ""  ADD
 SG_ DCDAdCode : 147|20@0+ (1,0) [0|1048575] ""  ADD
 SG_ DCDCameraSpdLim : 175|8@0+ (1,0) [0|255] ""  ADD
 SG_ DCDNavSts : 177|2@0+ (1,0) [0|3] ""  ADD
 SG_ DCDRoadClass : 181|4@0+ (1,0) [0|15] ""  ADD
 SG_ DCDRoadFacSpdLim : 191|8@0+ (1,0) [0|255] ""  ADD
 SG_ DCDRoadType : 197|6@0+ (1,0) [0|63] ""  ADD
 SG_ DCDTrfcSts : 203|4@0+ (1,0) [0|15] ""  ADD
 SG_ DCDTSASlifSpdDisp : 0|9@0+ (1,0) [0|511] ""  ADD
 SG_ DstUnitDisp : 84|1@0+ (1,0) [0|1] ""  ADD
 SG_ HPPLrnSts : 236|1@0+ (1,0) [0|1] ""  ADD
 SG_ LrnStsSigGrpChks : 223|8@0+ (1,0) [0|255] ""  ADD
 SG_ LrnStsSigGrpCntr : 227|4@0+ (1,0) [0|15] ""  ADD
 SG_ NOACtyLrnSts : 235|1@0+ (1,0) [0|1] ""  ADD
 SG_ NOAHWLrnSts : 234|1@0+ (1,0) [0|1] ""  ADD
 SG_ PltLrnSts : 233|1@0+ (1,0) [0|1] ""  ADD
 SG_ VehInsSpdDisp : 40|9@0+ (1,0) [0|504] "kph"  ADD
 SG_ VehInsSpdDispIntnal : 63|16@0+ (0.05625,0) [0|504] "kph"  ADD
 SG_ VehInsSpdDispVld : 4|1@0+ (1,0) [0|1] ""  ADD

BO_ 837 XCD_ChassisCANFD_0x345: 32 Vector__XXX
 SG_ DCDAcctMod : 48|1@0+ (1,0) [0|1] ""  ADD
 SG_ DCDCloudSysnc : 51|1@0+ (1,0) [0|1] ""  ADD
 SG_ DCDGstMod : 13|2@0+ (1,0) [0|3] ""  ADD
 SG_ DCDICVehCustExperImprvProgSts : 11|2@0+ (1,0) [0|3] ""  ADD
 SG_ DCDICVehSrvAuthntSts : 9|2@0+ (1,0) [0|3] ""  ADD
 SG_ DCDUserIDBytePos0 : 183|8@0+ (1,0) [0|255] ""  ADD
 SG_ DCDUserIDBytePos1 : 175|8@0+ (1,0) [0|255] ""  ADD
 SG_ DCDUserIDBytePos10 : 103|8@0+ (1,0) [0|255] ""  ADD
 SG_ DCDUserIDBytePos11 : 95|8@0+ (1,0) [0|255] ""  ADD
 SG_ DCDUserIDBytePos12 : 87|8@0+ (1,0) [0|255] ""  ADD
 SG_ DCDUserIDBytePos13 : 79|8@0+ (1,0) [0|255] ""  ADD
 SG_ DCDUserIDBytePos14 : 71|8@0+ (1,0) [0|255] ""  ADD
 SG_ DCDUserIDBytePos15 : 63|8@0+ (1,0) [0|255] ""  ADD
 SG_ DCDUserIDBytePos2 : 167|8@0+ (1,0) [0|255] ""  ADD
 SG_ DCDUserIDBytePos3 : 159|8@0+ (1,0) [0|255] ""  ADD
 SG_ DCDUserIDBytePos4 : 151|8@0+ (1,0) [0|255] ""  ADD
 SG_ DCDUserIDBytePos5 : 143|8@0+ (1,0) [0|255] ""  ADD
 SG_ DCDUserIDBytePos6 : 135|8@0+ (1,0) [0|255] ""  ADD
 SG_ DCDUserIDBytePos7 : 127|8@0+ (1,0) [0|255] ""  ADD
 SG_ DCDUserIDBytePos8 : 119|8@0+ (1,0) [0|255] ""  ADD
 SG_ DCDUserIDBytePos9 : 111|8@0+ (1,0) [0|255] ""  ADD
 SG_ DCDUserIDSigGrpFV : 215|16@0+ (1,0) [0|65535] ""  ADD
 SG_ DCDUserIDSigGrpMAC : 231|32@0+ (1,0) [0|0] ""  ADD

BO_ 868 XCD_ChassisCANFD_0x364: 24 Vector__XXX
 SG_ SetMgrAdsACCInitSpdSwt : 127|3@0+ (1,0) [0|7] ""  ADD
 SG_ SetMgrAdsAEBFCWSwt : 124|3@0+ (1,0) [0|7] ""  ADD
 SG_ SetMgrAdsALCSwtSts : 135|3@0+ (1,0) [0|7] ""  ADD
 SG_ SetMgrAdsAPA2SwtSts : 183|3@0+ (1,0) [0|7] ""  ADD
 SG_ SetMgrAdsAudModSwt : 55|3@0+ (1,0) [0|7] ""  ADD
 SG_ SetMgrAdsAutoTurnLiSwt : 175|3@0+ (1,0) [0|7] ""  ADD
 SG_ SetMgrAdsAVPSwtSts : 52|3@0+ (1,0) [0|7] ""  ADD
 SG_ SetMgrAdsBSDLCASwt : 63|3@0+ (1,0) [0|7] ""  ADD
 SG_ SetMgrAdsCfgLoadReq : 132|3@0+ (1,0) [0|7] ""  ADD
 SG_ SetMgrAdsDOWSwt : 60|3@0+ (1,0) [0|7] ""  ADD
 SG_ SetMgrAdsELKSwSts : 140|3@0+ (1,0) [0|7] ""  ADD
 SG_ SetMgrAdsFxdSpdModValSwt : 71|7@0+ (1,0) [0|127] ""  ADD
 SG_ SetMgrAdsHPPBckGrLear : 79|3@0+ (1,0) [0|7] ""  ADD
 SG_ SetMgrAdsHPPSwtSts : 76|3@0+ (1,0) [0|7] ""  ADD
 SG_ SetMgrAdsIntelgntSpdSwt : 180|3@0+ (1,0) [0|7] ""  ADD
 SG_ SetMgrAdsLaneChgCnfmSwt : 87|3@0+ (1,0) [0|7] ""  ADD
 SG_ SetMgrAdsLDWPSwt : 84|3@0+ (1,0) [0|7] ""  ADD
 SG_ SetMgrAdsLDWPWarnTypSwt : 95|3@0+ (1,0) [0|7] ""  ADD
 SG_ SetMgrAdsMAISwtSts : 191|3@0+ (1,0) [0|7] ""  ADD
 SG_ SetMgrAdsModSwt : 159|3@0+ (1,0) [0|7] ""  ADD
 SG_ SetMgrAdsNOAHWSwtSts : 92|3@0+ (1,0) [0|7] ""  ADD
 SG_ SetMgrAdsNOAOddSwt : 156|3@0+ (1,0) [0|7] ""  ADD
 SG_ SetMgrAdsParkAudModSwt : 47|3@0+ (1,0) [0|7] ""  ADD
 SG_ SetMgrAdsParkSpdSwtSts : 172|3@0+ (1,0) [0|7] ""  ADD
 SG_ SetMgrAdsPcntgeSpdlvlSwt : 103|6@0+ (1,0) [0|34] ""  ADD
 SG_ SetMgrAdsPltSwtSts : 111|3@0+ (1,0) [0|7] ""  ADD
 SG_ SetMgrAdsPntCldSwt : 108|3@0+ (1,0) [0|7] ""  ADD
 SG_ SetMgrAdsRCTABSwt : 119|3@0+ (1,0) [0|7] ""  ADD
 SG_ SetMgrAdsRCWSwt : 116|3@0+ (1,0) [0|7] ""  ADD
 SG_ SetMgrAdsTLASwt : 147|3@0+ (1,0) [0|7] ""  ADD
 SG_ SetMgrAdsTrfcLiCtrlSwt : 167|3@0+ (1,0) [0|7] ""  ADD
 SG_ SetMgrAdsVehDetourSwt : 164|3@0+ (1,0) [0|7] ""  ADD
 SG_ SetMgrAdsVehSpdDvtnModSwt : 143|3@0+ (1,0) [0|7] ""  ADD
 SG_ SetMgrDrvrSeldDstLvl : 44|3@0+ (1,0) [0|7] ""  ADD

BO_ 914 XCD_ChassisCANFD_0x392: 8 Vector__XXX
 SG_ TotOdoAcrt : 7|24@0+ (0.1,0) [0|1677721.5] "km"  ADD
 SG_ TotOdoAcrtLvlM : 39|32@0+ (1,0) [0|4294967295] "m"  ADD
 SG_ TotOdoAcrtLvlMVld : 27|1@0+ (1,0) [0|1] ""  ADD
 SG_ TotOdoAcrtVld : 25|1@0+ (1,0) [0|1] ""  ADD

BO_ 932 XCD_ChassisCANFD_0x3A4: 32 Vector__XXX
 SG_ ADSAEBFCWSwtSet : 114|3@0+ (1,0) [0|7] ""  ADD
 SG_ ADSAESESSSwtSet : 33|2@0+ (1,0) [0|3] ""  ADD
 SG_ ADSAPPOpenReq : 132|2@0+ (1,0) [0|3] ""  ADD
 SG_ ADSBSDLCASwtSet : 39|3@0+ (1,0) [0|7] ""  ADD
 SG_ ADSDOWSwtSet : 41|2@0+ (1,0) [0|3] ""  ADD
 SG_ ADSPMAEBSwtSet : 35|2@0+ (1,0) [0|3] ""  ADD
 SG_ ADSRCWSwtSet : 47|2@0+ (1,0) [0|3] ""  ADD
 SG_ ADSTLASwtSet : 31|2@0+ (1,0) [0|3] ""  ADD
 SG_ ADSVcCtrlSwtSet : 5|2@0+ (1,0) [0|3] ""  ADD
 SG_ APASwtSet : 49|2@0+ (1,0) [0|3] ""  ADD
 SG_ AVPSwtSet : 45|2@0+ (1,0) [0|3] ""  ADD
 SG_ DCD2RDParkinChoseButton : 103|2@0+ (1,0) [0|3] ""  ADD
 SG_ DCDACCInitSpdSwtSet : 51|2@0+ (1,0) [0|3] ""  ADD
 SG_ DCDAdsAutoTurnLiSwtSet : 161|2@0+ (1,0) [0|3] ""  ADD
 SG_ DCDAdsIntelgntSpdSwtSet : 165|2@0+ (1,0) [0|2] ""  ADD
 SG_ DCDADSMAISwtSet : 57|2@0+ (1,0) [0|2] ""  ADD
 SG_ DCDAdsModSwtSet : 159|2@0+ (1,0) [0|3] ""  ADD
 SG_ DCDAdsNOAOddSwtSet : 157|2@0+ (1,0) [0|3] ""  ADD
 SG_ DCDADSRCTABSwtSet : 15|2@0+ (1,0) [0|3] ""  ADD
 SG_ DCDAdsTrfcLiCtrlSwtSet : 155|2@0+ (1,0) [0|3] ""  ADD
 SG_ DCDADSVcCtrlDstSet : 77|2@0+ (1,0) [0|3] ""  ADD
 SG_ DCDADSVcCtrlSpdSet : 75|2@0+ (1,0) [0|3] ""  ADD
 SG_ DCDAdsVehDeturSwtSet : 153|2@0+ (1,0) [0|3] ""  ADD
 SG_ DCDAPAButton : 101|2@0+ (1,0) [0|3] ""  ADD
 SG_ DCDAPAParkOutButton : 163|2@0+ (1,0) [0|3] ""  ADD
 SG_ DCDAPAParkOutDireSelect : 111|4@0+ (1,0) [0|15] ""  ADD
 SG_ DCDAPAParkSlotSelect : 119|5@0+ (1,0) [0|31] ""  ADD
 SG_ DCDAPAPIPOReq : 107|2@0+ (1,0) [0|3] ""  ADD
 SG_ DCDAPAQuitReq : 105|1@0+ (1,0) [0|1] ""  ADD
 SG_ DCDAPAVcCtl : 122|3@0+ (1,0) [0|7] ""  ADD
 SG_ DCDAudModSwtSet : 55|3@0+ (1,0) [0|7] ""  ADD
 SG_ DCDAutoVehCustExperImprvProgSwt : 23|2@0+ (1,0) [0|3] ""  ADD
 SG_ DCDAutoVehSrvAuthntSwt : 21|2@0+ (1,0) [0|3] ""  ADD
 SG_ DCDBackMapDfltParkSlotReq : 130|1@0+ (1,0) [0|1] ""  ADD
 SG_ DCDFxdSpdModValSwtSet : 29|6@0+ (1,0) [0|63] ""  ADD
 SG_ DCDHPPBckGrLearSwtSet : 59|2@0+ (1,0) [0|3] ""  ADD
 SG_ DCDHPPBckGrPathAutDoLoSet : 61|2@0+ (1,0) [0|3] ""  ADD
 SG_ DCDHPPChoseSaveRoute : 129|2@0+ (1,0) [0|3] ""  ADD
 SG_ DCDHPPLnVcReq : 71|2@0+ (1,0) [0|3] ""  ADD
 SG_ DCDHPPLrnReq : 135|3@0+ (1,0) [0|7] ""  ADD
 SG_ DCDHPPParkAlTheWay : 140|2@0+ (1,0) [0|3] ""  ADD
 SG_ DCDHPPParkingButton : 138|2@0+ (1,0) [0|3] ""  ADD
 SG_ DCDHPPPrkReq : 143|3@0+ (1,0) [0|7] ""  ADD
 SG_ DCDLdwLdpWarnTypSwtSet : 63|2@0+ (1,0) [0|3] ""  ADD
 SG_ DCDLVPwrSwtSet : 65|2@0+ (1,0) [0|3] ""  ADD
 SG_ DCDParkAudModSwtSet : 9|2@0+ (1,0) [0|3] ""  ADD
 SG_ DCDParkSpdSwtSet : 83|3@0+ (1,0) [0|6] ""  ADD
 SG_ DCDPcntgeSpdModValSwtSet : 127|5@0+ (1,0) [0|31] ""  ADD
 SG_ DCDPntCldSwtSet : 85|2@0+ (1,0) [0|3] ""  ADD
 SG_ DCDTouchdSpdTyp : 67|2@0+ (1,0) [0|3] ""  ADD
 SG_ HPPSwtSet : 43|2@0+ (1,0) [0|3] ""  ADD
 SG_ HwNOASwtSet : 13|2@0+ (1,0) [0|3] ""  ADD
 SG_ LdwLdpSwtSet : 19|2@0+ (1,0) [0|3] ""  ADD
 SG_ LidarCloudMode : 3|3@0+ (1,0) [0|7] ""  ADD
 SG_ NoaLcSwtSet : 17|2@0+ (1,0) [0|2] ""  ADD
 SG_ OutdoorPakinModeReq : 175|3@0+ (1,0) [0|7] ""  ADD
 SG_ PltSwtALCSet : 11|2@0+ (1,0) [0|3] ""  ADD
 SG_ PltSwtSet : 7|2@0+ (1,0) [0|3] ""  ADD
 SG_ ScrnTouchdFuncChange : 95|2@0+ (1,0) [0|3] ""  ADD
 SG_ ScrnTouchdLaneChange : 93|2@0+ (1,0) [0|3] ""  ADD
 SG_ ScrnTouchdSpd : 136|9@0+ (1,0) [0|255] "kph"  ADD
 SG_ ScrnTouchdSpdTyp : 91|2@0+ (1,0) [0|3] ""  ADD
 SG_ VehSpdDvtionModSwtSet : 87|2@0+ (1,0) [0|3] ""  ADD

BO_ 208 XCD_ChassisCANFD_RT_0xD0: 8 Vector__XXX
 SG_ LockgCenLockTrigSrc : 7|5@0+ (1,0) [0|31] ""  ADD
 SG_ LockgDrvrDoorLockCmd : 2|2@0+ (1,0) [0|3] ""  ADD

BO_ 1312 XCDChassisCanfdNMFr: 8 Vector__XXX
 SG_ NMKeepAwkRsnVCCD : 48|9@0+ (1,0) [0|511] ""  ADD
 SG_ UDB17VCCD : 17|1@0+ (1,0) [0|1] ""  ADD
 SG_ UDB18VCCD : 18|1@0+ (1,0) [0|1] ""  ADD
 SG_ UDB19VCCD : 19|1@0+ (1,0) [0|1] ""  ADD
 SG_ UDB20VCCD : 20|1@0+ (1,0) [0|1] ""  ADD
 SG_ UDB21VCCD : 21|1@0+ (1,0) [0|1] ""  ADD
 SG_ UDB22VCCD : 22|1@0+ (1,0) [0|1] ""  ADD
 SG_ UDB23VCCD : 23|1@0+ (1,0) [0|1] ""  ADD
 SG_ UDB24VCCD : 24|1@0+ (1,0) [0|1] ""  ADD
 SG_ UDB25VCCD : 25|1@0+ (1,0) [0|1] ""  ADD
 SG_ UDB26VCCD : 26|1@0+ (1,0) [0|1] ""  ADD
 SG_ UDB27VCCD : 27|1@0+ (1,0) [0|1] ""  ADD
 SG_ UDB28VCCD : 28|1@0+ (1,0) [0|1] ""  ADD
 SG_ UDB29VCCD : 29|1@0+ (1,0) [0|1] ""  ADD
 SG_ UDB30VCCD : 30|1@0+ (1,0) [0|1] ""  ADD
 SG_ UDB31VCCD : 31|1@0+ (1,0) [0|1] ""  ADD
 SG_ UDB32VCCD : 32|1@0+ (1,0) [0|1] ""  ADD
 SG_ UDB33VCCD : 33|1@0+ (1,0) [0|1] ""  ADD
 SG_ UDB34VCCD : 34|1@0+ (1,0) [0|1] ""  ADD
 SG_ UDB35VCCD : 35|1@0+ (1,0) [0|1] ""  ADD
 SG_ UDB36VCCD : 36|1@0+ (1,0) [0|1] ""  ADD
 SG_ UDB37VCCD : 37|1@0+ (1,0) [0|1] ""  ADD
 SG_ UDB38VCCD : 38|1@0+ (1,0) [0|1] ""  ADD
 SG_ UDB39VCCD : 39|1@0+ (1,0) [0|1] ""  ADD
 SG_ UDB40VCCD : 40|1@0+ (1,0) [0|1] ""  ADD
 SG_ UDB41VCCD : 41|1@0+ (1,0) [0|1] ""  ADD
 SG_ UDB42VCCD : 42|1@0+ (1,0) [0|1] ""  ADD
 SG_ UDB43VCCD : 43|1@0+ (1,0) [0|1] ""  ADD
 SG_ UDB44VCCD : 44|1@0+ (1,0) [0|1] ""  ADD
 SG_ UDB45VCCD : 45|1@0+ (1,0) [0|1] ""  ADD
 SG_ UDB46VCCD : 46|1@0+ (1,0) [0|1] ""  ADD
 SG_ UDB47VCCD : 47|1@0+ (1,0) [0|1] ""  ADD
 SG_ UDB49VCCD : 49|1@0+ (1,0) [0|1] ""  ADD
 SG_ UDB50VCCD : 50|1@0+ (1,0) [0|1] ""  ADD
 SG_ UDB51VCCD : 51|1@0+ (1,0) [0|1] ""  ADD
 SG_ UDB52VCCD : 52|1@0+ (1,0) [0|1] ""  ADD
 SG_ UDB53VCCD : 53|1@0+ (1,0) [0|1] ""  ADD
 SG_ VCCDChassisCanfdActiveWakeup : 12|1@0+ (1,0) [0|1] ""  ADD
 SG_ VCCDChassisCanfdNodeAddress : 7|8@0+ (1,0) [0|255] ""  ADD
 SG_ VCCDChassisCanfdRepeatMsgReq : 8|1@0+ (1,0) [0|1] ""  ADD
 SG_ VCCDChassisCanfdRepeatMsgSt : 16|1@0+ (1,0) [0|1] ""  ADD

CM_ SG_ 341 HPPAVPRecoverIndCtrl "HPP AVP recovery interrupt indication";
CM_ SG_ 341 HPPAVPSteerWhlAglReqVal "HPP AVP  Steering Wheel Angle Request Value";
CM_ SG_ 341 HPPAVPSteerWhlCtrlReqSts "HPP AVP Steering Wheel Control Request Status";
CM_ SG_ 341 ParkAPBReqMainFrmADD "Parking APB request";
CM_ SG_ 341 ParkEPSLateralCtrlTypeFrmADD "The type of lateral control  Which contain  APA RPA HPP AVP";
CM_ SG_ 341 ParkRecoverIndCtrlFrmADD "Parking recovery interrupt indication";
CM_ SG_ 341 ParkSteerWhlAglReqValFrmADD "Parking  Steering Wheel Angle Request Value";
CM_ SG_ 341 ParkSteerWhlCtrlReqStsFrmADD "Parking Steering Wheel Control Request Status";
CM_ SG_ 341 PASBrkFcnModMainFrmADD "Indicate APA or RPA Backup";
CM_ SG_ 341 PASEmgyBrkReqMainFrmADD "Emergency Brake Request Backup";
CM_ SG_ 341 PASLoLimForAccrCmftMainFrmADD "low limit for acceleration comfort zone Backup";
CM_ SG_ 341 PASMaxAllwdJerkOfAccrMainFrmADD "the maximum allowed jerk of the target acceleration";
CM_ SG_ 341 PASMinAllwdJerkOfAccrMainFrmADD "the minimum allowd jerk of the target acceleration Backup";
CM_ SG_ 341 PASRemaDstMainFrmADD "Remaining Distance Backup";
CM_ SG_ 341 PASReqAccCtrlEnaMainFrmADD "PAS request target acc deceleration control valid Backup";
CM_ SG_ 341 PASReqBrkPrfeMainFrmADD "PAS request Brake Preferred Backup";
CM_ SG_ 341 PASReqDclUtiStslMainFrmADD "PAS request ESP VLC to decelerate untill standstill Backup";
CM_ SG_ 341 PASReqDrvOffMainFrmADD "PAS request ESP CDD S  drive off Backup";
CM_ SG_ 341 PASShdModReqMainFrmADD "the shutdown mode request to ESC VLC Backup";
CM_ SG_ 341 PASUpprLimForAccrCmftMainFrmADD "upper limit for acceleration comfort zone Backup";
CM_ SG_ 341 PASVlcTarAccFromPASMainFrmADD "VLC target acc/deceleration from PAS Backup";
CM_ SG_ 483 ADSBSDLCAEnableForSRR "BSDLCA ʹ��״̬ ���״�ר��";
CM_ SG_ 483 ADSDOWEnableForSRR "DOW ʹ��״̬ ���״�ר��";
CM_ SG_ 483 ADSRCTABEnableForSRR "RCTABʹ��״̬ ���״�ר��";
CM_ SG_ 483 ADSRCWEnableForSRR "RCW ʹ��״̬ ���״�ר��";
CM_ SG_ 483 DvrSpclOpratDistFrmADD "Driver's special operating Distance From ADD
��ʻԱ�����������";
CM_ SG_ 483 DvrSpclOpratIndFrmADD "Driver's special operating index From ADD
��ʻԱ���������Ϊ";
CM_ SG_ 483 GroundAdhereConf "Ground Adhesion Config
���渽�������Ŷ�";
CM_ SG_ 483 GroundAdhereType "Ground Adhesion Type
���渽��������";
CM_ SG_ 483 GroundLayingConf "Ground Laying Config
����������Ŷ�";
CM_ SG_ 483 GroundLayingType "Ground Laying Type
�����������";
CM_ SG_ 483 RoadMueDistFrmADD "Road Mue Distance From ADD
����ϵ����Ǿݱ�������";
CM_ SG_ 483 RoadMueFrmADD "Road Mue From ADD
����ͼ���·����ϵ��";
CM_ SG_ 483 RoadMueLenthFrmADD "Road Mue Length From ADD
��������ϵ����ǳ���";
CM_ SG_ 769 ACCInitSpdSwtFbFrmADD "ACC initial speed limit setting";
CM_ SG_ 769 ACCInitSpdSwtUnavlRsnFrmADD "ACC initial speed limit switch unavailable reason";
CM_ SG_ 769 ADSAEBFCWSwtFbFrmADD "AEB switch feedback";
CM_ SG_ 769 ADSAEBSwtUnavlRsnFrmADD "AEB���ز�����ԭ��";
CM_ SG_ 769 ADSAESESSSwtFbFrmADD "AES_ESS switch feedback";
CM_ SG_ 769 ADSAudModSwtStsFrmADD "ADS Audio Switch Status";
CM_ SG_ 769 ADSBSDLCASwtFbFrmADD "BSD_LCA switch feedback";
CM_ SG_ 769 ADSBSDLCASwtUnavlRsnFrmADD "BSDLCA ���ز�����ԭ��";
CM_ SG_ 769 ADSDOWSwtFbFrmADD "DOW switch feedback";
CM_ SG_ 769 ADSDOWSwtUnavlRsnFrmADD "DOW ���ز�����ԭ��";
CM_ SG_ 769 ADSELKSwtFbFrmADD "ELK switch Feedback";
CM_ SG_ 769 ADSELKSwtUnavlRsnFrmADD "ELK���ز�����ԭ��";
CM_ SG_ 769 ADSLDPWarnTypSwtUnavlRsnFrmADD "LDWP�������Ϳ��ز�����ԭ��";
CM_ SG_ 769 ADSLDWPSwtFbFrmADD "LDW and LDP switch Feedback";
CM_ SG_ 769 ADSLDWPSwtUnavlRsnFrmADD "LDWP���ز�����ԭ��";
CM_ SG_ 769 ADSLDWPWarnTypSwtFbFrmADD "LDW and LDP warning type switch feedback";
CM_ SG_ 769 ADSMAISwtFbFrmADD "MAI switch feedback";
CM_ SG_ 769 ADSMAISwtUnavlRsnFrmADD "MAI ���ز�����ԭ��";
CM_ SG_ 769 ADSParkAudModSwtStsFrmADD "ADS Parking Audio Switch Status";
CM_ SG_ 769 ADSRCTABSwtFbFrmADD "RCTA_RCTB switch feedback";
CM_ SG_ 769 ADSRCTABSwtUnavlRsnFrmADD "RCTA_RCTB ���ز�����ԭ��";
CM_ SG_ 769 ADSRCWSwtFbFrmADD "RCW switch feedback";
CM_ SG_ 769 ADSRCWSwtUnavlRsnFrmADD "RCW ���ز�����ԭ��";
CM_ SG_ 769 ADSTLASwtFbFrmADD "TLA�Ĺ��ܿ��ط���״̬�ź�";
CM_ SG_ 769 ADSTLASwtUnavlRsnFrmADD "TLA����ԭ�򲻿�����ʾ�ź�";
CM_ SG_ 769 ALCSwtStsFrmADD "���˱�����ط����ź�";
CM_ SG_ 769 ALCSwtUnavlRsnFrmADD "ALC Switch unavailable reason";
CM_ SG_ 769 FxdSpdModValSwtStsFrmADD "Fixed speed mode value switch status";
CM_ SG_ 769 LaneChgCnfmSwtStsFrmADD "Lane Change Confirm Switch Status";
CM_ SG_ 769 LowPwrReqFrLRRFrmADD "ǰ���ײ��״﹩��״̬�����ź�
LRR Radar Power Supply Request Status";
CM_ SG_ 769 LowPwrSwtFbFrmADD "Low power mode switch feedback";
CM_ SG_ 769 LowPwrSwtUnavlRsnFrmADD "Low Power unavailable reason
�͹��Ĳ�����ԭ��";
CM_ SG_ 769 LowPwrWarnFrmADD "Low Power mode reminder
�͹���ģʽ������";
CM_ SG_ 769 NOAautoChangingSrAnimation "NOAϵͳ�Զ�����Ӽ���SR��ģ��Ч0x0:default0x1:active";
CM_ SG_ 769 NOACtySwtStsFrmADD "NOA Switch Status";
CM_ SG_ 769 NOAHWSwtStsFrmADD "NOA Switch Status";
CM_ SG_ 769 NOASwtUnavlRsnFrmADD "NOA Switch unavailable reason";
CM_ SG_ 769 PcntgeSpdModValSwtStsFrmADD "Percentage speed mode value switch status";
CM_ SG_ 769 PltSwtStsFrmADD "Pilot Switch Status";
CM_ SG_ 769 PltSwtUnavlRsnFrmADD "Pilot Switch unavailable reason";
CM_ SG_ 769 PntCldSwtFbFrmADD "Point Cloud Switch Feedback";
CM_ SG_ 769 PntCldSwtUnavlRsnFrmADD "Point cloud switch unavailable reason";
CM_ SG_ 769 PrivacyModIniStsFrmADD "Privacy mode initial status";
CM_ SG_ 769 PrivacyModSwtFbFrmADD "Privacy mode switch feedback";
CM_ SG_ 769 SRLidarCldReqFrmADD "SR_Lidar_cloud_request";
CM_ SG_ 769 VehSpdDvtionModSwtStsFrmADD "Vehicle speed divation mode switch status";
CM_ SG_ 131 ChecksumADD2Radar "Time synchronization messageCRC (Cyclic Redundancy Check)";
CM_ SG_ 131 OfsTimeNSecADD2Radar "Offset time value in nanoseconds";
CM_ SG_ 131 OfsTimeSecADD2Radar "Offset time value in seconds";
CM_ SG_ 131 SyncMsgOvsADD2Radar "Time synchronization message Overflow of second";
CM_ SG_ 131 SyncMsgSequenceCounterADD2Radar "Time synchronization message sequence counter";
CM_ SG_ 131 SyncMsgSgwADDtoRadar "Time synchronization message SGW";
CM_ SG_ 131 SyncMsgSyncTimeADD2Radar "Time synchronization message synchronization time";
CM_ SG_ 131 SyncMsgTimeDomainADD2Radar "Time synchronization messagetime domain";
CM_ SG_ 131 SyncMsgTypeADD2Radar "Time synchronization messagetype";
CM_ SG_ 177 ADSABALvlFrmADD "ABA level to the ESP HBA.";
CM_ SG_ 177 ADSABAReqFrmADD "Request of the ABA support from ESP.";
CM_ SG_ 177 ADSABPReqFrmADD "Request of the Prefill to ESP.";
CM_ SG_ 177 ADSAEBReqFrmADD "Request of the deceleration control.";
CM_ SG_ 177 ADSAEBTarDecelFrmADD "Target deceleration value from AEB EBA AEB VRU";
CM_ SG_ 177 ADSAWBAESLvlFrmADD "Different level request of the brake jerk.";
CM_ SG_ 177 ADSAWBAESReqFrmADD "Request of the brake jerk warning to ESP.";
CM_ SG_ 177 ADSMAIAccrPerReqFrmADD "MAI ���ٿ��ưٷֱ�";
CM_ SG_ 177 ADSMAIAccrPerReqVldFrmADD "MAI ���ٿ�����Ч��";
CM_ SG_ 177 ADSMAIReqFrmADD "MAI�����������־λ";
CM_ SG_ 177 ADSMAIReqVldFrmADD "MAI�����������־λ��Ч��";
CM_ SG_ 177 ADSVibActvFrmADD "Steering wheel vibration request";
CM_ SG_ 177 DrvAxTarEnaMainFrmADD "ADSAxTarEnaMain";
CM_ SG_ 177 DrvAxTarLowerComfBandMainFrmADD "ADSAxTarLowerComfBandMain";
CM_ SG_ 177 DrvAxTarReqMainFrmADD "ADSAxTarReqMain";
CM_ SG_ 177 DrvAxTarUpperComfBandMainFrmADD "ADSAxTarUpperComfBandMain";
CM_ SG_ 177 DrvBrakePreferredMainFrmADD "ADSBrakePreferredMain";
CM_ SG_ 177 DrvCtrlAvailabilityMainFrmADD "ADSCtrlAvailabilityMain";
CM_ SG_ 177 DrvdAxTarLowerLimitMainFrmADD "ADSdAxTarLowerLimitMain";
CM_ SG_ 177 DrvdAxTarUpperLimitMainFrmADD "ADSdAxTarUpperLimitMain";
CM_ SG_ 177 DrvDriveAwayReqMainFrmADD "Autonomous Driving system Drive Off Request";
CM_ SG_ 177 DrvPinStrAglReqStsFrmADD "Pinion steering angle request STATE for driving functions";
CM_ SG_ 177 DrvPinStrAglReqValFrmADD "Pinion steering angle request for driving functions";
CM_ SG_ 177 DrvPrecsReqFrmADD "Precision request for torque";
CM_ SG_ 177 DrvReqModeMainFrmADD "ADSReqModeMain";
CM_ SG_ 177 DrvReqTypeMainFrmADD "ADSReqTypeMain";
CM_ SG_ 177 DrvSecureReqMainFrmADD "ADSSecureReqMain";
CM_ SG_ 177 DrvShutdownModeMainFrmADD "ADSShutdownModeMain";
CM_ SG_ 177 DrvSteerWhlTqLimFrmADD "Steering Wheel Torque limit";
CM_ SG_ 177 DrvUseUpperComfBandMainFrmADD "ADSUseUpperComfBandMain";
CM_ SG_ 177 DrvVehStopReqMainFrmADD "Autonomous Driving system Standstill Request";
CM_ SG_ 193 ADASGearFcnModMainFrmADD "ADAS Function mode request";
CM_ SG_ 193 ADASParkDrvFcnModMainFrmADD "ADAS Parking Drive mode request";
CM_ SG_ 193 ADASParkDrvModOverrideFrmADD "ADASParkDrvModAllowOverrideFrmADD";
CM_ SG_ 193 ADASParkDrvVehWheelTqEnaFrmADD "ADAS  Parking Drive Vehicle Wheel torque request  Enable";
CM_ SG_ 193 ADASParkDrvVehWheelTqReqFrmADD "ADAS  Parking Drive Vehicle Wheel torque request";
CM_ SG_ 193 ADSAVHReqFrmADD "�Ǽ���������AVH";
CM_ SG_ 193 ADSEPBReqMainFrmADD "EPB����";
CM_ SG_ 193 ADSReqModeMainFrmADD "ADAS Driving mode request";
CM_ SG_ 193 ADSTqTarEnaMainTypeFrmADD "ADAS Driving Vehicle Wheel torque request Enable";
CM_ SG_ 193 ADSTqTarReqMainFrmADD "ADAS Driving Vehicle Wheel torque target request
�Ǽ������Һѹ�ƶ�Ť��ֵ";
CM_ SG_ 237 ADSACCStsFrmADD "ACC״̬ 
����״̬Ϊ Normal ACtive StandActive StandWait Override Takeover";
CM_ SG_ 237 CNOAAlrtWarnLv1FrmADD "City-NOA alert warning level_1";
CM_ SG_ 237 CNOAAlrtWarnLv3FrmADD "City-NOA alert warning level_3";
CM_ SG_ 237 CNOAIntrctvCompntTypFrmADD "City-NOA Interactive component Type";
CM_ SG_ 237 CNOARemd2FrmADD "City-NOA reminding message for long-time toast";
CM_ SG_ 237 CNOARemdFrmADD "City-NOA  reminding message for short-time toast";
CM_ SG_ 237 DistLvlLmtDispFrmADD "Distance Level Limit Display";
CM_ SG_ 237 DrvAlrtWarnLv1FrmADD "Driving alert warning level_1";
CM_ SG_ 237 DrvAlrtWarnLv2FrmADD "Driving alert warning level_2";
CM_ SG_ 237 DrvAlrtWarnLv3FrmADD "Driving alert warning level_3";
CM_ SG_ 237 DrvFltStsFrmADD "Autonomous Driving system Fault status";
CM_ SG_ 237 DrvFltStsVldFrmADD "Autonomous Driving system Fault status Valid";
CM_ SG_ 237 DrvLatIcnDispStsFrmADD "Driving Lateral icon display";
CM_ SG_ 237 DrvLongIcnDispFrmADD "Driving longitudinal icon display";
CM_ SG_ 237 DrvRemd2FrmADD "Driving reminding message for long time toast";
CM_ SG_ 237 DrvRemdFrmADD "Driving reminding message for short-time toast";
CM_ SG_ 237 DrvrSelTarSpdFrmADD "Pilot Driver Selected Target Speed";
CM_ SG_ 237 DrvSteerWhlBtnLi "Driving Steer Wheel Button Light";
CM_ SG_ 237 DrvStlDispFrmADD "Driving Style Display";
CM_ SG_ 237 IntrctvCompntTypFrmADD "Interactive component Type";
CM_ SG_ 237 LaneChangeModFrmADD "lane change mode";
CM_ SG_ 237 ScrnDrvFuncTypFrmADD "Screen Driving Function Type";
CM_ SG_ 237 SpdLvlLmtDispFrmADD "Set Speed Limit Display";
CM_ SG_ 237 TarSpdSetMothodFrmADD "Target Spead Setting Mothod";
CM_ SG_ 1329 ADDChassisCanfdActiveWakeup "Active Wakeup Bit";
CM_ SG_ 1329 ADDChassisCanfdNodeAddress "Node source address";
CM_ SG_ 1329 ADDChassisCanfdRepeatMsgReq "Repeat Message Request Bit";
CM_ SG_ 1329 ADDChassisCanfdRepeatMsgSt "Repeat Message State indication";
CM_ SG_ 1325 ADDChassisCanfdActiveWakeup1 "Active Wakeup Bit";
CM_ SG_ 1325 ADDChassisCanfdNodeAddress1 "Node source address";
CM_ SG_ 1325 ADDChassisCanfdRepeatMsgReq1 "Repeat Message Request Bit";
CM_ SG_ 1325 ADDChassisCanfdRepeatMsgSt1 "Repeat Message State indication";
CM_ SG_ 425 IMUCalSt "IMUCalibrationSt
IMU�궨״̬";
CM_ SG_ 425 LonAccr "Longititude Acceleration
������ٶ�";
CM_ SG_ 425 LonSnsrSt "Longititude Sensor State
������ٶ���Ч��";
CM_ SG_ 426 LatAccr "Lateral Acceleration
������ٶ�";
CM_ SG_ 426 LatAccrSt "Lateral Sensor State
������ٶ���Ч��";
CM_ SG_ 426 YawRate "Yaw Rate
��ڽ��ٶ�";
CM_ SG_ 426 YawRateSnsrSt "Yaw Rate Sensor State
��ڽ��ٶ���Ч��";
CM_ SG_ 848 ACUWarnLampSts "Airbag Warning Lamp Status 
ACU���ϵ��ź�";
CM_ SG_ 848 DrvrBucSts "Driver Buckle Status 
����ʻ��ȫ����״̬";
CM_ SG_ 848 PassBucSts "Passenger Buckle Status
���ݰ�ȫ��״̬";
CM_ SG_ 849 ImpctEvntSts "Impact Event Status
 ��ײ�¼�״̬";
CM_ SG_ 336 ABAActv "ABA active";
CM_ SG_ 336 ABAAvl "ABA available";
CM_ SG_ 336 APBAplAvlBCP "APB Apply Avalible from BCP
BCP�࿨ǯ�Ƿ���Լн�";
CM_ SG_ 336 APBRelAvlBCP "APB Release Avalible from BCP
BCP�࿨ǯ�Ƿ�����ͷ�";
CM_ SG_ 336 APBStsBkp "BCP&BCS APB Status";
CM_ SG_ 336 BCPBrkLiIllmnReq "Request to illuminate brake light from BCP";
CM_ SG_ 336 BCPBrkSysWarnText "BCP Brake System Warning Text";
CM_ SG_ 336 BCPMstCylP "PressureintheBCPmastercylinder";
CM_ SG_ 336 BCPMstCylPVld "QualifierforBCPmastercyclinder'spressuresignal";
CM_ SG_ 336 BCPSimulatorP "Pressure in the BCP Plunger";
CM_ SG_ 336 BCPSimulatorPVld "Qualifier for BCP Plunger's pressure signal";
CM_ SG_ 336 BCPSysSts "BCP System Status";
CM_ SG_ 336 BrkFldWarn "Brake Fluid Warning";
CM_ SG_ 336 BrkFldWarnVld "Qualifier for Brake Fluid Warning Signal";
CM_ SG_ 336 BrkPedlAppld "Indicates whether the driver operates the
 brake pedal. Only active when the driver brakes";
CM_ SG_ 336 BrkPedlAppldVld "Qualifier for brake pedal applied signal";
CM_ SG_ 336 BrkPedlPerct "Brake Pedal Percentage";
CM_ SG_ 336 BrkPedlPerctVld "Qualifier for Brake Pedal Percentage signal";
CM_ SG_ 336 HBAActv "HBA active";
CM_ SG_ 336 HBAAvl "HBA available";
CM_ SG_ 336 HBBActv "HBB active";
CM_ SG_ 336 InpRodStk "Input Rod Stroke";
CM_ SG_ 336 InpRodStkVld "Qualifier for Input Rod Stroke signal";
CM_ SG_ 337 ABPActv "ABP active";
CM_ SG_ 337 ABPAvl "ABP available";
CM_ SG_ 337 ABSActv "ABS Control Active";
CM_ SG_ 337 ABSErrDetd "ABS error detected";
CM_ SG_ 337 AEBActv "AEB active";
CM_ SG_ 337 AEBAvl "AEB available";
CM_ SG_ 337 APBAplAvlBCS "APB Apply Avalible from BCS
BCS�࿨ǯ�Ƿ���Լн�";
CM_ SG_ 337 APBErrDetd "APB Error Status";
CM_ SG_ 337 APBRelAvlBCS "APB Release avalialbe from BCS
BCS�࿨ǯ�Ƿ�����ͷ�";
CM_ SG_ 337 APBSts "APB Status";
CM_ SG_ 337 APBTxtDip "APB Text Display";
CM_ SG_ 337 AVHAvl "AVH available";
CM_ SG_ 337 AVHSts "AVH function status";
CM_ SG_ 337 AWBActv "AWB active";
CM_ SG_ 337 AWBAvl "AWB available";
CM_ SG_ 337 BCSBrkSysWarnText "BCS Brake System Warning Text";
CM_ SG_ 337 BrkLiIllmnReq "Request to illuminate brake light";
CM_ SG_ 337 BrkSysWarnLamp "Brake System Warning Lamp";
CM_ SG_ 337 CDPActv "CDP active";
CM_ SG_ 337 CDPAvl "CDP available";
CM_ SG_ 337 CSTSts "CST function status";
CM_ SG_ 337 DrvOffTqThd "Drive off torque threshold";
CM_ SG_ 337 DSTActv "DST active";
CM_ SG_ 337 DSTSteerTqReq "Steering wheel torque requested from DST";
CM_ SG_ 337 EBAActv "EBA active";
CM_ SG_ 337 EBDActv "EBD Control Active";
CM_ SG_ 337 EBDErrDetd "EBD error detected";
CM_ SG_ 337 EmgyBrkLiReq "Emergency brake light request";
CM_ SG_ 337 ESCErrDetd "ESC error detected";
CM_ SG_ 337 ESCIntvLamp "ESC Intervention Lamp";
CM_ SG_ 337 ESCPataLamp "ESC diable status";
CM_ SG_ 337 ESCSwitchAvl "ESC Switch availability
ESC���ؿ���״̬";
CM_ SG_ 337 EstimdSumOfVehHydBrkEachWhl "Estimated sum of vehicle hydraulic brake force acting on each wheel";
CM_ SG_ 337 HBBActive "BCS HBB Active";
CM_ SG_ 337 HBBSts "HBB function status";
CM_ SG_ 337 HBCActv "HBC active";
CM_ SG_ 337 HDCAvl "HDC function available";
CM_ SG_ 337 HDCCtrlSts "HDC function control status";
CM_ SG_ 337 HHCActv "HHC active";
CM_ SG_ 337 HHCAvl "HHC available";
CM_ SG_ 337 HRBActv "HRB available";
CM_ SG_ 337 HRBAvl "HRB active";
CM_ SG_ 337 HydBrkFExist "Hydraulic brake force exsit";
CM_ SG_ 337 MstCylPCmp "Pressure in the master cylinder  offset is included .";
CM_ SG_ 337 MstCylPVld "Qualifier for the master cylinder pressure signal";
CM_ SG_ 337 SCMActv "SCM active";
CM_ SG_ 337 SCMAvl "SCM Available";
CM_ SG_ 337 TCSActv "TCS Controller Active";
CM_ SG_ 337 VDCActv "VDC Controller Active";
CM_ SG_ 337 VehStandStillIndcr "Indicate whether the vehicle is standstill or not";
CM_ SG_ 337 VehStandStillIndcrVld "Qualifier for vehicle standstill indicate signal";
CM_ SG_ 338 APAActrAvl "Flag indicate APA availability for longitudinal control";
CM_ SG_ 338 APCActvVehHld "Flag indicate that vehicle is activly hold by longitudinal actuator controller";
CM_ SG_ 338 APCDrvrBrkOvrdFlg "Indicate driver brakes more than the system.";
CM_ SG_ 338 APCFailrSts "detailed information why this APC maneuver failed";
CM_ SG_ 338 APCSts "Longitudinal controller status";
CM_ SG_ 338 BCSLgtCtrlPtTarTq "BCS longitudinal powertrain target torque";
CM_ SG_ 338 BCSLgtCtrlPtTarTqEna "BCS longitudinal powertrain torque request";
CM_ SG_ 338 BiasMaxFrntAxle "The maxium percentage of Target Recuperation Torque executed on front axle";
CM_ SG_ 338 BiasMaxReAxle "The maxium percentage of Target Recuperation Torque executed on rear axle";
CM_ SG_ 338 CstRgnBlendSts "Coast Regen Blending Status";
CM_ SG_ 338 CstRgnBlendTqReqFA "Coast Regen Blending Torque Request FA";
CM_ SG_ 338 CstRgnBlendTqReqRA "Coast Regen Blending Torque Request FA";
CM_ SG_ 338 DrgTqCtrlActvFA "Drag torque control active on front axle";
CM_ SG_ 338 DrgTqCtrlActvRA "Drag torque control active on rear axle";
CM_ SG_ 338 PtTqRednActvFA "Powertrain torque reduction active FA";
CM_ SG_ 338 PtTqRednActvRA "Powertrain torque reduction active RA";
CM_ SG_ 338 RPAAVPActrAvl "Flag indicate RPA  AVP availability for longitudinal control";
CM_ SG_ 338 TarRdcdPtTqFA "Target reduced powertrain torque FA";
CM_ SG_ 338 TarRdcdPtTqRA "Target reduced powertrain torque RA";
CM_ SG_ 338 TarRecuTqReq "Target Recuperation Torque Request to Generator";
CM_ SG_ 338 TarRecuTqReqSts "Status of Target Recuperation torque of Generator";
CM_ SG_ 352 BrkDiscTFrntLe "Brake Disc Temperature Front Left";
CM_ SG_ 352 BrkDiscTFrntRi "Brake Disc Temperature Front Right";
CM_ SG_ 352 BrkDiscTReLe "Brake Disc Temperature Rear Left";
CM_ SG_ 352 BrkDiscTReRi "Brake Disc Temperature Rear Right";
CM_ SG_ 352 BrkDiscTSts "BrakeDiscTemperatureStatus
�ƶ����¶�״̬";
CM_ SG_ 352 BrkDiscTStsAval "BrakeDiscTemperatureStatusAvailability 
�ƶ����¶�״̬��Ч";
CM_ SG_ 352 RgnTqCorrnOffs1 "Regeneration Torque Correction Offset 1";
CM_ SG_ 352 RgnTqCorrnOffs2 "Regeneration Torque Correction Offset 2";
CM_ SG_ 352 RgnTqCorrnOffs3 "Regeneration Torque Correction Offset 3";
CM_ SG_ 352 RgnTqCorrnOffs4 "Regeneration Torque Correction Offset 4";
CM_ SG_ 352 RgnTqCorrnOffs5 "Regeneration Torque Correction Offset 5";
CM_ SG_ 352 RgnTqCorrnOffs6 "Regeneration Torque Correction Offset 6";
CM_ SG_ 352 RgnTqCorrnOffs7 "Regeneration Torque Correction Offset 7";
CM_ SG_ 352 WhlPEstimdFrntLe "Estimated or modeled wheel pressure of front left wheel";
CM_ SG_ 352 WhlPEstimdFrntLeVld "Qualifier for estimated front left wheel pressure signals";
CM_ SG_ 352 WhlPEstimdFrntRi "Estimated or modeled wheel pressure of front right wheel";
CM_ SG_ 352 WhlPEstimdFrntRiVld "Qualifier for estimated front right wheel pressure signals";
CM_ SG_ 352 WhlPEstimdReLe "Estimated or modeled wheel pressure of rear left wheel";
CM_ SG_ 352 WhlPEstimdReLeVld "Qualifier for estimated rear left wheel pressure signals";
CM_ SG_ 352 WhlPEstimdReRi "Estimated or modeled wheel pressure of rear right wheel";
CM_ SG_ 352 WhlPEstimdReRiVld "Qualifier for estimated rear right wheel pressure signals";
CM_ SG_ 179 BCSActrActvForADC "BCS actuator active for ADC";
CM_ SG_ 179 BCSActrAvlStsForADC "BCS actuator available status for ADC";
CM_ SG_ 179 BCSActrAvlStsForADCL3 "BCS available status for ADC L3";
CM_ SG_ 179 BCSActrRampOffStsForADC "BCS actuator ramp off status for ADC";
CM_ SG_ 179 BCSActrVldForADC "BCS actuator valid for ADC";
CM_ SG_ 179 VehSpd "Vehicle speed";
CM_ SG_ 179 VehSpdVld "Qualifier for vehicle speed signal";
CM_ SG_ 179 WhlDirFrntLe "Wheel moving direction front left";
CM_ SG_ 179 WhlDirFrntLeVld "Qualifier for wheel moving direction front left";
CM_ SG_ 179 WhlDirFrntRi "Wheel moving direction front right";
CM_ SG_ 179 WhlDirFrntRiVld "Qualifier for wheel moving direction front right";
CM_ SG_ 179 WhlDirReLe "Wheel moving direction rear left";
CM_ SG_ 179 WhlDirReLeVld "Qualifier for wheel moving direction rear left";
CM_ SG_ 179 WhlDirReRi "Wheel moving direction rear right";
CM_ SG_ 179 WhlDirReRiVld "Qualifier for wheel moving direction rear right";
CM_ SG_ 179 WhlDstTiStampFrntLe "Wheel distance time stamp for front left";
CM_ SG_ 179 WhlDstTiStampFrntRi "Wheel distance time stamp for front right";
CM_ SG_ 179 WhlDstTiStampReLe "Wheel distance time stamp for rear left";
CM_ SG_ 179 WhlDstTiStampReRi "Wheel distance time stamp for rear left";
CM_ SG_ 179 WhlSpdEdgeFrntLe "Wheel speed Edges front left";
CM_ SG_ 179 WhlSpdEdgeFrntLeVld "Qualifier for wheel speed Edges front left";
CM_ SG_ 179 WhlSpdEdgeFrntRi "Wheel speed Edges front right";
CM_ SG_ 179 WhlSpdEdgeFrntRiVld "Qualifier for wheel speed Edges front right";
CM_ SG_ 179 WhlSpdEdgeReLe "Wheel speed Edges rear left";
CM_ SG_ 179 WhlSpdEdgeReLeVld "Qualifier for wheel speed Edges rear left";
CM_ SG_ 179 WhlSpdEdgeReRi "Wheel speed Edges rear right";
CM_ SG_ 179 WhlSpdEdgeReRiVld "Qualifier for wheel speed Edges rear right";
CM_ SG_ 179 WhlSpdFrntLe "Wheel speed front left";
CM_ SG_ 179 WhlSpdFrntLeVld "Status of wheel speed front left";
CM_ SG_ 179 WhlSpdFrntRi "Wheel speed front right";
CM_ SG_ 179 WhlSpdFrntRiVld "Status of wheel speed front right";
CM_ SG_ 179 WhlSpdReLe "Wheel speed rear left";
CM_ SG_ 179 WhlSpdReLeVld "Status of wheel speed rear left";
CM_ SG_ 179 WhlSpdReRi "Wheel speed rear right";
CM_ SG_ 179 WhlSpdReRiVld "Status of wheel speed rear right";
CM_ SG_ 226 BCSBrkTqActForADS "BCSʵ����Ӧ�Ǽ�Ť��ֵ";
CM_ SG_ 226 BCSBrkTqReqADSDominantForADS "�Ǽ������Fx ��ǰ�Ƿ��ǵ�һ���ȼ�ִ���ź�";
CM_ SG_ 226 BCSTqActrActvForADS "Ť�ؽӿ����ֿ��Ʒ���ֵ";
CM_ SG_ 226 BCSTqDrvReqBrkForADS "��ʻԱ���ƶ�����ֵ";
CM_ SG_ 226 BCSTqHumanActrAvlStsForADS "�������ϵͳ���Ǽ�Human�����Է����ź�";
CM_ SG_ 226 BCSTqL3ActrAvlStsForADS "�������ϵͳ���Ǽ�L3���ܿ����Է����ź�";
CM_ SG_ 226 BCSTqUnmannedActrAvlStsForADS "�������ϵͳ���Ǽ�Unmanned�����Է����ź�";
CM_ SG_ 579 BattSocRaw "Battery State of charge raw
���SOC";
CM_ SG_ 579 BattURaw "Battery Voltage raw
��ص�ѹ";
CM_ SG_ 353 AVPHPPCtrlAvlSts "EPS AVP/HPP Feature Control Avaliable Status
EPS���� AVP/HPP ���ܵĿ��ƿ���״̬";
CM_ SG_ 353 AVPHPPCtrSts "What channel of the EPS is in control
����EPSĿǰ������Ӧ��ͨ��";
CM_ SG_ 353 AVPHPPReqFbSts "EPS feedback for AVP/HPP Request
EPS����AVP/HPP��������";
CM_ SG_ 353 AVPHPPReqFltSts "EPS fault status related to execution of AVP/HPP
EPS����AVP/HPP��ǰ�Ĺ���״̬";
CM_ SG_ 353 DSTReqCtrlSts "EPS ����BCS��ǰDST���ܵ�fault״̬
EPS status related to execution of DST from BCS";
CM_ SG_ 353 FailrSts "EPS ����״̬
EPS Failure Status";
CM_ SG_ 353 HODQly "HOD �ź����Ŷ�ֵ
Indicate the HOD signal confidence  spcifically for hands off detect.";
CM_ SG_ 353 HODSts "EPS ����ʻԱ���Ƿ��ڷ�������
EPS indicate the driver hands on the steering wheel or not";
CM_ SG_ 353 HODVld "HOD �ź���Чλ
HOD signal Valid Flag";
CM_ SG_ 353 PASReqFbSts "EPS ����PAS��������
EPS feedback for PAS request";
CM_ SG_ 353 PASReqFltSts "EPS ����PAS��ǰFault ״̬
EPS status related to execution of PAS";
CM_ SG_ 992 CcwEOTDet "Counter Clock wise End of Stop Value Learned Flag. ��ʱ����ֹ��(ĩ��)λ��ѧϰ�ɹ���־λ";
CM_ SG_ 992 CcwEOTValue "Counter Clock wise End of Stop Value,Direction: Counter Clock wise is.��ʱ����ֹ��(ĩ��)λ��, ����:��ʱ��Ϊ��";
CM_ SG_ 992 CwEOTDet "Clock wise End of Stop Value Learned Flag. ˳ʱ����ֹ��(ĩ��)λ��ѧϰ�ɹ���־λ";
CM_ SG_ 992 CwEOTValue "Clock wise End of Stop Value, Direction:Clock wise is.˳ʱ����ֹ��(ĩ��)λ��, ����:˳ʱ��Ϊ��";
CM_ SG_ 181 ADASReqFbStsADD "Feedback status to ADD driving lateral control request";
CM_ SG_ 181 ADASReqFltStsADD "Feedback fault status to ADD driving lateral control request";
CM_ SG_ 181 ADASReqOvlySteerWhlTqADD "Equivalent steering wheel torque from ADD driving lateral control request
'+' as the equivalent torque generate Anti Clockwise of steering wheel
' ' as the equivalent torque generate Clockwise of steering wheel";
CM_ SG_ 181 ADASReqOvlyTqADD "Overlay Torque  Motor Torque  from ADD driving lateral control request
���� 
˳ʱ��ת������������  
��ʱ��ת������������";
CM_ SG_ 181 DrvrSteerActvADD "Indicate if the driver override or not to ADD driving lateral control request";
CM_ SG_ 181 PinionAglSpdV2C "Convert VGR Pinion Velocity to CGR Velocity. Direction: Clockwise; Counter Clockwise.VGR������ת��ת��CGRת��.˳ʱ��Ϊ��,��ʱ��Ϊ��";
CM_ SG_ 181 PinionSteerAgl "������ת��
Steering Wheel Angle
���� 
Anticlockwise direction of steering wheel increase angle output.
Clockwise direction of steering wheel decrease angle output.";
CM_ SG_ 181 PinionSteerAglSpd "������ת��
Steering Wheel Velocity
����  Clockwise     Anti Clockwise";
CM_ SG_ 181 PinionSteerAglSpdVld "������ת����Чλ
Steering Wheel Velocity Valid Flag";
CM_ SG_ 181 PinionSteerAglSpdVldV2C "Pinion Velocity Valid Flag
������ת����Чλ";
CM_ SG_ 181 PinionSteerAglV2C "Convert Variable Gear Ratio(VGR) PinionAngle to a Constant Gear Ratio(CGR) Pinion Angle.��VGR������ת��ת��CGR ת��";
CM_ SG_ 181 PinionSteerAglVld "������ת����Чλ
Steering Wheel Angle Valid Flag";
CM_ SG_ 181 PinionSteerAglVldV2C "PinionAngle Valid Flag
������ת����Чλ";
CM_ SG_ 181 SteerWhlTq "������Ť��
Steering Wheel Torque
����  Clockwise     Anti Clockwise";
CM_ SG_ 181 SteerWhlTqVld "������Ť����Чλ
Steering Wheel torque Valid Flag";
CM_ SG_ 181 SteerWhlVibStsADD "Indicate the steering wheel vibration active or not to ADD";
CM_ SG_ 343 VCUGearChgFailrSts "Gear change failure status";
CM_ SG_ 343 VCULatSlopForDisp "�����¶�";
CM_ SG_ 343 VCULgtSlopForDisp "�����¶�";
CM_ SG_ 343 VCUSpclRoadSurfTypForDisp "·������";
CM_ SG_ 481 DvrSpclOpratIndForADD "Special Operation index for ADD
����������";
CM_ SG_ 481 LVPwrSplyBattErrSts "Low power supply battery error status
��ѹ�����ع���״̬";
CM_ SG_ 481 LVPwrSplyDCDCErrSts "Low voltage Power Supply DCDC Error Statue
DCDC���ϵ��µĵ�ѹ��������";
CM_ SG_ 481 LVPwrSplyHiErrSts "Low power supply high error status
��ѹ����߷��չ���״̬";
CM_ SG_ 481 LVPwrSplyLoErrSts "Low power supply low error status
��ѹ����ͷ��չ���״̬";
CM_ SG_ 481 VCUAccrPrmSetAllwd "VCU accelerate parameter Setting allowed
��ʻģʽ�������Բ�����������";
CM_ SG_ 481 VCUBatModAllwd "VCU Battle Mode Allowed
VCU����ģʽ����ʹ��";
CM_ SG_ 481 VCUDriftModSetSts "VCU Drift Mode Setting Status
VCUһ��Ư�ƹ�������״̬";
CM_ SG_ 481 VCUDrvModRgnPrmSts "VCU Drive mode regeneration parameter Status
��ʻģʽ�����������Բ�������";
CM_ SG_ 481 VCUDrvModStSts "VCU Drive mode setting status
��ʻģʽ�趨״̬";
CM_ SG_ 481 VCUExtmECOModStReq "VCU Extremely ECO mode Request
���¾���ģʽ����";
CM_ SG_ 481 VCULnchPlusSts "VCU Launch plus status
VCU����ģʽ״̬";
CM_ SG_ 481 VCURgnPrmSetAllwd "VCU regeneration parameter  Setting allowed
��ʻģʽ�����������Բ�����������";
CM_ SG_ 481 VCUSteerAsstPrmSetAllwd "VCU steering assistance parameter Setting allowed
��ʻģʽת������������������";
CM_ SG_ 481 VCUSuspDampgPrmSetAllwd "VCU steering assistance parameter Setting allowed
��ʻģʽ�����������Բ�����������";
CM_ SG_ 481 VCUSuspLvlgPrm1Allwd "VCU suspension level parameter1 Setting allowed
��ʻģʽ���ܸ߶������������";
CM_ SG_ 481 VCUSuspLvlgPrm2Allwd "VCU suspension level parameter2 Setting allowed
��ʻģʽ���ܸ߶ȴθ���������";
CM_ SG_ 481 VCUSuspLvlgPrm3Allwd "VCU suspension level parameter3 Setting allowed
��ʻģʽ���ܸ߶�����������";
CM_ SG_ 481 VCUSuspLvlgPrm4Allwd "VCU suspension level parameter4 Setting allowed
��ʻģʽ���ܸ߶ȴε���������";
CM_ SG_ 481 VCUSuspLvlgPrm5Allwd "VCU suspension level parameter5 Setting allowed
��ʻģʽ���ܸ߶������������";
CM_ SG_ 481 VCUWashModEntryAllwd "VCU Wash Mode Entry allowed
ϴ��ģʽ��������";
CM_ SG_ 481 VCUWashModExtAllwd "VCU Wash Mode Exit allowed
ϴ��ģʽ�����˳�";
CM_ SG_ 514 StsOfIndcr "ת��״ָ̬ʾ";
CM_ SG_ 514 SwtIndcr "ת�򲦸��ź�";
CM_ SG_ 514 SwtIndcrSts "Switch Indicator Status";
CM_ SG_ 547 ExtrLtgStsHiBeam "Զ�����״̬";
CM_ SG_ 547 ExtrLtgStsLoBeam "������״̬";
CM_ SG_ 547 ExtrLtgStsStop "ɲ����״̬�ܷ���";
CM_ SG_ 547 ExtrLtgStsTurnIndrLe "��ת���״̬����";
CM_ SG_ 547 ExtrLtgStsTurnIndrRi "��ת���״̬����";
CM_ SG_ 547 VCUSpdLimrSts "VCU Speed Limiter Status
VCU�ɵ����ٹ���״̬";
CM_ SG_ 547 VCUSpdLimrValSts "VCU Speed Limiter Value Status
VCU�ɵ����ٳ���ֵ";
CM_ SG_ 724 VCUChrgnModSts "Charging Mode Status";
CM_ SG_ 724 VCUHVExtPortConnectnTypInfo "HV External Port Connection Type Information ���¶��� ԭ����chrgnPortConnectnStsInfo ����map";
CM_ SG_ 144 CarModSts "CarMode״̬�ź�";
CM_ SG_ 144 DrvActvSts "�û�ͨ����ʽ�а����ļ�ʻ����״̬";
CM_ SG_ 144 PwrModSts "PowerMode Status";
CM_ SG_ 144 PwrModVld "PowerMode Validty";
CM_ SG_ 144 VCUAccrPedlRat "��������̤�忪��";
CM_ SG_ 144 VCUAccrPedlRatVld "����̤����Ч��";
CM_ SG_ 144 VCUActDrvMod "VCU actual drive mode 
VCUʵ�ʼ�ʻģʽ";
CM_ SG_ 144 VCUActGearLvr "Actual gear level ����ʵ�ʵ�λ
P R N D��λ";
CM_ SG_ 144 VCUActGearLvrVld "����ʵ�ʵ�λ��Чλ";
CM_ SG_ 144 VCUDrvOffFcnLim "VCU send to BCS to identify whether vehcile can drive off or not as powertrain has fault and power limited.
VCU���͸�BCSϵͳ,�����ж���������ϵͳ�Ƿ���ڹ��϶������޲����𲽵��ж�";
CM_ SG_ 144 VCUFrntEmTqRdy "The Front Motor  can be ready to response chassis torque request.
ǰ���������ӦŤ������.";
CM_ SG_ 144 VCUGearLvrAvail "Vehicle Gear Response is available for ADAS
���Ǽݷ����ĵ�λ���ñ�־λ";
CM_ SG_ 144 VCUPrkgBtnPsd "��ʻԱ����P��";
CM_ SG_ 144 VCUPtRdyFlg "��ʻʹ��";
CM_ SG_ 144 VCUReEmTqRdy "Rear EM is ready to response chassis Torque Request
�����Ƿ���Ready״̬";
CM_ SG_ 144 VCURgnTqCorrnFac "Regeneration Torque Correction Factor";
CM_ SG_ 144 VCUShifterMoveFlg "��ʻԱ�����˻����˵ı�־λ";
CM_ SG_ 144 VCUStsModCst "energy recuperation end mode.
��������״̬ģʽ";
CM_ SG_ 144 VCUTarGearLvr "Ŀ�굵λ  P R N D��λ";
CM_ SG_ 144 VCUTarGearLvrVld "Ŀ�굵λ��Чλ";
CM_ SG_ 144 VCUVirtAccrPedl "�������ſ��� ��ǰģʽ��pedal map����";
CM_ SG_ 144 VCUVirtAccrPedlVld "�������ſ�����Чλ";
CM_ SG_ 195 ActiveOfADB "Active of ADB Function  ����ADB ����";
CM_ SG_ 195 ActnOfDayRunngLampLe "Activation of Left DRL";
CM_ SG_ 195 ActnOfDayRunngLampRi "Activation Of Right DRL �����еƼ�������";
CM_ SG_ 195 ActnOfLedFrntPosnLamp "Activation Of Front Position Lampǰλ�õƼ�������";
CM_ SG_ 195 ActnOfLedHiBeam "Activation Of High BeamԶ�⼤������";
CM_ SG_ 195 ActnOfParkLampLe "Activation Of  Left Parking Lamp";
CM_ SG_ 195 ActnOfParkLampRi "Activation Of  Right Parking Lamp";
CM_ SG_ 195 FarewellFuncSet "Farewell function setting";
CM_ SG_ 195 SBLDmValSetLe "Left Static bending Light Dimming Value setting";
CM_ SG_ 195 SBLDmValSetRi "Left Static bending Light Dimming Value setting";
CM_ SG_ 195 SegmtDirCtrlSet "Segment  direct control setting";
CM_ SG_ 195 WelcomeFuncSet "Welcome function setting";
CM_ SG_ 195 WipSpdReqHi "����ٶ�Ϊ���ٵ�λ
High speed wiping request";
CM_ SG_ 195 WipSpdReqLo "����ٶ�Ϊ���ٵ�λ
Low speed wiping request";
CM_ SG_ 198 VCUAccrPedlFlg "����̤����±�־λ";
CM_ SG_ 198 VCUAccrPedlRatGrdt "��������̤�忪�ȱ仯��";
CM_ SG_ 198 VCUADASDrvrWhlTqReq "����̤���ӦŤ��";
CM_ SG_ 198 VCUADASTorqueAvailableSt "VCU ADAS Torque mode available";
CM_ SG_ 198 VCUADASTqModeFeedback "VCU ADAS Torque control mode feedback";
CM_ SG_ 198 VCUAlwParkRels "�Ƿ�����������P��";
CM_ SG_ 198 VCUCstFlg "����״̬λ";
CM_ SG_ 198 VCUCstRgnTqReq "������������Ŀ��Ť��";
CM_ SG_ 198 VCUCstRgnTqReqFA "The target regen torque of Front wheel for coasting energy recuperation.
ǰ���Ŀ�껬�л���Ť��";
CM_ SG_ 198 VCUCstRgnTqReqRA "The target regen torque of rear wheel for coasting recuperation energy.
���ֵ�Ŀ�����Ť��";
CM_ SG_ 198 VCUHVSt "High voltage state
��ѹ״̬";
CM_ SG_ 198 VCUHydTqReq "Hydraulic Brake Torque Request
��̤��ɲ";
CM_ SG_ 198 VCUHydTqReqVld "Qualifier for Hydraulic Brake Torque Request Signal
��̤��ɲͣҺѹ�ƶ�����������Чλ";
CM_ SG_ 198 VCULoSocLampReq "������ص�����";
CM_ SG_ 198 VCUMaxRgnTqAvl "maximum regeneration torque Available
�����û���Ť�� ǰ�������ܺ�";
CM_ SG_ 198 VCUMaxRgnTqAvlFA "The Max regen torque that can be available for front wheel.";
CM_ SG_ 198 VCUMaxRgnTqAvlFAVld "The invalid flag of  Max regen torque that can be available for front wheel.
ǰ�������û���Ť�ص���Чλ";
CM_ SG_ 198 VCUMaxRgnTqAvlRA "The Max regen torque that can be available for rear wheel.";
CM_ SG_ 198 VCUMaxRgnTqAvlRAVld "The invalid flag of Max regen torque that can be available for rear wheel.
���������û���Ť�ص���Чλ";
CM_ SG_ 198 VCUMaxRgnTqAvlVld "�����û���Ť����Ч��";
CM_ SG_ 198 VCUPedlTqOvrdAdsFlg "�������Override��־λ";
CM_ SG_ 198 VCUPrkgBtnPsdVld "��ʻԱ����P����Ч��";
CM_ SG_ 198 VCUVehMaxFltLvl "VCU Max Fault  Level
VCU�����ϵȼ�";
CM_ SG_ 198 WiprSpdModSts "����ٶ�״̬����";
CM_ SG_ 396 LRRSnsrStsFrmSFC "front center radar working status, bitfield
bit0=Misalignment
bit1=Blindness
bit2=HW failure
bit3=Emission off w/o failure
bit4=Not calibrated
bit5=Temp out of range
bit6=Reserved
bit7=Reserved
bit8=Reserved";
CM_ SG_ 434 DoorDrvrOutPwrRelsBtnSts "���ݲ�����ͷŰ�ť״̬";
CM_ SG_ 434 DoorDrvrPwrRelsDlyActv "���ݵ��ͷ��ӳټ����";
CM_ SG_ 434 DoorDrvrPwrRelsMotDrvSts "���ݵ��ͷŵ������״̬";
CM_ SG_ 434 DoorDrvrSts "��ʻ����״̬";
CM_ SG_ 434 DoorLeReOutPwrRelsBtnSts "��������ͷŰ�ť״̬";
CM_ SG_ 434 DoorLeRePwrRelsDlyActv "�����ͷ��ӳټ����";
CM_ SG_ 434 DoorLeReSts "������״̬";
CM_ SG_ 434 ExtrMirrFoldEnaFailr "����Ӿ��۵�����";
CM_ SG_ 434 ExtrMirrFoldSts "���Ӿ��۵�״̬";
CM_ SG_ 434 LeMirrFoldCmd "�������Ӿ��۵�����";
CM_ SG_ 434 SwsLinComFltSts "SWS LIN node communication fault status.";
CM_ SG_ 368 RLSRRCTBBrkReqFrmSFC "RCTB Brake request - rear left radar";
CM_ SG_ 368 RLSRRCTBTarDecelFrmSFC "target deceleration value from RCTB - rear left radar";
CM_ SG_ 391 RLSRBSDLCAStsFrmSFC "BSD_LCA Function status - rear left radar";
CM_ SG_ 391 RLSRBSDLCASwtFbFrmSFC "���״�BSD���ط�����Ϣ";
CM_ SG_ 391 RLSRBSDLCASwtUnavlRsnFrmSFC "���״�BSDLCA ���ز�����ԭ��";
CM_ SG_ 391 RLSRBSDLCAWarnReqFrmSFC "BSD_LCA warning request - rear left radar";
CM_ SG_ 391 RLSRDOWStsFrmSFC "DOW Function status - rear left radar";
CM_ SG_ 391 RLSRDOWSwtFbFrmSFC "���״�DOW���ط�����Ϣ";
CM_ SG_ 391 RLSRDOWSwtUnavlRsnFrmSFC "���״�DOW ���ز�����ԭ��";
CM_ SG_ 391 RLSRDOWWarnReqFrFrmSFC "DOW warning request - front left";
CM_ SG_ 391 RLSRDOWWarnReqReFrmSFC "DOW warning request - rear left";
CM_ SG_ 391 RLSRRCTABSwtFbFrmSFC "���״�RCTB���ط�����Ϣ";
CM_ SG_ 391 RLSRRCTABSwtUnavlRsnFrmSFC "���״�RCTA_RCTB ���ز�����ԭ��";
CM_ SG_ 391 RLSRRCTAStsFrmSFC "RCTA Function status - rear left radar";
CM_ SG_ 391 RLSRRCTAWarnReqFrmSFC "RCTA warning request - rear left radar";
CM_ SG_ 391 RLSRRCTBStsFrmSFC "RCTB Function status - rear left radar";
CM_ SG_ 391 RLSRRCTBWarnReqFrmSFC "RCTB warning request  - rear left radar";
CM_ SG_ 391 RLSRRCWStsFrmSFC "RCW Function status - rear left radar";
CM_ SG_ 391 RLSRRCWSwtFbFrmSFC "RCW switch feedback - rear left radar";
CM_ SG_ 391 RLSRRCWSwtUnavlRsnFrmSFC "���״�RCW ���ز�����ԭ��";
CM_ SG_ 391 RLSRRCWWarnReqFrmSFC "RCW warning request - rear left radar";
CM_ SG_ 701 RLSRSnsrStsFrmSFC "rear left radar working status, bitfield
bit0=Misalignment
bit1=Blindness
bit2=HW failure
bit3=Emission off w/o failure
bit4=Not calibrated
bit5=Temp out of range
bit6=Reserved
bit7=Reserved
bit8=Reserved";
CM_ SG_ 383 RRSRRCTBBrkReqFrmSFC "RCTB Brake request - rear right radar";
CM_ SG_ 383 RRSRRCTBTarDecelFrmSFC "target deceleration value from RCTB - rear right radar";
CM_ SG_ 392 RRSRBSDLCAStsFrmSFC "BSD_LCA Function status - rear right radar";
CM_ SG_ 392 RRSRBSDLCASwtFbFrmSFC "���״�BSD���ط�����Ϣ";
CM_ SG_ 392 RRSRBSDLCASwtUnavlRsnFrmSFC "���״�BSDLCA ���ز�����ԭ��";
CM_ SG_ 392 RRSRBSDLCAWarnReqFrmSFC "BSD_LCA warning request - rear right radar";
CM_ SG_ 392 RRSRDOWStsFrmSFC "DOW Function status - rear right radar";
CM_ SG_ 392 RRSRDOWSwtFbFrmSFC "���״�DOW���ط�����Ϣ";
CM_ SG_ 392 RRSRDOWSwtUnavlRsnFrmSFC "���״�DOW ���ز�����ԭ��";
CM_ SG_ 392 RRSRDOWWarnReqFrFrmSFC "DOW warning request - front right";
CM_ SG_ 392 RRSRDOWWarnReqReFrmSFC "DOW warning request - rear right";
CM_ SG_ 392 RRSRRCTABSwtFbFrmSFC "���״�RCTB���ط�����Ϣ";
CM_ SG_ 392 RRSRRCTABSwtUnavlRsnFrmSFC "���״�RCTA_RCTB ���ز�����ԭ��";
CM_ SG_ 392 RRSRRCTAStsFrmSFC "RCTA Function status - rear right radar";
CM_ SG_ 392 RRSRRCTAWarnReqFrmSFC "RCTA warning request - rear right radar";
CM_ SG_ 392 RRSRRCTBStsFrmSFC "RCTB Function status - rear right radar";
CM_ SG_ 392 RRSRRCTBWarnReqFrmSFC "RCTB warning request  - rear right radar";
CM_ SG_ 392 RRSRRCWStsFrmSFC "RCW Function status - rear right radar";
CM_ SG_ 392 RRSRRCWSwtFbFrmSFC "RCW switch feedback - rear right radar";
CM_ SG_ 392 RRSRRCWSwtUnavlRsnFrmSFC "���״�RCW ���ز�����ԭ��";
CM_ SG_ 392 RRSRRCWWarnReqFrmSFC "RCW warning request - rear right radar";
CM_ SG_ 523 RRSRSnsrStsFrmSFC "rear right radar working status, bitfield
bit0=Misalignment
bit1=Blindness
bit2=HW failure
bit3=Emission off w/o failure
bit4=Not calibrated
bit5=Temp out of range
bit6=Reserved
bit7=Reserved
bit8=Reserved";
CM_ SG_ 403 DoorRiRePwrRelsDlyActv "�Һ���ͷ��ӳټ����";
CM_ SG_ 403 DoorRiReSts "�Һ����״̬";
CM_ SG_ 403 RiMirrFoldCmd "�Ҳ�����Ӿ��۵�����";
CM_ SG_ 502 DoorPassOutPwrRelsBtnSts "���ݲ�����ͷŰ�ť״̬";
CM_ SG_ 502 DoorPassPwrRelsDlyActv "���ݵ��ͷ��ӳټ����";
CM_ SG_ 502 DoorPassSts "���ݲ���״̬";
CM_ SG_ 502 DoorRiReOutPwrRelsBtnSts "�Һ������ͷŰ�ť״̬";
CM_ SG_ 602 RlsFrntWinHum "ǰ���粣��ʪ��";
CM_ SG_ 602 RlsFrntWinT "ǰ���粣���¶�";
CM_ SG_ 602 RlsRainFallAmnt "����";
CM_ SG_ 602 RlsRainFallSts "����״̬";
CM_ SG_ 602 RlsRainSnsrFlt "��������������";
CM_ SG_ 602 RlsTHumSnsrFlt "�¶�ʪ�ȴ���������״̬";
CM_ SG_ 182 FrntLeCurHei "Front Left Current Height";
CM_ SG_ 182 FrntLeCurHeiSts "Front Left Current Height status";
CM_ SG_ 182 FrntRiCurHei "Front Right Current Height";
CM_ SG_ 182 FrntRiCurHeiSts "Front Right Current Height status";
CM_ SG_ 182 ReLeCurHei "Rear Left Current Height";
CM_ SG_ 182 ReLeCurHeiSts "Rear Left Current Height status";
CM_ SG_ 182 ReRiCurHei "Rear Right Current Height";
CM_ SG_ 182 ReRiCurHeiSts "Rear Right Current Height status";
CM_ SG_ 419 SwtIndcrRaw "��Ͽ���ת�����������";
CM_ SG_ 263 DateTiDay "date time day";
CM_ SG_ 263 DateTiHr "date time hour";
CM_ SG_ 263 DateTiMilsec "date time millisecond";
CM_ SG_ 263 DateTiMins "date time minute";
CM_ SG_ 263 DateTiMth "date time month";
CM_ SG_ 263 DateTiSec "date time second";
CM_ SG_ 263 DateTiYr "date time year";
CM_ SG_ 263 TiDomn "time domain";
CM_ SG_ 582 DCDSteerWhlExtrMirrHUDAdjFlg "DCD steering wheel and externel mirror and HUD adjust flag";
CM_ SG_ 582 OTAMode "OTAģʽ";
CM_ SG_ 720 DCDAvmCamTrigMod "DCD AVM��Ƶͬ��ģʽ";
CM_ SG_ 720 DCDDMSCameraFltSts "DMS camera fault Status
DMS����ͷ������Ϣ";
CM_ SG_ 720 DCDDMSdstrctnDetnSts "DCD DMS distraction  Detection status
���ļ�⿪��״̬";
CM_ SG_ 720 DCDDMSdstrctnSts "DCD DMS distraction status
���ĳ̶�";
CM_ SG_ 720 DCDDMSFatgDetnSts "DCD DMS fatigue Detection status
ƣ�ͼ�⿪��״̬";
CM_ SG_ 720 DCDDMSfatgSts "DCD DMS fatigue status
ƣ�ͳ̶�";
CM_ SG_ 720 DCDDMSSysFltSts "DMS system fault Status
DMSϵͳ������Ϣ";
CM_ SG_ 720 DCDDVRSrvReq "DCD DVR Service Request";
CM_ SG_ 720 DCDGameModSts "DCD Game Mode Status";
CM_ SG_ 720 DCDPrivacyModeStatus "һ����˽ģʽ״̬";
CM_ SG_ 720 DCDsentryModReq "DCD sentry mode request";
CM_ SG_ 720 DCDsentryModSts "DCD sentry mode status";
CM_ SG_ 720 DCDTSASLIFSwtSts "TSA-SLIF speed warning type status";
CM_ SG_ 720 DCDVehRunningTiAftLstChrgn "DCD vehicle running time after last charging";
CM_ SG_ 720 OTALinkMgr "OTA�������뱣��";
CM_ SG_ 720 SRMode "SRMode
SR״̬";
CM_ SG_ 720 VehRunngTiAftRdy "Vehicle running time after ready";
CM_ SG_ 833 ALCLrnSts "ALC  learn status";
CM_ SG_ 833 AVPLrnSts "AVP learn status";
CM_ SG_ 833 DCDAdCode "Address Code of current city.";
CM_ SG_ 833 DCDCameraSpdLim "Camera speed limit within 200m.";
CM_ SG_ 833 DCDNavSts "Navigation status.";
CM_ SG_ 833 DCDRoadClass "Current road class.";
CM_ SG_ 833 DCDRoadFacSpdLim "Road facility speed limit.";
CM_ SG_ 833 DCDRoadType "Type of current road. For detailed definition of signal value  please refer to Navigation SC.";
CM_ SG_ 833 DCDTrfcSts "Traffice status of current road segment.";
CM_ SG_ 833 DCDTSASlifSpdDisp "TSA SLIF speed display";
CM_ SG_ 833 DstUnitDisp "Unit of distance from DCD";
CM_ SG_ 833 HPPLrnSts "HPP  learn status";
CM_ SG_ 833 NOACtyLrnSts "NOA-City  learn status";
CM_ SG_ 833 NOAHWLrnSts "NOA-Highway learn status";
CM_ SG_ 833 PltLrnSts "Pilot  learn status";
CM_ SG_ 833 VehInsSpdDisp "Vehicle instantaneous speed display";
CM_ SG_ 833 VehInsSpdDispIntnal "Vehicle instantaneous speed display for internal";
CM_ SG_ 833 VehInsSpdDispVld "Vehicle instantaneous speed display Valid";
CM_ SG_ 837 DCDAcctMod "DCD Account Mode
�˺�ģʽ";
CM_ SG_ 837 DCDCloudSysnc "DCD Cloud Sysnc switch��ͬ������״̬";
CM_ SG_ 837 DCDGstMod "DCD Guest Mode";
CM_ SG_ 837 DCDICVehCustExperImprvProgSts "������ϵͳ�����û��Ľ��ƻ�����״̬
DCDICVehCustExperImprvProgSts Intelligent Connected Vehicle Customer Experience Improvement Program Status";
CM_ SG_ 837 DCDICVehSrvAuthntSts "������ϵͳ������Ȩ״̬
Intelligent Connected Vehicle  Service Authorization status";
CM_ SG_ 837 DCDUserIDBytePos0 "DCD UserID Position Byte 0";
CM_ SG_ 837 DCDUserIDBytePos1 "DCD UserID Position Byte 1";
CM_ SG_ 837 DCDUserIDBytePos10 "DCD UserID Position Byte 10";
CM_ SG_ 837 DCDUserIDBytePos11 "DCD UserID Position Byte 11";
CM_ SG_ 837 DCDUserIDBytePos12 "DCD UserID Position Byte 12";
CM_ SG_ 837 DCDUserIDBytePos13 "DCD UserID Position Byte 13";
CM_ SG_ 837 DCDUserIDBytePos14 "DCD UserID Position Byte 14";
CM_ SG_ 837 DCDUserIDBytePos15 "DCD UserID Position Byte 15";
CM_ SG_ 837 DCDUserIDBytePos2 "DCD UserID Position Byte 2";
CM_ SG_ 837 DCDUserIDBytePos3 "DCD UserID Position Byte 3";
CM_ SG_ 837 DCDUserIDBytePos4 "DCD UserID Position Byte 4";
CM_ SG_ 837 DCDUserIDBytePos5 "DCD UserID Position Byte 5";
CM_ SG_ 837 DCDUserIDBytePos6 "DCD UserID Position Byte 6";
CM_ SG_ 837 DCDUserIDBytePos7 "DCD UserID Position Byte 7";
CM_ SG_ 837 DCDUserIDBytePos8 "DCD UserID Position Byte 8";
CM_ SG_ 837 DCDUserIDBytePos9 "DCD UserID Position Byte 9";
CM_ SG_ 868 SetMgrAdsACCInitSpdSwt "SetMgr adas  ACC initial speed switch set";
CM_ SG_ 868 SetMgrAdsAEBFCWSwt "SetMgr adas AEB&FCW switch set";
CM_ SG_ 868 SetMgrAdsALCSwtSts "SetMgr adas  ALC switch set";
CM_ SG_ 868 SetMgrAdsAPA2SwtSts "SetMgr adas APA switch set2";
CM_ SG_ 868 SetMgrAdsAudModSwt "SetMgr adas audio mode  switch set";
CM_ SG_ 868 SetMgrAdsAutoTurnLiSwt "SetMgr Adas Auto Turn Light switch set";
CM_ SG_ 868 SetMgrAdsAVPSwtSts "SetMgr adas AVP  switch set";
CM_ SG_ 868 SetMgrAdsBSDLCASwt "SetMgr adas BSDLCA  switch set";
CM_ SG_ 868 SetMgrAdsDOWSwt "SetMgr adas  DOW switch set";
CM_ SG_ 868 SetMgrAdsELKSwSts "ELK function Switch status of personalize system memory";
CM_ SG_ 868 SetMgrAdsFxdSpdModValSwt "SetMgr adas  speed diviation level switch set";
CM_ SG_ 868 SetMgrAdsHPPBckGrLear "SetMgr adas  HPP back gear switch set";
CM_ SG_ 868 SetMgrAdsHPPSwtSts "SetMgr adas  HPP switch set";
CM_ SG_ 868 SetMgrAdsIntelgntSpdSwt "SetMgr Adas Intelligent Speed switch set";
CM_ SG_ 868 SetMgrAdsLaneChgCnfmSwt "SetMgr adas LaneChg confirm  switch set";
CM_ SG_ 868 SetMgrAdsLDWPSwt "SetMgr adas LDWP switch set";
CM_ SG_ 868 SetMgrAdsLDWPWarnTypSwt "SetMgr adas LDWP Warnning type switch set";
CM_ SG_ 868 SetMgrAdsMAISwtSts "SetMgr MAI switch";
CM_ SG_ 868 SetMgrAdsModSwt "SetMgr ADAS mode switch Status";
CM_ SG_ 868 SetMgrAdsNOAHWSwtSts "SetMgr adas  NOAHW switch set";
CM_ SG_ 868 SetMgrAdsNOAOddSwt "SetMgr ADAS - NOA odd switch Status";
CM_ SG_ 868 SetMgrAdsParkAudModSwt "SetMgr Adas park audio mode switch";
CM_ SG_ 868 SetMgrAdsParkSpdSwtSts "SetMgr adas parking speed switch set2";
CM_ SG_ 868 SetMgrAdsPcntgeSpdlvlSwt "SetMgr adas  Pcntge speed level switch set";
CM_ SG_ 868 SetMgrAdsPltSwtSts "SetMgr adas Plt  switch set";
CM_ SG_ 868 SetMgrAdsPntCldSwt "SetMgr adas Pnt cloud  switch set";
CM_ SG_ 868 SetMgrAdsRCTABSwt "SetMgr adas  RCTAB switch set";
CM_ SG_ 868 SetMgrAdsRCWSwt "SetMgr adas RCW switch set";
CM_ SG_ 868 SetMgrAdsTLASwt "The TLA  function switch status signal that Personalize setting system stored and transmitted  
���Ի�����ϵͳ�洢���ⷢ��TLA�Ĺ��ܿ���״̬�ź�";
CM_ SG_ 868 SetMgrAdsTrfcLiCtrlSwt "SetMgr ADAS Triffic Light Control Switch Status";
CM_ SG_ 868 SetMgrAdsVehDetourSwt "SetMgr ADAS Vehicle Detour Switch Status";
CM_ SG_ 868 SetMgrAdsVehSpdDvtnModSwt "SetMgr adas  vehicle speed diviation mode switch set";
CM_ SG_ 868 SetMgrDrvrSeldDstLvl "Setmgr driver select distance level";
CM_ SG_ 914 TotOdoAcrt "ODO";
CM_ SG_ 914 TotOdoAcrtLvlM "Total odometer accurate for meter level
�׼���ȷ�����
���У���Ч��Χ��0x0~0x?3B9AC9FF?����ʾ0~999,999,999";
CM_ SG_ 914 TotOdoAcrtLvlMVld "Total odometer accurate for meter level valid
�׼���ȷ�������Ч��";
CM_ SG_ 914 TotOdoAcrtVld "The valid signal of TotOdoAcrt";
CM_ SG_ 932 ADSAEBFCWSwtSet "�Զ������ƶ�����
AEB switch set";
CM_ SG_ 932 ADSAESESSSwtSet "�Զ�����ת����Ͽ���
AES_ESS switch set";
CM_ SG_ 932 ADSAPPOpenReq "�Ǽ����ĵ������";
CM_ SG_ 932 ADSBSDLCASwtSet "ä������뻻����������
ADS BSD LCA Switch Set";
CM_ SG_ 932 ADSDOWSwtSet "����Ԥ������
DOW Switch set";
CM_ SG_ 932 ADSPMAEBSwtSet "�������ײ������������
Parking And Maneuvering Automatic Emergency Brake switch Set";
CM_ SG_ 932 ADSRCWSwtSet "�󷽷�ײ��������
RCW Switch set";
CM_ SG_ 932 ADSTLASwtSet "ADS TLA Switch Set
�Ǽݺ��̵����ѿ���";
CM_ SG_ 932 ADSVcCtrlSwtSet "�������ƹ��ܿ���
ADS voice control switch set";
CM_ SG_ 932 APASwtSet "������������
APA Switch set";
CM_ SG_ 932 AVPSwtSet "���˴��Ͳ�������
AVP Switch set";
CM_ SG_ 932 DCD2RDParkinChoseButton "Driver Choose 2RD Parkin
���β�������";
CM_ SG_ 932 DCDACCInitSpdSwtSet "intelligent speed limit control  switch";
CM_ SG_ 932 DCDAdsAutoTurnLiSwtSet "DCD Adas Auto Turn Light switch set";
CM_ SG_ 932 DCDAdsIntelgntSpdSwtSet "DCD Adas Intelligent Speed switch set
���ܳ��ٿ�������";
CM_ SG_ 932 DCDADSMAISwtSet "Miss Acceleration Inhibition
�����������";
CM_ SG_ 932 DCDAdsModSwtSet "DCD Adas Mode Switch Set";
CM_ SG_ 932 DCDAdsNOAOddSwtSet "DCD Adas NOA ODD Switch Set";
CM_ SG_ 932 DCDADSRCTABSwtSet "RCTA and RCTB switch";
CM_ SG_ 932 DCDAdsTrfcLiCtrlSwtSet "DCD Adas Traffic Light Control Switch Set";
CM_ SG_ 932 DCDADSVcCtrlDstSet "Voice Control Distance Set";
CM_ SG_ 932 DCDADSVcCtrlSpdSet "Voice Control Speed Set";
CM_ SG_ 932 DCDAdsVehDeturSwtSet "DCD Adas Vehicle Detour Switch Set";
CM_ SG_ 932 DCDAPAButton "Driver Choose Start or Stop APA
�û�ѡ��ʼ��������ͣ����";
CM_ SG_ 932 DCDAPAParkOutButton "Driver Choose to Start Parking Out
�û�ѡ��ʼ����";
CM_ SG_ 932 DCDAPAParkOutDireSelect "Driver Choose ParkOut Direction
�û�ѡ�񲴳�����";
CM_ SG_ 932 DCDAPAParkSlotSelect "Driver Choose Target Park Slot
�û�ѡ��Ŀ�공λ";
CM_ SG_ 932 DCDAPAPIPOReq "Driver Choose APA Parkin Parkout
�û�ѡ�񲴳�����";
CM_ SG_ 932 DCDAPAQuitReq "Driver Choose Quit APA
�û������˳�����";
CM_ SG_ 932 DCDAPAVcCtl "APA Voice Control";
CM_ SG_ 932 DCDAudModSwtSet "ADS Audio Switch set";
CM_ SG_ 932 DCDAutoVehCustExperImprvProgSwt "���ܼ�ʻ�û�����Ľ��ƻ����� 
Autonomous Vehicle Customer Experience Improvement Program Switch";
CM_ SG_ 932 DCDAutoVehSrvAuthntSwt "���ܼ�ʻ������Ȩ  Autonomous Vehicle Service Authorization";
CM_ SG_ 932 DCDBackMapDfltParkSlotReq "��̨��Ĭͼʹ��Ĭ�ϳ�λ��������";
CM_ SG_ 932 DCDFxdSpdModValSwtSet "�̶�����ƫ����ֵ����
Fixed speed mode value switch";
CM_ SG_ 932 DCDHPPBckGrLearSwtSet "HPP background learn switch";
CM_ SG_ 932 DCDHPPBckGrPathAutDoLoSet "HPP path background auto download switch";
CM_ SG_ 932 DCDHPPChoseSaveRoute "·�߱��� �û�ѡ�񱣴����";
CM_ SG_ 932 DCDHPPLnVcReq "HPP Learn Voice Control Request";
CM_ SG_ 932 DCDHPPLrnReq "HPP Learn Request
HPP ѧϰ����";
CM_ SG_ 932 DCDHPPParkAlTheWay "��;��������";
CM_ SG_ 932 DCDHPPParkingButton "��;��������ʼ����";
CM_ SG_ 932 DCDHPPPrkReq "HPP Parking Request
HPP ��������";
CM_ SG_ 932 DCDLdwLdpWarnTypSwtSet "LDW And LDP warning type switch set
��������ϵͳ������������";
CM_ SG_ 932 DCDLVPwrSwtSet "Low power mode switch";
CM_ SG_ 932 DCDParkAudModSwtSet "DCD Parking Audio Mode Switch Set";
CM_ SG_ 932 DCDParkSpdSwtSet "DCD Park Speed Switch Setting
DCD�����ٶ�ѡ������";
CM_ SG_ 932 DCDPcntgeSpdModValSwtSet "�ٷֱȳ���ƫ����ֵ����
Percentage speed mode value switch";
CM_ SG_ 932 DCDPntCldSwtSet "Point cloud control  switch";
CM_ SG_ 932 DCDTouchdSpdTyp "DCD touched Speed Type";
CM_ SG_ 932 HPPSwtSet "���䲴������
HPP Switch set";
CM_ SG_ 932 HwNOASwtSet "����NOA���ܿ���
Highway NOA Switch set";
CM_ SG_ 932 LdwLdpSwtSet "����ƫ�뱨�� ����ƫ���ƫ����
LDW And LDP Switch set";
CM_ SG_ 932 LidarCloudMode "Lidar cloud mode feedback from SR";
CM_ SG_ 932 NoaLcSwtSet "���ȷ�Ϲ��ܿ���
NOA Lane Change Switch set";
CM_ SG_ 932 OutdoorPakinModeReq "�복������ʽ����";
CM_ SG_ 932 PltSwtALCSet "ת��Ʊ�����ܿ���
Pilot Switch ALC set";
CM_ SG_ 932 PltSwtSet "PILOT���ܿ���
Pilot Switch set";
CM_ SG_ 932 ScrnTouchdFuncChange "Screen Touched driving function change";
CM_ SG_ 932 ScrnTouchdLaneChange "Screen Touched lane change";
CM_ SG_ 932 ScrnTouchdSpd "�û�����п�����ֵ���пس���ֵ���ڵĳ��ٴ�С";
CM_ SG_ 932 ScrnTouchdSpdTyp "Screen Touched Speed Type";
CM_ SG_ 932 VehSpdDvtionModSwtSet "Vehicle speed divation mode switch";
CM_ SG_ 208 LockgCenLockTrigSrc "�п�������Դ";
CM_ SG_ 208 LockgDrvrDoorLockCmd "������������";
CM_ SG_ 1312 VCCDChassisCanfdActiveWakeup "Active Wakeup Bit";
CM_ SG_ 1312 VCCDChassisCanfdNodeAddress "Node source address";
CM_ SG_ 1312 VCCDChassisCanfdRepeatMsgReq "Repeat Message Request Bit";
CM_ SG_ 1312 VCCDChassisCanfdRepeatMsgSt "Repeat Message State indication";
BA_DEF_  "BaudRateCANFD" FLOAT 1000 10000000;
BA_DEF_  "Baudrate" INT 1000 1000000;
BA_DEF_  "BusType" STRING ;
BA_DEF_  "DBName" STRING ;
BA_DEF_  "ProtocolType" STRING ;
BA_DEF_ BU_  "NmAsrNode" ENUM  "No","Yes";
BA_DEF_ BO_  "CANFD_BRS" ENUM  "0","1";
BA_DEF_ BO_  "GenMsgCycleTime" INT 0 30000;
BA_DEF_ BO_  "GenMsgCycleTimeFast" INT 0 30000;
BA_DEF_ BO_  "GenMsgDelayTime" INT 0 100000;
BA_DEF_ BO_  "GenMsgNrOfRepetition" INT 0 100000;
BA_DEF_ BO_  "GenMsgSendType" ENUM  "cyclic","spontaneous","cyclicIfActive","spontaneousWithDelay","cyclicAndSpontaneous","cyclicAndSpontaneousWithDelay","IfActive","NoMsgSendType";
BA_DEF_ BO_  "GenMsgStartDelayTime" INT 0 100000;
BA_DEF_ BO_  "NmAsrBaseAddress" HEX 0 536870911;
BA_DEF_ BO_  "NmAsrMessage" ENUM  "No","Yes";
BA_DEF_ BO_  "VFrameFormat" ENUM  "StandardCAN","ExtendedCAN","reserved","J1939PG","reserved","reserved","reserved","reserved","reserved","reserved","reserved","reserved","reserved","reserved","StandardCAN_FD","ExtendedCAN_FD";
BA_DEF_ SG_  "GenSigSendType" ENUM  "Cyclic","OnWrite","OnWriteWithRepetition","OnChange","OnChangeWithRepetition","IfActive","IfActiveWithRepetition","NoSigSendType";
BA_DEF_ SG_  "GenSigStartValue" FLOAT -1.79769313486232E+308 1.84467440737096E+019;
BA_DEF_DEF_  "BaudRateCANFD" 1000;
BA_DEF_DEF_  "Baudrate" 1000;
BA_DEF_DEF_  "BusType" "CANFD";
BA_DEF_DEF_  "DBName" "";
BA_DEF_DEF_  "ProtocolType" "";
BA_DEF_DEF_  "NmAsrNode" "Yes";
BA_DEF_DEF_  "CANFD_BRS" "1";
BA_DEF_DEF_  "GenMsgCycleTime" 0;
BA_DEF_DEF_  "GenMsgCycleTimeFast" 0;
BA_DEF_DEF_  "GenMsgDelayTime" 0;
BA_DEF_DEF_  "GenMsgNrOfRepetition" 0;
BA_DEF_DEF_  "GenMsgSendType" "";
BA_DEF_DEF_  "GenMsgStartDelayTime" 0;
BA_DEF_DEF_  "NmAsrBaseAddress" 1280;
BA_DEF_DEF_  "NmAsrMessage" "No";
BA_DEF_DEF_  "VFrameFormat" "J1939PG";
BA_DEF_DEF_  "GenSigSendType" "Cyclic";
BA_DEF_DEF_  "GenSigStartValue" 0;
BA_ "ProtocolType" "CAN";
BA_ "BusType" "CAN FD";
BA_ "Baudrate" 500000;
BA_ "BaudRateCANFD" 2000000;
BA_ "DBName" "ADD_ChassisCANFD";
BA_ "GenMsgSendType" BO_ 341 0;
BA_ "GenMsgCycleTime" BO_ 341 20;
BA_ "VFrameFormat" BO_ 341 14;
BA_ "GenMsgSendType" BO_ 483 0;
BA_ "GenMsgCycleTime" BO_ 483 50;
BA_ "VFrameFormat" BO_ 483 14;
BA_ "GenMsgSendType" BO_ 769 0;
BA_ "GenMsgCycleTime" BO_ 769 100;
BA_ "VFrameFormat" BO_ 769 14;
BA_ "GenMsgSendType" BO_ 131 0;
BA_ "GenMsgCycleTime" BO_ 131 500;
BA_ "VFrameFormat" BO_ 131 14;
BA_ "GenMsgSendType" BO_ 177 0;
BA_ "GenMsgCycleTime" BO_ 177 10;
BA_ "VFrameFormat" BO_ 177 14;
BA_ "GenMsgSendType" BO_ 193 0;
BA_ "GenMsgCycleTime" BO_ 193 10;
BA_ "VFrameFormat" BO_ 193 14;
BA_ "GenMsgSendType" BO_ 237 0;
BA_ "GenMsgCycleTime" BO_ 237 50;
BA_ "VFrameFormat" BO_ 237 14;
BA_ "NmAsrMessage" BO_ 1329 1;
BA_ "VFrameFormat" BO_ 1329 0;
BA_ "GenMsgSendType" BO_ 1329 1;
BA_ "GenMsgDelayTime" BO_ 1329 20;
BA_ "NmAsrMessage" BO_ 1325 1;
BA_ "VFrameFormat" BO_ 1325 0;
BA_ "GenMsgSendType" BO_ 1325 1;
BA_ "GenMsgDelayTime" BO_ 1325 20;
BA_ "GenMsgSendType" BO_ 425 0;
BA_ "GenMsgCycleTime" BO_ 425 20;
BA_ "VFrameFormat" BO_ 425 14;
BA_ "GenMsgSendType" BO_ 426 0;
BA_ "GenMsgCycleTime" BO_ 426 20;
BA_ "VFrameFormat" BO_ 426 14;
BA_ "GenMsgSendType" BO_ 848 0;
BA_ "GenMsgCycleTime" BO_ 848 200;
BA_ "VFrameFormat" BO_ 848 14;
BA_ "GenMsgSendType" BO_ 849 4;
BA_ "GenMsgNrOfRepetition" BO_ 849 20;
BA_ "GenMsgCycleTimeFast" BO_ 849 20;
BA_ "GenMsgCycleTime" BO_ 849 200;
BA_ "VFrameFormat" BO_ 849 14;
BA_ "GenMsgSendType" BO_ 336 0;
BA_ "GenMsgCycleTime" BO_ 336 20;
BA_ "VFrameFormat" BO_ 336 14;
BA_ "GenMsgSendType" BO_ 337 0;
BA_ "GenMsgCycleTime" BO_ 337 20;
BA_ "VFrameFormat" BO_ 337 14;
BA_ "GenMsgSendType" BO_ 338 0;
BA_ "GenMsgCycleTime" BO_ 338 10;
BA_ "VFrameFormat" BO_ 338 14;
BA_ "GenMsgSendType" BO_ 352 0;
BA_ "GenMsgCycleTime" BO_ 352 20;
BA_ "VFrameFormat" BO_ 352 14;
BA_ "GenMsgSendType" BO_ 179 0;
BA_ "GenMsgCycleTime" BO_ 179 10;
BA_ "VFrameFormat" BO_ 179 14;
BA_ "GenMsgSendType" BO_ 226 0;
BA_ "GenMsgCycleTime" BO_ 226 10;
BA_ "VFrameFormat" BO_ 226 14;
BA_ "GenMsgSendType" BO_ 579 0;
BA_ "GenMsgCycleTime" BO_ 579 50;
BA_ "VFrameFormat" BO_ 579 14;
BA_ "GenMsgSendType" BO_ 353 0;
BA_ "GenMsgCycleTime" BO_ 353 20;
BA_ "VFrameFormat" BO_ 353 14;
BA_ "GenMsgSendType" BO_ 992 0;
BA_ "GenMsgCycleTime" BO_ 992 1000;
BA_ "VFrameFormat" BO_ 992 14;
BA_ "GenMsgSendType" BO_ 181 0;
BA_ "GenMsgCycleTime" BO_ 181 10;
BA_ "VFrameFormat" BO_ 181 14;
BA_ "GenMsgSendType" BO_ 343 0;
BA_ "GenMsgCycleTime" BO_ 343 20;
BA_ "VFrameFormat" BO_ 343 14;
BA_ "GenMsgSendType" BO_ 481 0;
BA_ "GenMsgCycleTime" BO_ 481 50;
BA_ "VFrameFormat" BO_ 481 14;
BA_ "GenMsgSendType" BO_ 514 0;
BA_ "GenMsgCycleTime" BO_ 514 50;
BA_ "VFrameFormat" BO_ 514 14;
BA_ "GenMsgSendType" BO_ 547 0;
BA_ "GenMsgCycleTime" BO_ 547 50;
BA_ "VFrameFormat" BO_ 547 14;
BA_ "GenMsgSendType" BO_ 724 0;
BA_ "GenMsgCycleTime" BO_ 724 100;
BA_ "VFrameFormat" BO_ 724 14;
BA_ "GenMsgSendType" BO_ 144 0;
BA_ "GenMsgCycleTime" BO_ 144 10;
BA_ "VFrameFormat" BO_ 144 14;
BA_ "GenMsgSendType" BO_ 195 0;
BA_ "GenMsgCycleTime" BO_ 195 10;
BA_ "VFrameFormat" BO_ 195 14;
BA_ "GenMsgSendType" BO_ 198 0;
BA_ "GenMsgCycleTime" BO_ 198 10;
BA_ "VFrameFormat" BO_ 198 14;
BA_ "GenMsgSendType" BO_ 396 0;
BA_ "GenMsgCycleTime" BO_ 396 50;
BA_ "VFrameFormat" BO_ 396 14;
BA_ "GenMsgSendType" BO_ 434 0;
BA_ "GenMsgCycleTime" BO_ 434 20;
BA_ "VFrameFormat" BO_ 434 14;
BA_ "GenMsgSendType" BO_ 368 0;
BA_ "GenMsgCycleTime" BO_ 368 20;
BA_ "VFrameFormat" BO_ 368 14;
BA_ "GenMsgSendType" BO_ 391 0;
BA_ "GenMsgCycleTime" BO_ 391 100;
BA_ "VFrameFormat" BO_ 391 14;
BA_ "GenMsgSendType" BO_ 701 0;
BA_ "GenMsgCycleTime" BO_ 701 50;
BA_ "VFrameFormat" BO_ 701 14;
BA_ "GenMsgSendType" BO_ 383 0;
BA_ "GenMsgCycleTime" BO_ 383 20;
BA_ "VFrameFormat" BO_ 383 14;
BA_ "GenMsgSendType" BO_ 392 0;
BA_ "GenMsgCycleTime" BO_ 392 100;
BA_ "VFrameFormat" BO_ 392 14;
BA_ "GenMsgSendType" BO_ 523 0;
BA_ "GenMsgCycleTime" BO_ 523 50;
BA_ "VFrameFormat" BO_ 523 14;
BA_ "GenMsgSendType" BO_ 403 0;
BA_ "GenMsgCycleTime" BO_ 403 20;
BA_ "VFrameFormat" BO_ 403 14;
BA_ "GenMsgSendType" BO_ 502 0;
BA_ "GenMsgCycleTime" BO_ 502 20;
BA_ "VFrameFormat" BO_ 502 14;
BA_ "GenMsgSendType" BO_ 602 0;
BA_ "GenMsgCycleTime" BO_ 602 50;
BA_ "VFrameFormat" BO_ 602 14;
BA_ "GenMsgSendType" BO_ 182 0;
BA_ "GenMsgCycleTime" BO_ 182 10;
BA_ "VFrameFormat" BO_ 182 14;
BA_ "GenMsgSendType" BO_ 419 0;
BA_ "GenMsgCycleTime" BO_ 419 20;
BA_ "VFrameFormat" BO_ 419 14;
BA_ "GenMsgSendType" BO_ 263 0;
BA_ "GenMsgCycleTime" BO_ 263 100;
BA_ "VFrameFormat" BO_ 263 14;
BA_ "GenMsgSendType" BO_ 582 0;
BA_ "GenMsgCycleTime" BO_ 582 50;
BA_ "VFrameFormat" BO_ 582 14;
BA_ "GenMsgSendType" BO_ 720 0;
BA_ "GenMsgCycleTime" BO_ 720 100;
BA_ "VFrameFormat" BO_ 720 14;
BA_ "GenMsgSendType" BO_ 833 0;
BA_ "GenMsgCycleTime" BO_ 833 200;
BA_ "VFrameFormat" BO_ 833 14;
BA_ "GenMsgSendType" BO_ 837 0;
BA_ "GenMsgCycleTime" BO_ 837 200;
BA_ "VFrameFormat" BO_ 837 14;
BA_ "GenMsgSendType" BO_ 868 0;
BA_ "GenMsgCycleTime" BO_ 868 100;
BA_ "VFrameFormat" BO_ 868 14;
BA_ "GenMsgSendType" BO_ 914 0;
BA_ "GenMsgCycleTime" BO_ 914 500;
BA_ "VFrameFormat" BO_ 914 14;
BA_ "GenMsgSendType" BO_ 932 4;
BA_ "GenMsgNrOfRepetition" BO_ 932 3;
BA_ "GenMsgCycleTimeFast" BO_ 932 40;
BA_ "GenMsgCycleTime" BO_ 932 1000;
BA_ "VFrameFormat" BO_ 932 14;
BA_ "GenMsgSendType" BO_ 208 0;
BA_ "GenMsgCycleTime" BO_ 208 10;
BA_ "VFrameFormat" BO_ 208 14;
BA_ "NmAsrMessage" BO_ 1312 1;
BA_ "VFrameFormat" BO_ 1312 0;
BA_ "GenMsgSendType" BO_ 1312 1;
BA_ "GenMsgDelayTime" BO_ 1312 20;
BA_ "GenSigStartValue" SG_ 341 PASVlcTarAccFromPASMainFrmADD 1000;
BA_ "GenSigStartValue" SG_ 177 ADSAEBTarDecelFrmADD 512;
BA_ "GenSigStartValue" SG_ 177 ADSMAIAccrPerReqFrmADD 100;
BA_ "GenSigStartValue" SG_ 177 DrvAxTarReqMainFrmADD 20480;
BA_ "GenSigStartValue" SG_ 177 DrvPinStrAglReqValFrmADD 16384;
BA_ "GenSigStartValue" SG_ 177 DrvSteerWhlTqLimFrmADD 1024;
BA_ "GenSigStartValue" SG_ 193 ADASParkDrvVehWheelTqReqFrmADD 30000;
BA_ "GenSigStartValue" SG_ 193 ADSTqTarReqMainFrmADD 30000;
BA_ "GenSigSendType" SG_ 1329 ADDChassisCanfdActiveWakeup 1;
BA_ "GenSigSendType" SG_ 1329 ADDChassisCanfdNodeAddress 1;
BA_ "GenSigSendType" SG_ 1329 ADDChassisCanfdRepeatMsgReq 1;
BA_ "GenSigSendType" SG_ 1329 ADDChassisCanfdRepeatMsgSt 1;
BA_ "GenSigSendType" SG_ 1329 NMKeepAwkRsnADD 1;
BA_ "GenSigSendType" SG_ 1329 UDB17ADD 1;
BA_ "GenSigSendType" SG_ 1329 UDB18ADD 1;
BA_ "GenSigSendType" SG_ 1329 UDB19ADD 1;
BA_ "GenSigSendType" SG_ 1329 UDB20ADD 1;
BA_ "GenSigSendType" SG_ 1329 UDB21ADD 1;
BA_ "GenSigSendType" SG_ 1329 UDB22ADD 1;
BA_ "GenSigSendType" SG_ 1329 UDB23ADD 1;
BA_ "GenSigSendType" SG_ 1329 UDB24ADD 1;
BA_ "GenSigSendType" SG_ 1329 UDB25ADD 1;
BA_ "GenSigSendType" SG_ 1329 UDB26ADD 1;
BA_ "GenSigSendType" SG_ 1329 UDB27ADD 1;
BA_ "GenSigSendType" SG_ 1329 UDB28ADD 1;
BA_ "GenSigSendType" SG_ 1329 UDB29ADD 1;
BA_ "GenSigSendType" SG_ 1329 UDB30ADD 1;
BA_ "GenSigSendType" SG_ 1329 UDB31ADD 1;
BA_ "GenSigSendType" SG_ 1329 UDB32ADD 1;
BA_ "GenSigSendType" SG_ 1329 UDB33ADD 1;
BA_ "GenSigSendType" SG_ 1329 UDB34ADD 1;
BA_ "GenSigSendType" SG_ 1329 UDB35ADD 1;
BA_ "GenSigSendType" SG_ 1329 UDB36ADD 1;
BA_ "GenSigSendType" SG_ 1329 UDB37ADD 1;
BA_ "GenSigSendType" SG_ 1329 UDB38ADD 1;
BA_ "GenSigSendType" SG_ 1329 UDB39ADD 1;
BA_ "GenSigSendType" SG_ 1329 UDB40ADD 1;
BA_ "GenSigSendType" SG_ 1329 UDB41ADD 1;
BA_ "GenSigSendType" SG_ 1329 UDB42ADD 1;
BA_ "GenSigSendType" SG_ 1329 UDB43ADD 1;
BA_ "GenSigSendType" SG_ 1329 UDB44ADD 1;
BA_ "GenSigSendType" SG_ 1329 UDB45ADD 1;
BA_ "GenSigSendType" SG_ 1329 UDB46ADD 1;
BA_ "GenSigSendType" SG_ 1329 UDB47ADD 1;
BA_ "GenSigSendType" SG_ 1325 ADDChassisCanfdActiveWakeup1 1;
BA_ "GenSigSendType" SG_ 1325 ADDChassisCanfdNodeAddress1 1;
BA_ "GenSigSendType" SG_ 1325 ADDChassisCanfdRepeatMsgReq1 1;
BA_ "GenSigSendType" SG_ 1325 ADDChassisCanfdRepeatMsgSt1 1;
BA_ "GenSigSendType" SG_ 1325 NMKeepAwkRsnADD 1;
BA_ "GenSigSendType" SG_ 1325 UDB17ADD 1;
BA_ "GenSigSendType" SG_ 1325 UDB18ADD 1;
BA_ "GenSigSendType" SG_ 1325 UDB19ADD 1;
BA_ "GenSigSendType" SG_ 1325 UDB20ADD 1;
BA_ "GenSigSendType" SG_ 1325 UDB21ADD 1;
BA_ "GenSigSendType" SG_ 1325 UDB22ADD 1;
BA_ "GenSigSendType" SG_ 1325 UDB23ADD 1;
BA_ "GenSigSendType" SG_ 1325 UDB24ADD 1;
BA_ "GenSigSendType" SG_ 1325 UDB25ADD 1;
BA_ "GenSigSendType" SG_ 1325 UDB26ADD 1;
BA_ "GenSigSendType" SG_ 1325 UDB27ADD 1;
BA_ "GenSigSendType" SG_ 1325 UDB28ADD 1;
BA_ "GenSigSendType" SG_ 1325 UDB29ADD 1;
BA_ "GenSigSendType" SG_ 1325 UDB30ADD 1;
BA_ "GenSigSendType" SG_ 1325 UDB31ADD 1;
BA_ "GenSigSendType" SG_ 1325 UDB32ADD 1;
BA_ "GenSigSendType" SG_ 1325 UDB33ADD 1;
BA_ "GenSigSendType" SG_ 1325 UDB34ADD 1;
BA_ "GenSigSendType" SG_ 1325 UDB35ADD 1;
BA_ "GenSigSendType" SG_ 1325 UDB36ADD 1;
BA_ "GenSigSendType" SG_ 1325 UDB37ADD 1;
BA_ "GenSigSendType" SG_ 1325 UDB38ADD 1;
BA_ "GenSigSendType" SG_ 1325 UDB39ADD 1;
BA_ "GenSigSendType" SG_ 1325 UDB40ADD 1;
BA_ "GenSigSendType" SG_ 1325 UDB41ADD 1;
BA_ "GenSigSendType" SG_ 1325 UDB42ADD 1;
BA_ "GenSigSendType" SG_ 1325 UDB43ADD 1;
BA_ "GenSigSendType" SG_ 1325 UDB44ADD 1;
BA_ "GenSigSendType" SG_ 1325 UDB45ADD 1;
BA_ "GenSigSendType" SG_ 1325 UDB46ADD 1;
BA_ "GenSigSendType" SG_ 1325 UDB47ADD 1;
BA_ "GenSigStartValue" SG_ 425 LonAccr 25000;
BA_ "GenSigStartValue" SG_ 425 LonSnsrSt 1;
BA_ "GenSigStartValue" SG_ 426 LatAccr 25000;
BA_ "GenSigStartValue" SG_ 426 LatAccrSt 1;
BA_ "GenSigStartValue" SG_ 426 YawRate 30000;
BA_ "GenSigStartValue" SG_ 426 YawRateSnsrSt 1;
BA_ "GenSigSendType" SG_ 849 ImpctEvntSts 1;
BA_ "GenSigSendType" SG_ 849 ImpctEvntStsSigGrpChks 1;
BA_ "GenSigSendType" SG_ 849 ImpctEvntStsSigGrpCntr 1;
BA_ "GenSigStartValue" SG_ 336 BCPMstCylP 100;
BA_ "GenSigStartValue" SG_ 336 BCPSimulatorP 100;
BA_ "GenSigStartValue" SG_ 336 InpRodStk 100;
BA_ "GenSigStartValue" SG_ 337 EstimdSumOfVehHydBrkEachWhl 31250;
BA_ "GenSigStartValue" SG_ 338 BiasMaxFrntAxle 100;
BA_ "GenSigStartValue" SG_ 338 BiasMaxReAxle 100;
BA_ "GenSigStartValue" SG_ 338 TarRdcdPtTqFA 30000;
BA_ "GenSigStartValue" SG_ 338 TarRdcdPtTqRA 30000;
BA_ "GenSigStartValue" SG_ 338 TarRecuTqReq 32767;
BA_ "GenSigStartValue" SG_ 352 BrkDiscTFrntLe 20;
BA_ "GenSigStartValue" SG_ 352 BrkDiscTFrntRi 20;
BA_ "GenSigStartValue" SG_ 352 BrkDiscTReLe 20;
BA_ "GenSigStartValue" SG_ 352 BrkDiscTReRi 20;
BA_ "GenSigStartValue" SG_ 352 RgnTqCorrnOffs2 100;
BA_ "GenSigStartValue" SG_ 352 RgnTqCorrnOffs5 1000;
BA_ "GenSigStartValue" SG_ 352 RgnTqCorrnOffs6 1000;
BA_ "GenSigStartValue" SG_ 352 RgnTqCorrnOffs7 1000;
BA_ "GenSigStartValue" SG_ 579 BattSocRaw 800;
BA_ "GenSigStartValue" SG_ 579 BattURaw 13200;
BA_ "GenSigStartValue" SG_ 992 CwEOTValue 12480;
BA_ "GenSigStartValue" SG_ 343 VCULatSlopForDisp 450;
BA_ "GenSigStartValue" SG_ 343 VCULgtSlopForDisp 450;
BA_ "GenSigStartValue" SG_ 144 VCUFrntEmTqRdy 1;
BA_ "GenSigStartValue" SG_ 144 VCUReEmTqRdy 1;
BA_ "GenSigStartValue" SG_ 198 VCUADASDrvrWhlTqReq 30000;
BA_ "GenSigStartValue" SG_ 198 VCUCstRgnTqReq 16383;
BA_ "GenSigStartValue" SG_ 198 VCUCstRgnTqReqFA 16383;
BA_ "GenSigStartValue" SG_ 198 VCUCstRgnTqReqRA 16383;
BA_ "GenSigStartValue" SG_ 434 DoorDrvrOutPwrRelsBtnSts 1;
BA_ "GenSigStartValue" SG_ 434 DoorLeReOutPwrRelsBtnSts 1;
BA_ "GenSigStartValue" SG_ 368 RLSRRCTBTarDecelFrmSFC 200;
BA_ "GenSigStartValue" SG_ 383 RRSRRCTBTarDecelFrmSFC 200;
BA_ "GenSigStartValue" SG_ 502 DoorPassOutPwrRelsBtnSts 1;
BA_ "GenSigStartValue" SG_ 502 DoorRiReOutPwrRelsBtnSts 1;
BA_ "GenSigStartValue" SG_ 182 FrntLeCurHei 127;
BA_ "GenSigStartValue" SG_ 182 FrntRiCurHei 127;
BA_ "GenSigStartValue" SG_ 182 ReLeCurHei 127;
BA_ "GenSigStartValue" SG_ 182 ReRiCurHei 127;
BA_ "GenSigStartValue" SG_ 263 DateTiHr 24;
BA_ "GenSigStartValue" SG_ 263 DateTiMilsec 1000;
BA_ "GenSigStartValue" SG_ 263 DateTiMins 60;
BA_ "GenSigStartValue" SG_ 263 DateTiSec 60;
BA_ "GenSigStartValue" SG_ 833 DCDRoadFacSpdLim 255;
BA_ "GenSigSendType" SG_ 932 ADSAEBFCWSwtSet 1;
BA_ "GenSigSendType" SG_ 932 ADSAESESSSwtSet 1;
BA_ "GenSigSendType" SG_ 932 ADSAPPOpenReq 1;
BA_ "GenSigSendType" SG_ 932 ADSBSDLCASwtSet 1;
BA_ "GenSigSendType" SG_ 932 ADSDOWSwtSet 1;
BA_ "GenSigSendType" SG_ 932 ADSPMAEBSwtSet 1;
BA_ "GenSigSendType" SG_ 932 ADSRCWSwtSet 1;
BA_ "GenSigSendType" SG_ 932 ADSTLASwtSet 1;
BA_ "GenSigSendType" SG_ 932 ADSVcCtrlSwtSet 1;
BA_ "GenSigSendType" SG_ 932 APASwtSet 1;
BA_ "GenSigSendType" SG_ 932 AVPSwtSet 1;
BA_ "GenSigSendType" SG_ 932 DCD2RDParkinChoseButton 1;
BA_ "GenSigSendType" SG_ 932 DCDACCInitSpdSwtSet 1;
BA_ "GenSigSendType" SG_ 932 DCDAdsAutoTurnLiSwtSet 1;
BA_ "GenSigSendType" SG_ 932 DCDAdsIntelgntSpdSwtSet 1;
BA_ "GenSigSendType" SG_ 932 DCDADSMAISwtSet 1;
BA_ "GenSigSendType" SG_ 932 DCDAdsModSwtSet 1;
BA_ "GenSigSendType" SG_ 932 DCDAdsNOAOddSwtSet 1;
BA_ "GenSigSendType" SG_ 932 DCDADSRCTABSwtSet 1;
BA_ "GenSigSendType" SG_ 932 DCDAdsTrfcLiCtrlSwtSet 1;
BA_ "GenSigSendType" SG_ 932 DCDADSVcCtrlDstSet 1;
BA_ "GenSigSendType" SG_ 932 DCDADSVcCtrlSpdSet 1;
BA_ "GenSigSendType" SG_ 932 DCDAdsVehDeturSwtSet 1;
BA_ "GenSigSendType" SG_ 932 DCDAPAButton 1;
BA_ "GenSigSendType" SG_ 932 DCDAPAParkOutButton 1;
BA_ "GenSigSendType" SG_ 932 DCDAPAParkOutDireSelect 1;
BA_ "GenSigSendType" SG_ 932 DCDAPAParkSlotSelect 1;
BA_ "GenSigSendType" SG_ 932 DCDAPAPIPOReq 1;
BA_ "GenSigSendType" SG_ 932 DCDAPAQuitReq 1;
BA_ "GenSigSendType" SG_ 932 DCDAPAVcCtl 1;
BA_ "GenSigSendType" SG_ 932 DCDAudModSwtSet 1;
BA_ "GenSigSendType" SG_ 932 DCDAutoVehCustExperImprvProgSwt 1;
BA_ "GenSigSendType" SG_ 932 DCDAutoVehSrvAuthntSwt 1;
BA_ "GenSigSendType" SG_ 932 DCDBackMapDfltParkSlotReq 1;
BA_ "GenSigSendType" SG_ 932 DCDFxdSpdModValSwtSet 1;
BA_ "GenSigSendType" SG_ 932 DCDHPPBckGrLearSwtSet 1;
BA_ "GenSigSendType" SG_ 932 DCDHPPBckGrPathAutDoLoSet 1;
BA_ "GenSigSendType" SG_ 932 DCDHPPChoseSaveRoute 1;
BA_ "GenSigSendType" SG_ 932 DCDHPPLnVcReq 1;
BA_ "GenSigSendType" SG_ 932 DCDHPPLrnReq 1;
BA_ "GenSigSendType" SG_ 932 DCDHPPParkAlTheWay 1;
BA_ "GenSigSendType" SG_ 932 DCDHPPParkingButton 1;
BA_ "GenSigSendType" SG_ 932 DCDHPPPrkReq 1;
BA_ "GenSigSendType" SG_ 932 DCDLdwLdpWarnTypSwtSet 1;
BA_ "GenSigSendType" SG_ 932 DCDLVPwrSwtSet 1;
BA_ "GenSigSendType" SG_ 932 DCDParkAudModSwtSet 1;
BA_ "GenSigSendType" SG_ 932 DCDParkSpdSwtSet 1;
BA_ "GenSigSendType" SG_ 932 DCDPcntgeSpdModValSwtSet 1;
BA_ "GenSigSendType" SG_ 932 DCDPntCldSwtSet 1;
BA_ "GenSigSendType" SG_ 932 DCDTouchdSpdTyp 1;
BA_ "GenSigSendType" SG_ 932 HPPSwtSet 1;
BA_ "GenSigSendType" SG_ 932 HwNOASwtSet 1;
BA_ "GenSigSendType" SG_ 932 LdwLdpSwtSet 1;
BA_ "GenSigSendType" SG_ 932 LidarCloudMode 1;
BA_ "GenSigSendType" SG_ 932 NoaLcSwtSet 1;
BA_ "GenSigSendType" SG_ 932 OutdoorPakinModeReq 1;
BA_ "GenSigSendType" SG_ 932 PltSwtALCSet 1;
BA_ "GenSigSendType" SG_ 932 PltSwtSet 1;
BA_ "GenSigSendType" SG_ 932 ScrnTouchdFuncChange 1;
BA_ "GenSigSendType" SG_ 932 ScrnTouchdLaneChange 1;
BA_ "GenSigSendType" SG_ 932 ScrnTouchdSpd 1;
BA_ "GenSigSendType" SG_ 932 ScrnTouchdSpdTyp 1;
BA_ "GenSigSendType" SG_ 932 VehSpdDvtionModSwtSet 1;
BA_ "GenSigSendType" SG_ 1312 NMKeepAwkRsnVCCD 1;
BA_ "GenSigSendType" SG_ 1312 UDB17VCCD 1;
BA_ "GenSigSendType" SG_ 1312 UDB18VCCD 1;
BA_ "GenSigSendType" SG_ 1312 UDB19VCCD 1;
BA_ "GenSigSendType" SG_ 1312 UDB20VCCD 1;
BA_ "GenSigSendType" SG_ 1312 UDB21VCCD 1;
BA_ "GenSigSendType" SG_ 1312 UDB22VCCD 1;
BA_ "GenSigSendType" SG_ 1312 UDB23VCCD 1;
BA_ "GenSigSendType" SG_ 1312 UDB24VCCD 1;
BA_ "GenSigSendType" SG_ 1312 UDB25VCCD 1;
BA_ "GenSigSendType" SG_ 1312 UDB26VCCD 1;
BA_ "GenSigSendType" SG_ 1312 UDB27VCCD 1;
BA_ "GenSigSendType" SG_ 1312 UDB28VCCD 1;
BA_ "GenSigSendType" SG_ 1312 UDB29VCCD 1;
BA_ "GenSigSendType" SG_ 1312 UDB30VCCD 1;
BA_ "GenSigSendType" SG_ 1312 UDB31VCCD 1;
BA_ "GenSigSendType" SG_ 1312 UDB32VCCD 1;
BA_ "GenSigSendType" SG_ 1312 UDB33VCCD 1;
BA_ "GenSigSendType" SG_ 1312 UDB34VCCD 1;
BA_ "GenSigSendType" SG_ 1312 UDB35VCCD 1;
BA_ "GenSigSendType" SG_ 1312 UDB36VCCD 1;
BA_ "GenSigSendType" SG_ 1312 UDB37VCCD 1;
BA_ "GenSigSendType" SG_ 1312 UDB38VCCD 1;
BA_ "GenSigSendType" SG_ 1312 UDB39VCCD 1;
BA_ "GenSigSendType" SG_ 1312 UDB40VCCD 1;
BA_ "GenSigSendType" SG_ 1312 UDB41VCCD 1;
BA_ "GenSigSendType" SG_ 1312 UDB42VCCD 1;
BA_ "GenSigSendType" SG_ 1312 UDB43VCCD 1;
BA_ "GenSigSendType" SG_ 1312 UDB44VCCD 1;
BA_ "GenSigSendType" SG_ 1312 UDB45VCCD 1;
BA_ "GenSigSendType" SG_ 1312 UDB46VCCD 1;
BA_ "GenSigSendType" SG_ 1312 UDB47VCCD 1;
BA_ "GenSigSendType" SG_ 1312 UDB49VCCD 1;
BA_ "GenSigSendType" SG_ 1312 UDB50VCCD 1;
BA_ "GenSigSendType" SG_ 1312 UDB51VCCD 1;
BA_ "GenSigSendType" SG_ 1312 UDB52VCCD 1;
BA_ "GenSigSendType" SG_ 1312 UDB53VCCD 1;
BA_ "GenSigSendType" SG_ 1312 VCCDChassisCanfdActiveWakeup 1;
BA_ "GenSigSendType" SG_ 1312 VCCDChassisCanfdNodeAddress 1;
BA_ "GenSigSendType" SG_ 1312 VCCDChassisCanfdRepeatMsgReq 1;
BA_ "GenSigSendType" SG_ 1312 VCCDChassisCanfdRepeatMsgSt 1;
VAL_ 341 HPPAVPRecoverIndCtrl 0 "No_Request" 1 "Request" ;
VAL_ 341 HPPAVPSteerWhlCtrlReqSts 0 "NoRequest" 1 "Ready" 2 "active" 3 "Failure" ;
VAL_ 341 ParkAPBReqMainFrmADD 0 "no_request" 1 "Request_Release" 2 "Request_Closed" ;
VAL_ 341 ParkEPSLateralCtrlTypeFrmADD 0 "Inhibited" 1 "APA_RPA" 2 "HPP_AVP" ;
VAL_ 341 ParkRecoverIndCtrlFrmADD 0 "No_Request" 1 "Request" 2 "Reserved" 3 "Reserved" ;
VAL_ 341 ParkSteerWhlCtrlReqStsFrmADD 0 "NoRequest" 1 "Ready" 2 "active" 3 "Failure" ;
VAL_ 341 PASBrkFcnModMainFrmADD 0 "None" 1 "APA" 2 "RPA" 3 "HPP" 4 "AVP" 5 "DynamicAVP" ;
VAL_ 341 PASEmgyBrkReqMainFrmADD 0 "No_request" 1 "Request" ;
VAL_ 341 PASReqAccCtrlEnaMainFrmADD 0 "Disable" 1 "Enable" ;
VAL_ 341 PASReqBrkPrfeMainFrmADD 0 "No_request" 1 "Request" ;
VAL_ 341 PASReqDclUtiStslMainFrmADD 0 "No_request" 1 "Request" ;
VAL_ 341 PASReqDrvOffMainFrmADD 0 "No_request" 1 "Request" ;
VAL_ 341 PASShdModReqMainFrmADD 0 "No_Request" 1 "Soft_Off" 2 "Fast_Off" 3 "Immediate_Off" ;
VAL_ 483 ADSBSDLCAEnableForSRR 0 "Off" 1 "On" ;
VAL_ 483 ADSDOWEnableForSRR 0 "Off" 1 "On" ;
VAL_ 483 ADSRCTABEnableForSRR 0 "Off" 1 "Warning" 2 "Warning_Brake" ;
VAL_ 483 ADSRCWEnableForSRR 0 "Off" 1 "On" ;
VAL_ 483 GroundAdhereType 0 "Unknow" 1 "Ice" 2 "Snow" 3 "Water" 4 "Other" ;
VAL_ 483 GroundLayingType 0 "Unknow" 1 "Bituminous" 2 "Epoxy" 3 "Cement" 4 "Unsurfaced" 5 "Other" ;
VAL_ 769 ACCInitSpdSwtFbFrmADD 0 "default" 1 "limit_speed_all_gray" 2 "Current_Veh_Spd" 3 "Current_Spd_Lmt" 4 "unavailable" ;
VAL_ 769 ACCInitSpdSwtUnavlRsnFrmADD 0 "default" 1 "No_reason_req" 2 "location_permissions_restricted" 3 "other_reasons" 4 "Error_detected" ;
VAL_ 769 ADSAEBFCWSwtFbFrmADD 0 "default" 1 "Off" 2 "early" 3 "middle" 4 "late" 5 "unavailable" ;
VAL_ 769 ADSAEBSwtUnavlRsnFrmADD 0 "default" 1 "No_reason_req" 2 "not_P_gear" 3 "account_not_log_in" 4 "not_authorized" 5 "not_learned" 6 "privacy_mode" 7 "extreme_eco_mode" 8 "lowpower_mode" 9 "function_active" 10 "other_reasons" 11 "Error_Detected" ;
VAL_ 769 ADSAESESSSwtFbFrmADD 0 "default" 1 "Off" 2 "ON" 3 "unavailable" ;
VAL_ 769 ADSAudModSwtStsFrmADD 0 "default" 1 "Off" 2 "Escort" 3 "Normal" 4 "Simple" 5 "unavailable" ;
VAL_ 769 ADSBSDLCASwtFbFrmADD 0 "default" 1 "unavailable" 2 "Off" 3 "AudWarning" 4 "HptcWarning" 5 "LightWarning" ;
VAL_ 769 ADSBSDLCASwtUnavlRsnFrmADD 0 "default" 1 "No_reason_req" 2 "not_P_gear" 3 "account_not_log_in" 4 "not_authorized" 5 "not_learned" 6 "privacy_mode" 7 "extreme_eco_mode" 8 "lowpower_mode" 9 "function_active" 10 "other_reasons" 11 "Error_Detected" ;
VAL_ 769 ADSDOWSwtFbFrmADD 0 "default" 1 "Off" 2 "Warning" 3 "Delay_open" 4 "unavailable" ;
VAL_ 769 ADSDOWSwtUnavlRsnFrmADD 0 "default" 1 "No_reason_req" 2 "not_P_gear" 3 "account_not_log_in" 4 "not_authorized" 5 "not_learned" 6 "privacy_mode" 7 "extreme_eco_mode" 8 "lowpower_mode" 9 "function_active" 10 "other_reasons" 11 "Error_Detected" ;
VAL_ 769 ADSELKSwtFbFrmADD 0 "default" 1 "Off" 2 "middle" 3 "high" 4 "unavailable" ;
VAL_ 769 ADSELKSwtUnavlRsnFrmADD 0 "default" 1 "No_reason_req" 2 "not_P_gear" 3 "account_not_log_in" 4 "not_authorized" 5 "not_learned" 6 "privacy_mode" 7 "extreme_eco_mode" 8 "lowpower_mode" 9 "function_active" 10 "other_reasons" 11 "Error_Detected" ;
VAL_ 769 ADSLDPWarnTypSwtUnavlRsnFrmADD 0 "default" 1 "No_reason_req" 2 "not_P_gear" 3 "account_not_log_in" 4 "not_authorized" 5 "not_learned" 6 "privacy_mode" 7 "extreme_eco_mode" 8 "lowpower_mode" 9 "function_active" 10 "other_reasons" 11 "Error_Detected" 12 "mainswt_Prevention" ;
VAL_ 769 ADSLDWPSwtFbFrmADD 0 "default" 1 "Off" 2 "Warning" 3 "Warning_Prevention" 4 "unavailable" ;
VAL_ 769 ADSLDWPSwtUnavlRsnFrmADD 0 "default" 1 "No_reason_req" 2 "not_P_gear" 3 "account_not_log_in" 4 "not_authorized" 5 "not_learned" 6 "privacy_mode" 7 "extreme_eco_mode" 8 "lowpower_mode" 9 "function_active" 10 "other_reasons" 11 "Error_Detected" ;
VAL_ 769 ADSLDWPWarnTypSwtFbFrmADD 0 "default" 1 "Audio" 2 "Haptic" 3 "Audio_All_Gray" 4 "unavailable" ;
VAL_ 769 ADSMAISwtFbFrmADD 0 "default" 1 "unavailable" 2 "Off" 3 "On" ;
VAL_ 769 ADSMAISwtUnavlRsnFrmADD 0 "default" 1 "No_reason_req" 2 "not_P_gear" 3 "account_not_log_in" 4 "not_authorized" 5 "not_learned" 6 "privacy_mode" 7 "extreme_eco_mode" 8 "lowpower_mode" 9 "function_active" 10 "other_reasons" 11 "Error_Detected" ;
VAL_ 769 ADSParkAudModSwtStsFrmADD 0 "default" 1 "Off" 2 "Normal" 3 "Simple" 4 "unavailable" ;
VAL_ 769 ADSRCTABSwtFbFrmADD 0 "default" 1 "unavailable" 2 "Off" 3 "Warning" 4 "Warning_Brake" ;
VAL_ 769 ADSRCTABSwtUnavlRsnFrmADD 0 "default" 1 "No_reason_req" 2 "not_P_gear" 3 "account_not_log_in" 4 "not_authorized" 5 "not_learned" 6 "privacy_mode" 7 "extreme_eco_mode" 8 "lowpower_mode" 9 "function_active" 10 "other_reasons" 11 "Error_Detected" ;
VAL_ 769 ADSRCWSwtFbFrmADD 0 "default" 1 "Off" 2 "ON" 3 "unavailable" ;
VAL_ 769 ADSRCWSwtUnavlRsnFrmADD 0 "default" 1 "No_reason_req" 2 "not_P_gear" 3 "account_not_log_in" 4 "not_authorized" 5 "not_learned" 6 "privacy_mode" 7 "extreme_eco_mode" 8 "lowpower_mode" 9 "function_active" 10 "other_reasons" 11 "Error_Detected" ;
VAL_ 769 ADSTLASwtFbFrmADD 0 "default" 1 "unavailable" 2 "Off" 3 "On" ;
VAL_ 769 ADSTLASwtUnavlRsnFrmADD 0 "default" 1 "No_reason_req" 2 "not_P_gear" 3 "account_not_log_in" 4 "not_authorized" 5 "not_learned" 6 "privacy_mode" 7 "extreme_eco_mode" 8 "lowpower_mode" 9 "function_active" 10 "other_reasons" 11 "Error_Detected" ;
VAL_ 769 ALCSwtStsFrmADD 0 "default" 1 "Off" 2 "On" 3 "unavailable" 4 "On_not_support_click" 5 "On_Active" 6 "Off_not_support_click" ;
VAL_ 769 ALCSwtUnavlRsnFrmADD 0 "default" 1 "No_reason_req" 2 "not_P_gear" 3 "account_not_log_in" 4 "not_authorized" 5 "not_learned" 6 "privacy_mode" 7 "extreme_eco_mode" 8 "lowpower_mode" 9 "function_active" 10 "other_reasons" 11 "Error_detected" ;
VAL_ 769 FxdSpdModValSwtStsFrmADD 0 "default" 1 "level_-15" 2 "level_-14" 3 "level_-13" 4 "level_-12" 5 "level_-11" 6 "level_-10" 7 "level_-9" 8 "level_-8" 9 "level_-7" 10 "level_-6" 11 "level_-5" 12 "level_-4" 13 "level_-3" 14 "level_-2" 15 "level_-1" 16 "level_0" 17 "level_1" 18 "level_2" 19 "level_3" 20 "level_4" 21 "level_5" 22 "level_6" 23 "level_7" 24 "level_8" 25 "level_9" 26 "level_10" 27 "level_11" 28 "level_12" 29 "level_13" 30 "level_14" 31 "level_15" 63 "unvailable" ;
VAL_ 769 LaneChgCnfmSwtStsFrmADD 0 "default" 1 "Lane_change_Recommended" 2 "autonomous_lane_change" 3 "unavailable" ;
VAL_ 769 LowPwrReqFrLRRFrmADD 0 "Default" 1 "LRR1_Request" 2 "LRR2_Request" 3 "Reserved" ;
VAL_ 769 LowPwrSwtFbFrmADD 0 "default" 1 "Off" 2 "ON" 3 "On_and_unavailable" 4 "Off_and_unavailable" 5 "Opening" 6 "Closing" ;
VAL_ 769 LowPwrSwtUnavlRsnFrmADD 0 "default" 1 "not_P_gear" 2 "extreme_eco_mode" 3 "Error_detected" 4 "AutoDriving_mode" 5 "PrivacyMode_active" ;
VAL_ 769 LowPwrWarnFrmADD 0 "No_warning" 1 "open_succeed" 2 "open_failure" 3 "close_failure" 4 "close_succeed" ;
VAL_ 769 NOAautoChangingSrAnimation 0 "default" 1 "active" ;
VAL_ 769 NOACtySwtStsFrmADD 0 "default" 1 "Off" 2 "On" 3 "unavailable" 4 "Not_Learn" 5 "On_Active" ;
VAL_ 769 NOAHWSwtStsFrmADD 0 "default" 1 "Off" 2 "On" 3 "unavailable" 4 "On_not_support_click" 5 "On_Active" 6 "Off_not_support_click" ;
VAL_ 769 NOASwtUnavlRsnFrmADD 0 "default" 1 "No_reason_req" 2 "not_P_gear" 3 "account_not_log_in" 4 "not_authorized" 5 "Pilot_not_learned" 6 "privacy_mode" 7 "extreme_eco_mode" 8 "lowpower_mode" 9 "function_active" 10 "adas_not_purchased" 11 "Error_detected" 12 "NOA_not_learned" 13 "Location_limited" ;
VAL_ 769 PcntgeSpdModValSwtStsFrmADD 0 "default" 1 "level_-10" 2 "level_-9" 3 "level_-8" 4 "level_-7" 5 "level_-6" 6 "level_-5" 7 "level_-4" 8 "level_-3" 9 "level_-2" 10 "level_-1" 11 "level_0" 12 "level_1" 13 "level_2" 14 "level_3" 15 "level_4" 16 "level_5" 17 "level_6" 18 "level_7" 19 "level_8" 20 "level_9" 21 "level_10" 31 "unvailable" ;
VAL_ 769 PltSwtStsFrmADD 0 "default" 1 "Off" 2 "On" 3 "unavailable" 4 "On_not_support_click" 5 "On_Active" 6 "Off_not_support_click" ;
VAL_ 769 PltSwtUnavlRsnFrmADD 0 "default" 1 "No_reason_req" 2 "not_P_gear" 3 "account_not_log_in" 4 "not_authorized" 5 "not_learned" 6 "privacy_mode" 7 "extreme_eco_mode" 8 "lowpower_mode" 9 "function_active" 10 "other_reasons" 11 "Error_detected" ;
VAL_ 769 PntCldSwtFbFrmADD 0 "default" 1 "Off" 2 "On" 3 "unavailable" ;
VAL_ 769 PntCldSwtUnavlRsnFrmADD 0 "default" 1 "No_reason_req" 2 "not_P_gear" 3 "account_not_log_in" 4 "not_authorized" 5 "not_learned" 6 "privacy_mode" 7 "extreme_eco_mode" 8 "lowpower_mode" 9 "function_active" 10 "other_reasons" 11 "Error_detected" ;
VAL_ 769 PrivacyModIniStsFrmADD 0 "default" 1 "Initialization_done" ;
VAL_ 769 PrivacyModSwtFbFrmADD 0 "default" 1 "Off" 2 "ON" 3 "unavailable" ;
VAL_ 769 SRLidarCldReqFrmADD 0 "Nocommand" 1 "open" 2 "close" ;
VAL_ 769 VehSpdDvtionModSwtStsFrmADD 0 "default" 1 "fixed_speed_mode" 2 "percentage_speed_mode" 3 "unavailable" ;
VAL_ 177 ADSABALvlFrmADD 0 "NoRequest" 1 "level_1" 2 "level_2" 3 "level_3" ;
VAL_ 177 ADSABAReqFrmADD 0 "no_demand" 1 "demand" ;
VAL_ 177 ADSABPReqFrmADD 0 "no_demand" 1 "demand" ;
VAL_ 177 ADSAEBReqFrmADD 0 "No_demand" 1 "AEB" 2 "EBA" 3 "PMAEB" ;
VAL_ 177 ADSAWBAESLvlFrmADD 0 "NoRequest" 1 "level_1" 2 "level_2" 3 "level_3" 4 "level_4" ;
VAL_ 177 ADSAWBAESReqFrmADD 0 "no_demand" 1 "AWB_demand" 2 "AES_demand" ;
VAL_ 177 ADSMAIAccrPerReqVldFrmADD 0 "invalid" 1 "valid" ;
VAL_ 177 ADSMAIReqFrmADD 0 "no_request" 1 "request" ;
VAL_ 177 ADSMAIReqVldFrmADD 0 "invalid" 1 "valid" ;
VAL_ 177 ADSVibActvFrmADD 0 "inactive" 1 "active" ;
VAL_ 177 DrvAxTarEnaMainFrmADD 0 "NoRequest" 1 "Request" ;
VAL_ 177 DrvBrakePreferredMainFrmADD 0 "False" 1 "True" ;
VAL_ 177 DrvCtrlAvailabilityMainFrmADD 0 "NotAvailable" 1 "Available" ;
VAL_ 177 DrvDriveAwayReqMainFrmADD 0 "NoRequest" 1 "DriveOffrequest" ;
VAL_ 177 DrvPinStrAglReqStsFrmADD 0 "NoRequest" 1 "Ready" 2 "Active" 3 "Failure" ;
VAL_ 177 DrvPrecsReqFrmADD 127 "invalid" ;
VAL_ 177 DrvReqModeMainFrmADD 0 "ADC_None" 1 "ADC_L12" 2 "ADC_L3" ;
VAL_ 177 DrvReqTypeMainFrmADD 0 "ADC_Comfort" 1 "ADC_Emergency" ;
VAL_ 177 DrvSecureReqMainFrmADD 0 "NoRequest" 1 "Request" ;
VAL_ 177 DrvShutdownModeMainFrmADD 0 "ADC_SoftOff" 1 "ADC_FastOff" 2 "ADC_ImmediateOff" ;
VAL_ 177 DrvUseUpperComfBandMainFrmADD 0 "False" 1 "True" ;
VAL_ 177 DrvVehStopReqMainFrmADD 0 "NoRequest" 1 "standstillrequest" ;
VAL_ 193 ADASGearFcnModMainFrmADD 0 "None" 1 "APA" 2 "RPA" 3 "HPP" 4 "AVP" 5 "DynamicAVP" 6 "Driving" 7 "Reserved" ;
VAL_ 193 ADASParkDrvFcnModMainFrmADD 0 "None" 1 "ADC_Human" 2 "ADC_unmanned" 3 "Reserved" 4 "Reserved" ;
VAL_ 193 ADASParkDrvModOverrideFrmADD 0 "None" 1 "NotAllowOverride" 2 "AllowOverride" ;
VAL_ 193 ADASParkDrvVehWheelTqEnaFrmADD 0 "Diable" 1 "Enable" ;
VAL_ 193 ADSAVHReqFrmADD 0 "none" 1 "Request" 2 "Disable" ;
VAL_ 193 ADSEPBReqMainFrmADD 0 "no_request" 1 "Request_Release" 2 "Request_Closed" ;
VAL_ 193 ADSReqModeMainFrmADD 0 "None" 1 "ADC_Human" 2 "ADC_unmanned" 3 "ADC_L3_reserved" 4 "Reserved" ;
VAL_ 193 ADSTqTarEnaMainTypeFrmADD 0 "none" 1 "Enable_Comfort" 2 "Enable_Emergency" ;
VAL_ 237 ADSACCStsFrmADD 0 "Passive" 1 "Standby" 2 "NormalActive" 3 "StandActive" 4 "Override" 5 "StandWait" 6 "Takeover" 7 "Fault" ;
VAL_ 237 CNOAAlrtWarnLv1FrmADD 0 "Default" 1 "VRU_remind" 2 "Reserved_1" 3 "Reserved_2" 4 "Reserved_3" 5 "Reserved_4" ;
VAL_ 237 CNOAAlrtWarnLv3FrmADD 0 "Default" 1 "U-turn_failure" 2 "Takeover_reminder" 3 "Reserved_1" 4 "Reserved_2" 5 "Reserved_3" 6 "Reserved_4" ;
VAL_ 237 CNOAIntrctvCompntTypFrmADD 0 "Default" 1 "Avoid_bus_with_left_lever" 2 "Avoid_bus_with_right_lever" 3 "Avoiding_bus_towards_left" 4 "Avoiding_bus_towards_right" 5 "Trying_to_towards_left_as_much_as_possible" 6 "Trying_to_towards_right_as_much_as_possible" 7 "Passing_through_the_intersection_towards_left" 8 "Passing_through_the_intersection_towards_right" 9 "Pass_through_the_intersection_with_left_lever" 10 "Pass_through_the_intersection_with_right_lever" 11 "Enter_auxiliary_roads_with_left_lever" 12 "Enter_auxiliary_roads_with_right_lever" 13 "Entering_auxiliary_roads_towards_left" 14 "Entering_auxiliary_roads_towards_right" 15 "Avoiding_special_lanes_towards_left" 16 "Avoiding_special_lanes_towards_right" 17 "Reserved_1" 18 "Reserved_2" 19 "Avoid_special_lanes_with_left_lever" 20 "Avoid_special_lanes_with_right_lever" 21 "Reserved_3" 22 "Reserved_4" 23 "Reserved_5" 24 "Reserved_6" 25 "Reserved_7" 26 "Reserved_8" 27 "Reserved_9" 28 "Reserved_10" ;
VAL_ 237 CNOARemd2FrmADD 0 "Default" 1 "Crossroad_drive_away_reminder" 2 "Enter_pending_area_reminder" 3 "Courtesy_to_pedestrians" 4 "Road_speed_limit_reminder" 5 "Crossroad_speed_down_reminder" 6 "Moving_away_from_guardrails" 7 "Driveoff_reminder_for_traffic_light_turns_green" 8 "Stop_reminder_for_traffic_light_turns_red" 9 "Pass_manually_reminder" 10 "turning_left_through_intersection" 11 "turning_right_through_intersection" 12 "going_straight_through_intersection" 13 "Turning_around" 14 "Reserved_1" 15 "Reserved_2" ;
VAL_ 237 CNOARemdFrmADD 0 "Default" 1 "About_to_make_a_U-turn" 2 "U-turn_not_supported" 3 "Lateral_offset_deuto_VRU" 4 "Take_care_of_traffic_light_status" 5 "Stop_for_traffic_light_turns_red" 6 "Pay_attention_to_the_direction_of_traffic" 7 "Change_lanes_manually" 8 "Switch_main_road_to_left_auxiliary_road" 9 "Switch_main_road_to_right_auxiliary_road" 10 "Reserved_1" 11 "Reserved_2" 12 "Reserved_3" 13 "Reserved_4" 14 "Reserved_5" 15 "Reserved_6" 16 "Reserved_7" 17 "Reserved_8" 18 "Reserved_9" 19 "Reserved_10" ;
VAL_ 237 DistLvlLmtDispFrmADD 0 "default" 1 "distance_level_too_low" 2 "distance_level_too_high" ;
VAL_ 237 DrvAlrtWarnLv1FrmADD 0 "default" 1 "general_hands_takeoff_warning" 2 "lane_changing_hands_takeoff_warning" 3 "reserved_0" 4 "reserved_1" ;
VAL_ 237 DrvAlrtWarnLv2FrmADD 0 "default" 1 "lane_keep_quit_dueto_lane_lose" 2 "lane_keep_quit_dueto_curvature" 3 "lane_change_fail_and_warning" 4 "Takeover_reminder" 5 "general_hands_takeoff_warning_lv2" 6 "Takeover_reminder_for_deceleration_limition" 7 "reserved" ;
VAL_ 237 DrvAlrtWarnLv3FrmADD 0 "default" 1 "Takeover_warning" 2 "general_hands_takeoff_warning_lv3" 3 "general_hands_takeoff_warning_lv4" 4 "reserved_0" 5 "reserved_1" ;
VAL_ 237 DrvFltStsFrmADD 0 "NoError" 1 "PerformanceDegradation" 2 "SystemTemporaryUnvailable" 3 "ServiceRequired" 4 "SentryModeNotAvl" ;
VAL_ 237 DrvFltStsVldFrmADD 0 "Valid" 1 "Invalid" ;
VAL_ 237 DrvLatIcnDispStsFrmADD 0 "no_display" 1 "pilot_grey" 2 "pilot_half_light" 3 "pilot_total_light" 4 "pilot_overlay" 5 "pilot_yellow_unable_to_active" 6 "pilot_yellow_system_failure" 7 "noa_grey" 8 "noa_total_light" 9 "noa_overlay" 10 "pilot_only_longitudinal_ready" ;
VAL_ 237 DrvLongIcnDispFrmADD 0 "no_display" 1 "grey" 2 "half_light" 3 "total_light" 4 "yellow_unable_to_active" 5 "yellow_system_failure" ;
VAL_ 237 DrvRemd2FrmADD 0 "default" 1 "override_cannot_break" 2 "lane_searching" 3 "drive_away_warning" 4 "waiting_for_lane_change" 5 "lane_change_waiting_for_freespace" 6 "lane_change_waiting_for_other_reason" 7 "Takeover_reminder_for_cannot_merge" 8 "reserved_0" 9 "reserved_1" 10 "reserved_2" 11 "reserved_3" 12 "reserved_4" 13 "reserved_5" 14 "reserved_6" 15 "reserved_7" ;
VAL_ 237 DrvRemdFrmADD 0 "no_display" 1 "SystemFailed" 2 "TrunkOpen" 3 "SeatbeltReleased" 4 "EPBSwitchPressed" 5 "DoorsOpen" 6 "HoodOpen" 7 "lane_searching_success" 8 "VehicleSpeedIsTooFast" 9 "ESPactiveAIPilotIsQuit" 10 "function_disable" 11 "lane_keep_quit_preinform" 12 "driver_not_in_position" 13 "trailer_mode" 14 "during_braking" 15 "Reserved" 16 "drift_mode" 17 "lane_change_waiting_timeout" 18 "Reserved" 19 "speed_limited_for_lane_curvature" 20 "lane_lose_and_no_following_target" 21 "Function_quit_dueto_bad_weather" 22 "Bad_weather" 23 "FLRC_blockage" 24 "FWRC_blockage" 25 "LSCF_blockage" 26 "LSCR_blockage" 27 "RSCF_blockage" 28 "RSCR_blockage" 29 "LRR_blockage" 30 "handsoff_punishment_only_ACC" 31 "FRSR_blockage" 32 "RLSR_blockage" 33 "RRSR_blockage" 34 "FLRLblockage" 35 "not_log_in" 36 "switch_not_open" 37 "RLRC_blockage" 38 "approaching_the_red_light_" 39 "remind_to_traffic_light" 40 "waiting_area_confirm" 41 "NOA_quit_and_turn_around" 42 "Accelerator_pedal_confirm" 43 "take_over_remind" 44 "waiting_for_pedestrians" 45 "waiting_and_drive_away" 46 "pilot_active_only_acc" 47 "pilot_active" 48 "pilot_quit_initiative" 49 "pilot_quit_passive" 50 "mountain_mode" 51 "lane_change_cancel" 52 "battle_mode" 53 "lane_change_unavailable" 54 "lane_change_fail" 55 "snow_mode" 56 "avoid_the_truck" 57 "lane_complicated" 58 "SOC_initializing" 59 "attention_to_construction_area" 60 "construction_area_and_warning" 61 "Reserved" 62 "reset_steering_rod" 63 "lowpower_mode" 64 "ACC_quit" 65 "extreme_eco_mode" 66 "privacy_mode" 67 "wash_mode" 68 "NotDgear" 69 "ACC_Active" 70 "rescue_mode" 71 "tire_change_mode" 72 "ejector_mode" 73 "NOA_will_quit_dueto_out_of_range" 74 "Not_support_ALC_for_general_reason" 75 "system_failed_dueto_unspecific_reason" 76 "close_to_latest_ramp_entry_point" 77 "close_to_latest_mainroad_entry_point" 78 "close_to_latest_navigation_entry_point" 79 "NOA_active" 80 "NOA_quit" 81 "upgrade_to_NOA" 82 "degrade_to_LCC" 83 "Reserved" 84 "inaccessible_ramp_and_left_lane_change" 85 "inaccessible_ramp_and_right_lane_change" 86 "not_enter_and_towards_left" 87 "not_enter_and_towards_right" 88 "lane_change_fail_and_towards_left" 89 "lane_change_fail_and_towards_right" 90 "lane_keep_quit_dueto_steering_wheel_override" 91 "reset_hazard_light" 92 "overtake_failed_reminder" 93 "general_hands_takeoff_warning_lv0" 94 "reaching_global_speed_limit" 95 "reserved_0" 96 "pay_attention_to_right_cutin_vehicle" 97 "override_too_long_quit_forecast" 98 "override_over_speed_limit" 99 "LCC_quit_on_un-straight_intersection" 100 "drive_mode_unsupported" 101 "drag_racing_mode" 102 "emergency_to_LCC" 103 "pay_attention_to_left_cutin_vehicle" 104 "pay_attention_to_curve" 105 "off_road_mode" 106 "HDC_mode" 107 "Resd1" 108 "Resd2" 109 "Resd3" 110 "Resd4" 111 "Resd5" 112 "Resd6" 113 "Resd7" 114 "Resd8" 115 "Resd9" 116 "Resd10" 117 "Resd11" 118 "Resd12" 119 "Resd13" 120 "Resd14" 121 "Resd15" 122 "Resd16" ;
VAL_ 237 DrvrSelTarSpdFrmADD 255 "invalid" ;
VAL_ 237 DrvSteerWhlBtnLi 0 "No_Request" 1 "Request_breathe_Light" 2 "Reserved" 3 "Reserved" ;
VAL_ 237 DrvStlDispFrmADD 0 "default" 1 "Longitudinal_driving_mode" 2 "lateral_driving_mode" 3 "parking_mode" ;
VAL_ 237 IntrctvCompntTypFrmADD 0 "default" 1 "prepare_to_enter_ramp_with_left_lever" 2 "prepare_to_enter_ramp_with_right_lever" 3 "preparing_enter_ramp_towards_left" 4 "preparing_enter_ramp_towards_right" 5 "enter_ramp_with_left_lever" 6 "enter_ramp_with_right_lever" 7 "entering_ramp_towards_left" 8 "entering_ramp_towards_right" 9 "enter_mainroad_with_left_lever" 10 "enter_mainroad_with_right_lever" 11 "entering_mainroad_towards_left" 12 "entering_mainroad_towards_right" 13 "navigation_lane_change_with_left_lever" 14 "navigation_lane_change_with_right_lever" 15 "navigation_lane_change_towards_left" 16 "navigation_lane_change_towards_right" 17 "enter_faster_lane_with_left_lever" 18 "enter_faster_lane_with_right_lever" 19 "entering_faster_lane_towards_left" 20 "entering_faster_lane_towards_right" 21 "avoid_the_truck_with_left_lever" 22 "avoid_the_truck_with_right_lever" 23 "avoiding_the_truck_towards_left" 24 "avoiding_the_truck_towards_right" 25 "traffic_jam_with_left_lever" 26 "traffic_jam_with_right_lever" 27 "traffic_jam_towards_left" 28 "traffic_jam_towards_right" 29 "avoid_risk_lane_with_left_lever" 30 "avoid_risk_lane_with_right_lever" 31 "avoiding_risk_lane_towards_left" 32 "avoiding_risk_lane_towards_right" 33 "traffic_flows_in_with_left_lever" 34 "traffic_flows_in_with_right_lever" 35 "traffic_flows_in_towards_left" 36 "traffic_flows_in_towards_right" 37 "lane_change_with_left_lever" 38 "lane_change_with_right_lever" 39 "lane_changing_towards_left" 40 "lane_changing_towards_right" 41 "left_lane_change_finish" 42 "right_lane_change_finish" 43 "left_lane_change_failure_low_level" 44 "right_lane_change_failure_low_level" 45 "left_lane_change_failure_high_level" 46 "right_lane_change_failure_high_level" 47 "left_lane_change_cancel" 48 "right_lane_change_cancel" 49 "reserved" 50 "reserved" ;
VAL_ 237 LaneChangeModFrmADD 0 "default" 1 "auto_lane_change" 2 "manual_lane_change" ;
VAL_ 237 ScrnDrvFuncTypFrmADD 0 "default" 1 "pilot_mode" 2 "NOA_mode" 3 "enter_NOA_available_space" 4 "going_to_leave_NOA_available_space" 5 "reserved" 6 "reserved" ;
VAL_ 237 SpdLvlLmtDispFrmADD 0 "default" 1 "set_speed_too_high" 2 "set_speed_too_low" ;
VAL_ 237 TarSpdSetMothodFrmADD 0 "default" 1 "button" 2 "system_spontaneously" 3 "voice_control" ;
VAL_ 1329 ADDChassisCanfdActiveWakeup 0 "passive_wakeup" 1 "active_Wakeup" ;
VAL_ 1329 ADDChassisCanfdRepeatMsgReq 0 "Repeat_Message_State_not_requested" 1 "Repeat_Message_State_requested" ;
VAL_ 1329 ADDChassisCanfdRepeatMsgSt 0 "Not_in_Repeat_Message_State" 1 "In_Repeat_Message_State" ;
VAL_ 1325 ADDChassisCanfdActiveWakeup1 0 "passive_wakeup" 1 "active_Wakeup" ;
VAL_ 1325 ADDChassisCanfdRepeatMsgReq1 0 "Repeat_Message_State_not_requested" 1 "Repeat_Message_State_requested" ;
VAL_ 1325 ADDChassisCanfdRepeatMsgSt1 0 "Not_in_Repeat_Message_State" 1 "In_Repeat_Message_State" ;
VAL_ 425 IMUCalSt 0 "IMU_not_Calibrated" 1 "IMU_Calibrated" ;
VAL_ 425 LonSnsrSt 0 "SIG_IN_SPEC" 1 "SIGNOTAVAIL" 2 "SIGFAIL" 3 "Reserved" ;
VAL_ 426 LatAccrSt 0 "SIG_IN_SPEC" 1 "SIGNOTAVAIL" 2 "SIGFAIL" 3 "Reserved" ;
VAL_ 426 YawRateSnsrSt 0 "SIG_IN_SPEC" 1 "SIGNOTAVAIL" 2 "SIGFAIL" 3 "Reserved" ;
VAL_ 848 ACUWarnLampSts 0 "LampOFF" 1 "LampON" 2 "Blinking" 3 "Reserved" ;
VAL_ 848 DrvrBucSts 0 "Buckled" 1 "Unbuckle" 2 "Reserved" 3 "Reserved" ;
VAL_ 848 PassBucSts 0 "Buckled" 1 "Unbuckle" 2 "Reserved" 3 "Reserved" ;
VAL_ 849 ImpctEvntSts 0 "Normal" 1 "Crash" ;
VAL_ 336 ABAActv 0 "NotActive" 1 "Active" ;
VAL_ 336 ABAAvl 0 "NotAvailable" 1 "Available" ;
VAL_ 336 APBAplAvlBCP 0 "Available" 1 "NotAvailable_fault" 2 "NotAvailable_SpeedLimit" ;
VAL_ 336 APBRelAvlBCP 0 "Available" 1 "NotAvailable_fault" 2 "NotAvailable_withoutpedal" 3 "NotAvailable_withcharging" ;
VAL_ 336 APBStsBkp 0 "Released" 1 "Applied" 2 "Releasing" 3 "Applying" 4 "Undefined" ;
VAL_ 336 BCPBrkLiIllmnReq 0 "NoRequest" 1 "Request" ;
VAL_ 336 BCPBrkSysWarnText 0 "NoWarning" 1 "the_brake_system_fault" 2 "Please_check_because_the_brake_system_leakage" 3 "Overheat_of_brake_system" 4 "reserved" 5 "reserved" 6 "reserved" 7 "reserved" ;
VAL_ 336 BCPMstCylPVld 0 "NotInitialized" 1 "Normal" 2 "Faulty" ;
VAL_ 336 BCPSimulatorPVld 0 "NotInitialized" 1 "Normal" 2 "Faulty" ;
VAL_ 336 BCPSysSts 0 "Off" 1 "DegradedPedalFeeling" 2 "On" ;
VAL_ 336 BrkFldWarn 0 "NoWarning" 1 "Warning" ;
VAL_ 336 BrkFldWarnVld 0 "Invalid" 1 "Valid" ;
VAL_ 336 BrkPedlAppld 0 "NotApplied" 1 "Applied" ;
VAL_ 336 BrkPedlAppldVld 0 "BrkPedlAppld_NotInitialized" 1 "BrkPedlAppld_Normal" 2 "BrkPedlAppld_Faulty" ;
VAL_ 336 BrkPedlPerctVld 0 "Invalid" 1 "Valid" ;
VAL_ 336 HBAActv 0 "NotActive" 1 "Active" ;
VAL_ 336 HBAAvl 0 "NotAvailable" 1 "Available" ;
VAL_ 336 HBBActv 0 "NotActive" 1 "Active" ;
VAL_ 336 InpRodStkVld 0 "Invalid" 1 "Valid" ;
VAL_ 337 ABPActv 0 "NotActive" 1 "Active" ;
VAL_ 337 ABPAvl 0 "NotAvailable" 1 "Available" ;
VAL_ 337 ABSActv 0 "NotActive" 1 "Active" ;
VAL_ 337 ABSErrDetd 0 "Error" 1 "NoError" ;
VAL_ 337 AEBActv 0 "NotActive" 1 "Active" ;
VAL_ 337 AEBAvl 0 "NotAvailable" 1 "Available" ;
VAL_ 337 APBAplAvlBCS 0 "Available" 1 "NotAvailable_fault" 2 "NotAvailable_SpeedLimit" ;
VAL_ 337 APBErrDetd 0 "NotInit" 1 "Normal" 2 "Faulty" ;
VAL_ 337 APBRelAvlBCS 0 "Available" 1 "NotAvailable_fault" 2 "NotAvailable_withoutpedal" 3 "NotAvailable_withcharging" ;
VAL_ 337 APBSts 0 "Released" 1 "Applied" 2 "Releasing" 3 "Applying" 4 "Undefined" ;
VAL_ 337 APBTxtDip 0 "default" 1 "Slope_out_of_specified_limit" 2 "Left_Parking_brake_fail" 3 "Right_Parking_brake_fail" 4 "Hot_parking_brake_system" 5 "Use_APB_Button_to_releaseandappl" 6 "Parking_brake_cannot_hold_vehicle" 7 "Parking_brake_roller_bench_test_mode" 8 "Left_parking_brake_released" 9 "Left_parking_brake_Applied" 10 "reserved" 11 "reserved" 12 "reserved" 13 "reserved" ;
VAL_ 337 AVHAvl 0 "NotAvailable" 1 "Available" ;
VAL_ 337 AVHSts 0 "Off" 1 "Standby" 2 "Active" ;
VAL_ 337 AWBActv 0 "NotActive" 1 "Active" ;
VAL_ 337 AWBAvl 0 "NotAvailable" 1 "Available" ;
VAL_ 337 BCSBrkSysWarnText 0 "NoWarning" 1 "the_brake_system_fault" 2 "Please_check_because_the_brake_system_leakage" 3 "Overheat_of_brake_system" 4 "reserved" 5 "reserved" 6 "reserved" 7 "reserved" ;
VAL_ 337 BrkLiIllmnReq 0 "NoRequest" 1 "Request" ;
VAL_ 337 BrkSysWarnLamp 0 "NoRequest" 1 "YellowLampt" 2 "RedLamp" ;
VAL_ 337 CDPActv 0 "NotActive" 1 "Active" ;
VAL_ 337 CDPAvl 0 "NotAvailable" 1 "Available" ;
VAL_ 337 CSTSts 0 "Off" 1 "Standby" 2 "Active" 3 "Failure" ;
VAL_ 337 DSTActv 0 "NotActive" 1 "Active" ;
VAL_ 337 EBAActv 0 "NotActive" 1 "Active" ;
VAL_ 337 EBDActv 0 "NotActive" 1 "Active" ;
VAL_ 337 EBDErrDetd 0 "Error" 1 "NoError" ;
VAL_ 337 EmgyBrkLiReq 0 "NoRequest" 1 "Request" ;
VAL_ 337 ESCErrDetd 0 "Error" 1 "NoError" ;
VAL_ 337 ESCIntvLamp 0 "NotActive" 1 "Active" ;
VAL_ 337 ESCPataLamp 0 "NoRequest" 1 "Level1Request" 2 "Level2Request" ;
VAL_ 337 ESCSwitchAvl 0 "Available" 1 "Disabled_EscError" 2 "Disabled_EscActvMode" 3 "Disabled_TestDrvMode" 4 "Disabled_ADASMode" 5 "Disabled_NotLogin" 6 "Disabled_NotAuthorized" 7 "Disabled_ExamFailed" ;
VAL_ 337 HBBSts 0 "HBBNormalMode" 1 "HBBFailedBoost" 2 "HBBFailedBoostBackup" 3 "HBBDisabled" ;
VAL_ 337 HBCActv 0 "NotActive" 1 "Active" ;
VAL_ 337 HDCAvl 0 "NotAvailable" 1 "Available" ;
VAL_ 337 HDCCtrlSts 0 "Off" 1 "Standby" 2 "Active" 3 "Reserved" ;
VAL_ 337 HHCActv 0 "NotActive" 1 "Active" ;
VAL_ 337 HHCAvl 0 "NotAvailable" 1 "Available" ;
VAL_ 337 HRBActv 0 "NotActive" 1 "Active" ;
VAL_ 337 HRBAvl 0 "NotAvailable" 1 "Available" ;
VAL_ 337 HydBrkFExist 0 "NotExist" 1 "Exist" ;
VAL_ 337 MstCylPVld 0 "Invalid" 1 "Valid" ;
VAL_ 337 SCMActv 0 "NotActive" 1 "Active" ;
VAL_ 337 SCMAvl 0 "NotAvailable" 1 "Available" ;
VAL_ 337 TCSActv 0 "NotActive" 1 "Active" ;
VAL_ 337 VDCActv 0 "NotActive" 1 "Active" ;
VAL_ 337 VehStandStillIndcr 0 "NotStandstill" 1 "Standstill" ;
VAL_ 337 VehStandStillIndcrVld 0 "Invalid" 1 "Valid" ;
VAL_ 338 APAActrAvl 0 "NotAvailable" 1 "Available" ;
VAL_ 338 APCActvVehHld 0 "False" 1 "True" ;
VAL_ 338 APCDrvrBrkOvrdFlg 0 "False" 1 "True" ;
VAL_ 338 APCFailrSts 0 "NoError" 1 "APC1_APA_DriverNotPresent" 2 "APC24_RPAAVP_TooHighSlope" 3 "TooHighSpeed" 4 "UnexpectEPBApply" 5 "VehicleBlock" 6 "APC24_RPAAVP_TriggerWithoutSecure" 7 "Error" 8 "Reserved" ;
VAL_ 338 APCSts 0 "Standby" 1 "Active_APA" 2 "Active_RPA" 3 "Active_AVP" 4 "Active_DynamicAVP" ;
VAL_ 338 BCSLgtCtrlPtTarTqEna 0 "False" 1 "True" ;
VAL_ 338 CstRgnBlendSts 0 "Off" 1 "DTC_Fault" 2 "LFC_Fault" 3 "Normal" ;
VAL_ 338 DrgTqCtrlActvFA 0 "NotActive" 1 "Active" ;
VAL_ 338 DrgTqCtrlActvRA 0 "NotActive" 1 "Active" ;
VAL_ 338 PtTqRednActvFA 0 "NotActive" 1 "Active" ;
VAL_ 338 PtTqRednActvRA 0 "NotActive" 1 "Active" ;
VAL_ 338 RPAAVPActrAvl 0 "Not_Available" 1 "Available" 2 "Test_Pending" ;
VAL_ 338 TarRecuTqReqSts 0 "NotIntialized" 1 "Normal" 2 "Faulty" ;
VAL_ 352 BrkDiscTSts 0 "Normal" 1 "WarningLevel1" 2 "WarningLevel2" 3 "WarningLevel3" ;
VAL_ 352 BrkDiscTStsAval 0 "NotInitial" 1 "Fault" 2 "Full" ;
VAL_ 352 WhlPEstimdFrntLeVld 0 "Invalid" 1 "Valid" ;
VAL_ 352 WhlPEstimdFrntRiVld 0 "Invalid" 1 "Valid" ;
VAL_ 352 WhlPEstimdReLeVld 0 "Invalid" 1 "Valid" ;
VAL_ 352 WhlPEstimdReRiVld 0 "Invalid" 1 "Valid" ;
VAL_ 179 BCSActrActvForADC 0 "ADC_Normal" 1 "ADC_Active_L12" 2 "ADC_Active_L123" ;
VAL_ 179 BCSActrAvlStsForADC 0 "ADC_NotAvailable_L123" 1 "ADC_NotAvailableBySituation_L123" 2 "ADC_AvailableL12_NotAvailableL3" 3 "ADC_AvailableL12_NotAvailableBySituationL3" 4 "ADC_AvailableWithFault_L3" 5 "ADC_AvailableWithSituationIssue_L3" 6 "ADC_Available_L123" ;
VAL_ 179 BCSActrAvlStsForADCL3 0 "ADC_NotAvailable_L3" 1 "ADC_NotAvailableBySituation_L3" 2 "ADC_AvailableWithFault_L3" 3 "ADC_AvailableWithSituationIssue_L3" 4 "ADC_Available_L3_No_failure" ;
VAL_ 179 BCSActrRampOffStsForADC 0 "ADC_Normal" 1 "ADC_SuspendByOtherBrake" 2 "ADC_SuspendByDriverPropulsion" 3 "ADC_RampOffByDriverBrake" ;
VAL_ 179 BCSActrVldForADC 0 "Invalid" 1 "Valid" ;
VAL_ 179 VehSpdVld 0 "Invalid" 1 "Valid" ;
VAL_ 179 WhlDirFrntLe 0 "Undefined" 1 "Standstill" 2 "Forward" 3 "Backward" ;
VAL_ 179 WhlDirFrntLeVld 0 "Invalid" 1 "Valid" ;
VAL_ 179 WhlDirFrntRi 0 "Undefined" 1 "Standstill" 2 "Forward" 3 "Backward" ;
VAL_ 179 WhlDirFrntRiVld 0 "Invalid" 1 "Valid" ;
VAL_ 179 WhlDirReLe 0 "Undefined" 1 "Standstill" 2 "Forward" 3 "Backward" ;
VAL_ 179 WhlDirReLeVld 0 "Invalid" 1 "Valid" ;
VAL_ 179 WhlDirReRi 0 "Undefined" 1 "Standstill" 2 "Forward" 3 "Backward" ;
VAL_ 179 WhlDirReRiVld 0 "Invalid" 1 "Valid" ;
VAL_ 179 WhlSpdEdgeFrntLeVld 0 "Invalid" 1 "Valid" ;
VAL_ 179 WhlSpdEdgeFrntRiVld 0 "Invalid" 1 "Valid" ;
VAL_ 179 WhlSpdEdgeReLeVld 0 "Invalid" 1 "Valid" ;
VAL_ 179 WhlSpdEdgeReRiVld 0 "Invalid" 1 "Valid" ;
VAL_ 179 WhlSpdFrntLeVld 0 "Invalid" 1 "Valid" ;
VAL_ 179 WhlSpdFrntRiVld 0 "Invalid" 1 "Valid" ;
VAL_ 179 WhlSpdReLeVld 0 "Invalid" 1 "Valid" ;
VAL_ 179 WhlSpdReRiVld 0 "Invalid" 1 "Valid" ;
VAL_ 226 BCSBrkTqReqADSDominantForADS 0 "Not_Dominant" 1 "Dominant" ;
VAL_ 226 BCSTqActrActvForADS 0 "Standby" 1 "ADC_Unmanned" 2 "ADC_L3" 3 "Reserved" ;
VAL_ 226 BCSTqHumanActrAvlStsForADS 0 "NotInitialized" 1 "NotAvailable" 2 "Reserved" 3 "Available" ;
VAL_ 226 BCSTqL3ActrAvlStsForADS 0 "NotInitialized" 1 "NotAvailable" 2 "Test_Pending" 3 "Available" ;
VAL_ 226 BCSTqUnmannedActrAvlStsForADS 0 "NotInitialized" 1 "NotAvailable" 2 "Test_Pending" 3 "Available" ;
VAL_ 353 AVPHPPCtrlAvlSts 0 "Normal" 1 "Degraded" 2 "LossOfRedundancy" 3 "Reserved" ;
VAL_ 353 AVPHPPCtrSts 0 "Prim" 1 "Sec" ;
VAL_ 353 AVPHPPReqFbSts 0 "Initial" 1 "Ready" 2 "Active" 3 "Fault" 4 "Notused" 5 "Notused" 6 "Notused" 7 "Notused" ;
VAL_ 353 AVPHPPReqFltSts 0 "Normal" 1 "VehicleSpeedOutOfRange" 2 "SteeringWheelTorqueOutOfRange" 3 "ImproperHandshaking" 4 "HandshakeTimeout" 5 "EPSInternalFault" 6 "Reserved" 7 "Reserved" 8 "Reserved" 9 "Reserved" 10 "Reserved" 11 "Reserved" 12 "Reserved" 13 "Reserved" 14 "Reserved" 15 "Reserved" ;
VAL_ 353 DSTReqCtrlSts 0 "Normal" 1 "Ready" 2 "Active" 3 "ReversibleError" 4 "InreversibleError" 5 "Reserved" 6 "Reserved" 7 "Reserved" ;
VAL_ 353 FailrSts 0 "SteerNormal" 1 "SteerAssitTempRed" 2 "SteerAssitServReq" 3 "SteerAssitErrStopVehicle" 4 "Notused" 5 "Notused" 6 "Notused" 7 "Notused" ;
VAL_ 353 HODSts 0 "NoInfo" 1 "NotHandsOnOrHandsOff" 2 "HandsOff" 3 "HandsOn" ;
VAL_ 353 HODVld 0 "Valid" 1 "Invalid" ;
VAL_ 353 PASReqFbSts 0 "Initial" 1 "Ready" 2 "Open" 3 "Active" 4 "Fault" 5 "Notused" 6 "Notused" 7 "Notused" ;
VAL_ 353 PASReqFltSts 0 "Normal" 1 "VehicleSpeedOutOfRange" 2 "SteeringWheelTorqueOutOfRange" 3 "AngleRequestOutOfRange" 4 "DeltaAngleRequestOutOfEange" 5 "PASLowPriority" 6 "ImproperHandshaking" 7 "HandshakeTimeout" 8 "EPSInternalFault" ;
VAL_ 992 CcwEOTDet 0 "Not_Learned" 1 "Learned" ;
VAL_ 992 CwEOTDet 0 "Not_Learned" 1 "Learned" ;
VAL_ 181 ADASReqFbStsADD 0 "Initial" 1 "Ready" 2 "Open" 3 "Active" 4 "Fault" 5 "Notused" 6 "Notused" 7 "Notused" ;
VAL_ 181 ADASReqFltStsADD 0 "Normal" 1 "ADAS_Control_not_available" 2 "EPS_RevError" 3 "EPS_IrrevError" 4 "Caused_by_ADAS_failure" 5 "Reserved" 6 "Reserved" 7 "Reserved" ;
VAL_ 181 DrvrSteerActvADD 0 "Notactive" 1 "Active" ;
VAL_ 181 PinionSteerAglSpdVld 0 "Valid" 1 "Invalid" ;
VAL_ 181 PinionSteerAglSpdVldV2C 0 "Valid" 1 "Invalid" ;
VAL_ 181 PinionSteerAglVld 0 "Valid" 1 "Invalid" ;
VAL_ 181 PinionSteerAglVldV2C 0 "Valid" 1 "Invalid" ;
VAL_ 181 SteerWhlTqVld 0 "Valid" 1 "Invalid" ;
VAL_ 181 SteerWhlVibStsADD 0 "NotActive" 1 "Active" ;
VAL_ 343 VCUGearChgFailrSts 0 "No_Error" 1 "Unexpected_GearPosition" ;
VAL_ 343 VCUSpclRoadSurfTypForDisp 0 "default_normal_road" 1 "water_or_slippery" 2 "Ice" 3 "Compact_the_snow" 4 "Soft_Snow" 5 "rough_road_level_1" 6 "Rough_Road_Level_2" 7 "Rough_Road_Level_3" ;
VAL_ 481 LVPwrSplyBattErrSts 0 "no_fault" 1 "fault" ;
VAL_ 481 LVPwrSplyDCDCErrSts 0 "no_fault" 1 "fault" ;
VAL_ 481 LVPwrSplyHiErrSts 0 "no_fault" 1 "fault" ;
VAL_ 481 LVPwrSplyLoErrSts 0 "no_fault" 1 "fault" ;
VAL_ 481 VCUAccrPrmSetAllwd 0 "allowed" 1 "not_allowed" ;
VAL_ 481 VCUBatModAllwd 0 "allowed" 1 "not_allowed" ;
VAL_ 481 VCUDriftModSetSts 0 "not_active" 1 "active" ;
VAL_ 481 VCUDrvModStSts 0 "finished" 1 "in_process" ;
VAL_ 481 VCUExtmECOModStReq 0 "not_active" 1 "active" ;
VAL_ 481 VCULnchPlusSts 0 "Not_active" 1 "Launch_Ready" 2 "Launch_Active" ;
VAL_ 481 VCURgnPrmSetAllwd 0 "allowed" 1 "not_allowed" ;
VAL_ 481 VCUSteerAsstPrmSetAllwd 0 "allowed" 1 "not_allowed" ;
VAL_ 481 VCUSuspDampgPrmSetAllwd 0 "allowed" 1 "not_allowed" ;
VAL_ 481 VCUSuspLvlgPrm1Allwd 0 "allowed" 1 "not_allowed" ;
VAL_ 481 VCUSuspLvlgPrm2Allwd 0 "allowed" 1 "not_allowed" ;
VAL_ 481 VCUSuspLvlgPrm3Allwd 0 "allowed" 1 "not_allowed" ;
VAL_ 481 VCUSuspLvlgPrm4Allwd 0 "allowed" 1 "not_allowed" ;
VAL_ 481 VCUSuspLvlgPrm5Allwd 0 "allowed" 1 "not_allowed" ;
VAL_ 481 VCUWashModEntryAllwd 0 "allowed" 1 "not_allowed" ;
VAL_ 481 VCUWashModExtAllwd 0 "allowed" 1 "not_allowed" ;
VAL_ 514 StsOfIndcr 0 "Noflash" 1 "flashLeft" 2 "flashRight" 3 "Doubleflash" ;
VAL_ 514 SwtIndcr 0 "Noflash" 1 "ShotFlashLeft" 2 "NormalFlashLeft" 3 "ShortFlashRight" 4 "NormalFlashRight" ;
VAL_ 514 SwtIndcrSts 0 "Noflash" 1 "FlashLeft" 2 "FlashRight" ;
VAL_ 547 ExtrLtgStsHiBeam 0 "Off" 1 "On" 2 "Err" 3 "Resd" ;
VAL_ 547 ExtrLtgStsLoBeam 0 "Off" 1 "On" 2 "Err" 3 "Resd" ;
VAL_ 547 ExtrLtgStsStop 0 "Off" 1 "On" 2 "Err" 3 "Resd" ;
VAL_ 547 ExtrLtgStsTurnIndrLe 0 "Off" 1 "On" 2 "Err" 3 "Resd" ;
VAL_ 547 ExtrLtgStsTurnIndrRi 0 "Off" 1 "On" 2 "Err" 3 "Resd" ;
VAL_ 547 VCUSpdLimrSts 0 "Off" 1 "On" ;
VAL_ 724 VCUChrgnModSts 0 "Not_in_charging" 1 "In_preparation" 2 "Charging_in_progress" 3 "Charging_done" 4 "Charging_fault" 5 "Driving_charging" 6 "Charging_stop" 7 "Booking_charging_waiting" 8 "Preheating_in_process" 9 "Warming_in_progress" ;
VAL_ 724 VCUHVExtPortConnectnTypInfo 0 "Non_connected" 1 "AC_Half_connected" 2 "AC_charger_conneccted" 3 "DC_charger_connected" 4 "Wireless_charger_connected" 5 "V2L_connected" 6 "V2V_connected" 7 "Multi_connection" 8 "Charger_connected_with_fault" 9 "DC_Half_connected" ;
VAL_ 144 CarModSts 0 "Normal" 1 "Fcy" 2 "Trsnp" 3 "Showroom" 4 "Dyno" 5 "TestDrv" 6 "Service" 7 "Reserved3" ;
VAL_ 144 DrvActvSts 0 "OFF" 1 "ON" ;
VAL_ 144 PwrModSts 0 "OFF" 1 "Awake" 2 "ACC" 3 "RUN" ;
VAL_ 144 PwrModVld 0 "Valid" 1 "NotValid" ;
VAL_ 144 VCUAccrPedlRatVld 0 "invalid" 1 "valid" ;
VAL_ 144 VCUActDrvMod 0 "Comfort_Mode" 1 "Sport_Mode" 2 "Individual_Mode1" 3 "Individual_Mode2" 4 "Individual_Mode3" 5 "Snow_Mode" 6 "Mountain_Mode" 7 "Battle_Mode" 8 "Extreme_Eco_mode" 9 "Sport_plus_mode" 10 "Off_road_Mode" 11 "Wet_Mode" 12 "Standard_Mode" 13 "AntMtnsick_Mode" ;
VAL_ 144 VCUActGearLvr 0 "P_Park_gear" 1 "R_Reverse_gear" 2 "N_Neutral_gear" 3 "D_Drive_gear" ;
VAL_ 144 VCUActGearLvrVld 0 "Invalid" 1 "Valid" ;
VAL_ 144 VCUDrvOffFcnLim 0 "Normal;" 1 "PowerLimited_Fault." ;
VAL_ 144 VCUFrntEmTqRdy 0 "Not_ready" 1 "Ready" ;
VAL_ 144 VCUGearLvrAvail 0 "Not_Available" 1 "Available" ;
VAL_ 144 VCUPrkgBtnPsd 0 "Not_Active" 1 "active" ;
VAL_ 144 VCUPtRdyFlg 0 "not_active" 1 "active" ;
VAL_ 144 VCUReEmTqRdy 0 "Not_ready" 1 "Ready" ;
VAL_ 144 VCUStsModCst 0 "OPedl_No_RgL1" 1 "OPedl_No_RgL2" 2 "OPedl_No_RgL3" 3 "OPedl_No_RgL4" 4 "OPedl_No_RgL5" 5 "OPedl_No_ADASactive" 6 "OPedl_No_RoadGradientInhbit" 7 "OPedl_No_PowerDown" 16 "OPedl_Stop_RgL1" 17 "OPedl_Stop_RgL2" 18 "OPedl_Stop_RgL3" 19 "OPedl_Stop_RgL4" 20 "OPedl_Stop_RgL5" 21 "OPedl_Crp_RgL1" 22 "OPedl_Crp_RgL2" 23 "OPedl_Crp_RgL3" 24 "OPedl_Crp_RgL4" 25 "OPedl_Crp_RgL5" 26 "OPedl_FW_RgL1" 27 "OPedl_FW_RgL2" 28 "OPedl_FW_RgL3" 29 "OPedl_FW_RgL4" 30 "OPedl_FW_RgL5" ;
VAL_ 144 VCUTarGearLvr 0 "P_Park_gear" 1 "R_Reverse_gear" 2 "N_Neutral_gear" 3 "D_Drive_gear" ;
VAL_ 144 VCUTarGearLvrVld 0 "Invalid" 1 "Valid" ;
VAL_ 144 VCUVirtAccrPedlVld 0 "Invalid" 1 "Valid" ;
VAL_ 195 ActiveOfADB 0 "NotActive" 1 "Active" ;
VAL_ 195 ActnOfDayRunngLampLe 0 "Off" 1 "On" ;
VAL_ 195 ActnOfDayRunngLampRi 0 "Off" 1 "On" ;
VAL_ 195 ActnOfLedFrntPosnLamp 0 "Off" 1 "On" ;
VAL_ 195 ActnOfLedHiBeam 0 "Off" 1 "On" ;
VAL_ 195 ActnOfParkLampLe 0 "Off" 1 "On" ;
VAL_ 195 ActnOfParkLampRi 0 "Off" 1 "On" ;
VAL_ 195 FarewellFuncSet 0 "NotActive" 1 "Active" ;
VAL_ 195 SegmtDirCtrlSet 0 "NotActive" 1 "ActiveDay" 2 "ActiveNight" 3 "MusicShow" ;
VAL_ 195 WelcomeFuncSet 0 "NotActive" 1 "Active" ;
VAL_ 195 WipSpdReqHi 0 "OFF" 1 "ON" ;
VAL_ 195 WipSpdReqLo 0 "OFF" 1 "ON" ;
VAL_ 198 VCUAccrPedlFlg 0 "not_active" 1 "active" ;
VAL_ 198 VCUADASTorqueAvailableSt 0 "Not_Available" 1 "Available" ;
VAL_ 198 VCUADASTqModeFeedback 0 "Standby" 1 "ADC_Human" 2 "ADC_unmanned" 3 "Reserved" 4 "Reserved" ;
VAL_ 198 VCUCstFlg 0 "Not_Active" 1 "active" ;
VAL_ 198 VCUHVSt 0 "OFF" 1 "Precharge" 2 "HV_On" 3 "Fault" ;
VAL_ 198 VCUHydTqReqVld 0 "Invalid;" 1 "Valid;" ;
VAL_ 198 VCULoSocLampReq 0 "Not_active" 1 "Active" ;
VAL_ 198 VCUMaxRgnTqAvlFAVld 0 "Invalid" 1 "Valid" ;
VAL_ 198 VCUMaxRgnTqAvlRAVld 0 "Invalid" 1 "Valid" ;
VAL_ 198 VCUMaxRgnTqAvlVld 0 "Invalid" 1 "Valid" ;
VAL_ 198 VCUPedlTqOvrdAdsFlg 0 "No" 1 "Yes" ;
VAL_ 198 VCUPrkgBtnPsdVld 0 "Invalid" 1 "Valid" ;
VAL_ 198 VCUVehMaxFltLvl 0 "No_Fault" 1 "FaultLevel1" 2 "FaultLevel2" 3 "FaultLevel3" 4 "FaultLevel4" ;
VAL_ 198 WiprSpdModSts 0 "OFF" 1 "Intermittent_wiping_request_LowSpeed" 2 "Intermittent_wiping_request_HighSpeed" 3 "Low_speed_wiping_request" 4 "High_speed_wiping_request" 5 "Auto_wiping_Speed" 6 "Reserved" ;
VAL_ 434 DoorDrvrOutPwrRelsBtnSts 0 "Err" 1 "NotPsd" 2 "Psd" 3 "NoInfo" ;
VAL_ 434 DoorDrvrPwrRelsDlyActv 0 "Idle" 1 "Inactive" 2 "Active" 3 "Reserved" ;
VAL_ 434 DoorDrvrPwrRelsMotDrvSts 0 "NoDrv" 1 "PwrRelsDrv" 2 "PwrRelsRstDrv" 3 "CrashUnlckDrv" 4 "Reserved" ;
VAL_ 434 DoorDrvrSts 0 "Ukwn" 1 "Opend" 2 "Clsd" ;
VAL_ 434 DoorLeReOutPwrRelsBtnSts 0 "Err" 1 "NotPsd" 2 "Psd" 3 "NoInfo" ;
VAL_ 434 DoorLeRePwrRelsDlyActv 0 "Idle" 1 "Inactive" 2 "Active" 3 "Reserved" ;
VAL_ 434 DoorLeReSts 0 "Ukwn" 1 "Opend" 2 "Clsd" ;
VAL_ 434 ExtrMirrFoldEnaFailr 0 "NoFailr" 1 "VolNotOk" 2 "MotNotOk" 3 "VehSpdHigh" 4 "MotOverHeated" 5 "CmuErr" 6 "Reserved1" ;
VAL_ 434 ExtrMirrFoldSts 0 "MirrFoldStsTyp_MirrFoldPosnUndefd" 1 "MirrFoldStsTyp_MirrNotFoldPosn" 2 "MirrFoldStsTyp_MirrFoldPosn" 3 "MirrFoldStsTyp_MirrMovgToNotFold" 4 "MirrFoldStsTyp_MirrMovgToFold" ;
VAL_ 434 LeMirrFoldCmd 0 "MirrFoldCmdTyp_Idle" 1 "MirrFoldCmdTyp_FoldIn" 2 "MirrFoldCmdTyp_FoldOut" ;
VAL_ 434 SwsLinComFltSts 0 "No_Fault" 1 "Node_Miss" ;
VAL_ 368 RLSRRCTBBrkReqFrmSFC 0 "no_request" 1 "request" ;
VAL_ 391 RLSRBSDLCAStsFrmSFC 0 "Off" 1 "Standby" 2 "Active" 3 "Failure" ;
VAL_ 391 RLSRBSDLCASwtFbFrmSFC 0 "default" 1 "unavailable" 2 "Off" 3 "AudWarning" 4 "HptcWarning" ;
VAL_ 391 RLSRBSDLCASwtUnavlRsnFrmSFC 0 "default" 1 "No_reason_req" 2 "not_P_gear" 3 "account_not_log_in" 4 "not_authorized" 5 "not_learned" 6 "privacy_mode" 7 "extreme_eco_mode" 8 "lowpower_mode" 9 "function_active" 10 "other_reasons" 11 "Error_Detected" ;
VAL_ 391 RLSRBSDLCAWarnReqFrmSFC 0 "nowarning" 1 "warninglevel1" 2 "warninglevel2" 3 "reserved" ;
VAL_ 391 RLSRDOWStsFrmSFC 0 "Off" 1 "Standby" 2 "Active" 3 "Failure" ;
VAL_ 391 RLSRDOWSwtFbFrmSFC 0 "default" 1 "Off" 2 "Warning" 3 "Delay_open" 4 "unavailable" ;
VAL_ 391 RLSRDOWSwtUnavlRsnFrmSFC 0 "default" 1 "No_reason_req" 2 "not_P_gear" 3 "account_not_log_in" 4 "not_authorized" 5 "not_learned" 6 "privacy_mode" 7 "extreme_eco_mode" 8 "lowpower_mode" 9 "function_active" 10 "other_reasons" 11 "Error_Detected" ;
VAL_ 391 RLSRDOWWarnReqFrFrmSFC 0 "nowarning" 1 "warninglevel1" 2 "warninglevel2" 3 "reserved" ;
VAL_ 391 RLSRDOWWarnReqReFrmSFC 0 "nowarning" 1 "warninglevel1" 2 "warninglevel2" 3 "reserved" ;
VAL_ 391 RLSRRCTABSwtFbFrmSFC 0 "default" 1 "unavailable" 2 "Off" 3 "Warning" 4 "Warning_Brake" ;
VAL_ 391 RLSRRCTABSwtUnavlRsnFrmSFC 0 "default" 1 "No_reason_req" 2 "not_P_gear" 3 "account_not_log_in" 4 "not_authorized" 5 "not_learned" 6 "privacy_mode" 7 "extreme_eco_mode" 8 "lowpower_mode" 9 "function_active" 10 "other_reasons" 11 "Error_Detected" ;
VAL_ 391 RLSRRCTAStsFrmSFC 0 "Off" 1 "Standby" 2 "Active" 3 "Failure" ;
VAL_ 391 RLSRRCTAWarnReqFrmSFC 0 "no_warning" 1 "warning_level_1" 2 "warning_level_2" ;
VAL_ 391 RLSRRCTBStsFrmSFC 0 "Off" 1 "Standby" 2 "Active" 3 "Failure" ;
VAL_ 391 RLSRRCTBWarnReqFrmSFC 0 "nowarning" 1 "warninglevel1" 2 "warninglevel2" 3 "reserved" ;
VAL_ 391 RLSRRCWStsFrmSFC 0 "Off" 1 "Standby" 2 "Active" 3 "Failure" ;
VAL_ 391 RLSRRCWSwtFbFrmSFC 0 "default" 1 "Off" 2 "ON" 3 "unavailable" ;
VAL_ 391 RLSRRCWSwtUnavlRsnFrmSFC 0 "default" 1 "No_reason_req" 2 "not_P_gear" 3 "account_not_log_in" 4 "not_authorized" 5 "not_learned" 6 "privacy_mode" 7 "extreme_eco_mode" 8 "lowpower_mode" 9 "function_active" 10 "other_reasons" 11 "Error_Detected" ;
VAL_ 391 RLSRRCWWarnReqFrmSFC 0 "nowarning" 1 "warninglevel1" 2 "warninglevel2" ;
VAL_ 383 RRSRRCTBBrkReqFrmSFC 0 "no_request" 1 "request" ;
VAL_ 392 RRSRBSDLCAStsFrmSFC 0 "Off" 1 "Standby" 2 "Active" 3 "Failure" ;
VAL_ 392 RRSRBSDLCASwtFbFrmSFC 0 "default" 1 "unavailable" 2 "Off" 3 "AudWarning" 4 "HptcWarning" ;
VAL_ 392 RRSRBSDLCASwtUnavlRsnFrmSFC 0 "default" 1 "No_reason_req" 2 "not_P_gear" 3 "account_not_log_in" 4 "not_authorized" 5 "not_learned" 6 "privacy_mode" 7 "extreme_eco_mode" 8 "lowpower_mode" 9 "function_active" 10 "other_reasons" 11 "Error_Detected" ;
VAL_ 392 RRSRBSDLCAWarnReqFrmSFC 0 "nowarning" 1 "warninglevel1" 2 "warninglevel2" 3 "reserved" ;
VAL_ 392 RRSRDOWStsFrmSFC 0 "Off" 1 "Standby" 2 "Active" 3 "Failure" ;
VAL_ 392 RRSRDOWSwtFbFrmSFC 0 "default" 1 "Off" 2 "Warning" 3 "Delay_open" 4 "unavailable" ;
VAL_ 392 RRSRDOWSwtUnavlRsnFrmSFC 0 "default" 1 "No_reason_req" 2 "not_P_gear" 3 "account_not_log_in" 4 "not_authorized" 5 "not_learned" 6 "privacy_mode" 7 "extreme_eco_mode" 8 "lowpower_mode" 9 "function_active" 10 "other_reasons" 11 "Error_Detected" ;
VAL_ 392 RRSRDOWWarnReqFrFrmSFC 0 "nowarning" 1 "warninglevel1" 2 "warninglevel2" 3 "reserved" ;
VAL_ 392 RRSRDOWWarnReqReFrmSFC 0 "nowarning" 1 "warninglevel1" 2 "warninglevel2" 3 "reserved" ;
VAL_ 392 RRSRRCTABSwtFbFrmSFC 0 "default" 1 "unavailable" 2 "Off" 3 "Warning" 4 "Warning_Brake" ;
VAL_ 392 RRSRRCTABSwtUnavlRsnFrmSFC 0 "default" 1 "No_reason_req" 2 "not_P_gear" 3 "account_not_log_in" 4 "not_authorized" 5 "not_learned" 6 "privacy_mode" 7 "extreme_eco_mode" 8 "lowpower_mode" 9 "function_active" 10 "other_reasons" 11 "Error_Detected" ;
VAL_ 392 RRSRRCTAStsFrmSFC 0 "Off" 1 "Standby" 2 "Active" 3 "Failure" ;
VAL_ 392 RRSRRCTAWarnReqFrmSFC 0 "no_warning" 1 "warning_level_1" 2 "warning_level_2" ;
VAL_ 392 RRSRRCTBStsFrmSFC 0 "Off" 1 "Standby" 2 "Active" 3 "Failure" ;
VAL_ 392 RRSRRCTBWarnReqFrmSFC 0 "nowarning" 1 "warninglevel1" 2 "warninglevel2" 3 "reserved" ;
VAL_ 392 RRSRRCWStsFrmSFC 0 "Off" 1 "Standby" 2 "Active" 3 "Failure" ;
VAL_ 392 RRSRRCWSwtFbFrmSFC 0 "default" 1 "Off" 2 "ON" 3 "unavailable" ;
VAL_ 392 RRSRRCWSwtUnavlRsnFrmSFC 0 "default" 1 "No_reason_req" 2 "not_P_gear" 3 "account_not_log_in" 4 "not_authorized" 5 "not_learned" 6 "privacy_mode" 7 "extreme_eco_mode" 8 "lowpower_mode" 9 "function_active" 10 "other_reasons" 11 "Error_Detected" ;
VAL_ 392 RRSRRCWWarnReqFrmSFC 0 "nowarning" 1 "warninglevel1" 2 "warninglevel2" ;
VAL_ 403 DoorRiRePwrRelsDlyActv 0 "Idle" 1 "Inactive" 2 "Active" 3 "Reserved" ;
VAL_ 403 DoorRiReSts 0 "Ukwn" 1 "Opend" 2 "Clsd" ;
VAL_ 403 RiMirrFoldCmd 0 "MirrFoldCmdTyp_Idle" 1 "MirrFoldCmdTyp_FoldIn" 2 "MirrFoldCmdTyp_FoldOut" ;
VAL_ 502 DoorPassOutPwrRelsBtnSts 0 "Err" 1 "NotPsd" 2 "Psd" 3 "NoInfo" ;
VAL_ 502 DoorPassPwrRelsDlyActv 0 "Idle" 1 "Inactive" 2 "Active" 3 "Reserved" ;
VAL_ 502 DoorPassSts 0 "Ukwn" 1 "Opend" 2 "Clsd" ;
VAL_ 502 DoorRiReOutPwrRelsBtnSts 0 "Err" 1 "NotPsd" 2 "Psd" 3 "NoInfo" ;
VAL_ 602 RlsRainFallAmnt 0 "0mm_24h" 1 "0_10mm_24h" 2 "10_15mm_24h" 3 "15_25mm_24h" 4 "25_35mm_24h" 5 "35_50mm_24h" 6 "50_70mm_24h" 7 "70_100mm_24h" 8 "100_mm_24h" ;
VAL_ 602 RlsRainFallSts 0 "No_rain" 1 "ligt_rain" 2 "moderate_rain" 3 "heavy_rain" 15 "Invalid" ;
VAL_ 602 RlsRainSnsrFlt 0 "No_fault" 1 "Fault" ;
VAL_ 602 RlsTHumSnsrFlt 0 "No_fault" 1 "Fault" ;
VAL_ 182 FrntLeCurHeiSts 0 "InValid" 1 "Valid" ;
VAL_ 182 FrntRiCurHeiSts 0 "InValid" 1 "Valid" ;
VAL_ 182 ReLeCurHeiSts 0 "InValid" 1 "Valid" ;
VAL_ 182 ReRiCurHeiSts 0 "InValid" 1 "Valid" ;
VAL_ 419 SwtIndcrRaw 0 "Center" 1 "Up" 2 "UpUp" 3 "Dwn" 4 "DwnDwn" 5 "Invalid" ;
VAL_ 263 DateTiDay 0 "init" ;
VAL_ 263 DateTiHr 24 "Invalid" ;
VAL_ 263 DateTiMilsec 0 "0" 999 "999" 1000 "invalid" ;
VAL_ 263 DateTiMins 60 "Invalid" ;
VAL_ 263 DateTiMth 0 "Invalid" ;
VAL_ 263 DateTiSec 60 "Invalid" ;
VAL_ 263 DateTiYr 255 "Invalid" ;
VAL_ 263 TiDomn 0 "UTC_plus_0" 1 "UTC_plus_1" 2 "UTC_plus_2" 3 "UTC_plus_3" 4 "UTC_plus_4" 5 "UTC_plus_5" 6 "UTC_plus_6" 7 "UTC_plus_7" 8 "UTC_plus_8" 9 "UTC_plus_9" 10 "UTC_plus_10" 11 "UTC_plus_11" 12 "UTC_plus_12" 13 "UTC_plus_13" 14 "UTC_plus_14" 15 "UTC_plus_15" 16 "UTC_plus_16" 17 "UTC_plus_17" 18 "UTC_plus_18" 19 "UTC_plus_19" 20 "UTC_plus_20" 21 "UTC_plus_21" 22 "UTC_plus_22" 23 "UTC_plus_23" 24 "Invalid" ;
VAL_ 582 DCDSteerWhlExtrMirrHUDAdjFlg 0 "Idle" 1 "SteeringWheelAdjustPupUp" 2 "ExtrMirrAdjustPupUp" 3 "HUDAdjustPupUp(Reserved)" ;
VAL_ 582 OTAMode 0 "OTA_Install_Mode_disable" 1 "OTA_Install_Mode_enable" ;
VAL_ 720 DCDAvmCamTrigMod 0 "NotInit" 1 "XCDTrigMode" 2 "ADDTrigMode" ;
VAL_ 720 DCDDMSCameraFltSts 0 "No_fault" 1 "Fault" ;
VAL_ 720 DCDDMSdstrctnDetnSts 0 "OFF" 1 "On" ;
VAL_ 720 DCDDMSdstrctnSts 0 "No_distraction" 1 "Mild_distraction" 2 "Moderate_distraction" 3 "Sever_distraction" ;
VAL_ 720 DCDDMSFatgDetnSts 0 "OFF" 1 "On" ;
VAL_ 720 DCDDMSfatgSts 0 "No_fatigue" 1 "Mild_fatigue" 2 "Moderate_fatigue" 3 "sever_fatigue" ;
VAL_ 720 DCDDMSSysFltSts 0 "No_fault" 1 "Fault" ;
VAL_ 720 DCDDVRSrvReq 0 "No_request" 1 "Request" ;
VAL_ 720 DCDGameModSts 0 "OFF" 1 "On" ;
VAL_ 720 DCDPrivacyModeStatus 0 "default" 1 "PrivacyModeOFF" 2 "PrivacyModeON" 3 "reserved" ;
VAL_ 720 DCDsentryModReq 0 "No_request" 1 "Request" ;
VAL_ 720 DCDsentryModSts 0 "Switch_off" 1 "Switch_on" 2 "Standby1" 3 "Standby2" 4 "Alert" 5 "Alarm" 6 "SentryVideoSaving1" 7 "SentryVideoSaving2" ;
VAL_ 720 DCDTSASLIFSwtSts 0 "Default" 1 "OFF" 2 "vision_warning" 3 "vision_and_audio_warning" ;
VAL_ 720 OTALinkMgr 0 "�����˯��" 1 "�������ұ���" ;
VAL_ 720 SRMode 0 "default" 1 "normal" 2 "error" ;
VAL_ 833 ALCLrnSts 0 "not_learn" 1 "pass" ;
VAL_ 833 AVPLrnSts 0 "not_learn" 1 "pass" ;
VAL_ 833 DCDAdCode 0 "Unknown" ;
VAL_ 833 DCDCameraSpdLim 0 "NoLimit" ;
VAL_ 833 DCDNavSts 0 "NoNavigation" 1 "Navigating" 2 "Crusing" 3 "RoutePlanning" ;
VAL_ 833 DCDRoadClass 0 "Unknown" 1 "Freeway" 2 "NationalRoad" 3 "ProvinceRoad" 4 "CountyRoad" 5 "RuralRoad" 6 "InCountyRoad" 7 "CitySpeedWay" 8 "MainRoad" 9 "SecondaryRoad" 10 "CommonRoad" 11 "NonNaviRoad" ;
VAL_ 833 DCDRoadFacSpdLim 0 "NoLimit" 255 "Map_Not_Started" ;
VAL_ 833 DCDRoadType 0 "Unknown" 1 "DivisedLink" 2 "CrossLink" 3 "JCT" 4 "RoundCircle" 5 "ServiceRoad" 6 "SlipRoad" 7 "SideRoad" 8 "SlipJCT" 9 "ExitLink" 10 "EntranceLink" 11 "TurnRightLineA" 12 "TurnRightLineB" 13 "TurnLeftLineA" 14 "TurnLeftLineB" 15 "CommonLink" 16 "TurnLeftRightLine" 53 "ServiceJCTRoad" 56 "ServiceSlipRoad" 58 "ServiceSlipJCTRoad" ;
VAL_ 833 DCDTrfcSts 0 "Unknown" 1 "Open" 2 "Slow" 3 "Jam" 4 "Congested" ;
VAL_ 833 DCDTSASlifSpdDisp 0 "No_display" 511 "Canceled" ;
VAL_ 833 DstUnitDisp 0 "km" 1 "mi" ;
VAL_ 833 HPPLrnSts 0 "not_learn" 1 "pass" ;
VAL_ 833 NOACtyLrnSts 0 "not_learn" 1 "pass" ;
VAL_ 833 NOAHWLrnSts 0 "not_learn" 1 "pass" ;
VAL_ 833 PltLrnSts 0 "not_learn" 1 "pass" ;
VAL_ 833 VehInsSpdDispVld 0 "Valid" 1 "Invalid" ;
VAL_ 837 DCDAcctMod 0 "log_out" 1 "log_in" ;
VAL_ 837 DCDCloudSysnc 0 "CloudSysnc_Off" 1 "CloudSysnc_On" ;
VAL_ 837 DCDGstMod 0 "Default" 1 "No_Guest_Mode" 2 "Guest_Mode" ;
VAL_ 837 DCDICVehCustExperImprvProgSts 0 "Default" 1 "OFF" 2 "ON" 3 "Reserved" ;
VAL_ 837 DCDICVehSrvAuthntSts 0 "Default" 1 "Unauthorized" 2 "Authorized" 3 "Reserved" ;
VAL_ 868 SetMgrAdsACCInitSpdSwt 0 "invalid" 2 "CurrentVehSpd" 3 "CurrentSpdLmt" 7 "Restore" ;
VAL_ 868 SetMgrAdsAEBFCWSwt 0 "invalid" 2 "early" 3 "middle" 4 "late" 7 "Restore" ;
VAL_ 868 SetMgrAdsALCSwtSts 0 "invalid" 1 "Off" 2 "On" 7 "Restore" ;
VAL_ 868 SetMgrAdsAPA2SwtSts 0 "invalid" 1 "Off" 2 "ON" 7 "Restore" ;
VAL_ 868 SetMgrAdsAudModSwt 0 "invalid" 1 "Off" 2 "Escort" 3 "Nomal" 4 "Simple" 7 "Restore" ;
VAL_ 868 SetMgrAdsAutoTurnLiSwt 0 "invalid" 1 "Off" 2 "On" 7 "Restore" ;
VAL_ 868 SetMgrAdsAVPSwtSts 0 "invalid" 1 "Off" 2 "ON" 7 "Restore" ;
VAL_ 868 SetMgrAdsBSDLCASwt 0 "invalid" 2 "Off" 3 "AudWarning" 4 "HptcWarning" 5 "LightWarning" 7 "Restore" ;
VAL_ 868 SetMgrAdsCfgLoadReq 0 "No_Req" 1 "Request" ;
VAL_ 868 SetMgrAdsDOWSwt 0 "invalid" 1 "Off" 2 "Warning" 3 "Delayopen" 7 "Restore" ;
VAL_ 868 SetMgrAdsELKSwSts 0 "Invalid" 1 "Off" 2 "Middle" 3 "High" 7 "Restore" ;
VAL_ 868 SetMgrAdsFxdSpdModValSwt 0 "invalid" 1 "level_-15" 2 "level_-14" 3 "level_-13" 4 "level_-12" 5 "level_-11" 6 "level_-10" 7 "level_-9" 8 "level_-8" 9 "level_-7" 10 "level_-6" 11 "level_-5" 12 "level_-4" 13 "level_-3" 14 "level_-2" 15 "level_-1" 16 "level_0" 17 "level_1" 18 "level_2" 19 "level_3" 20 "level_4" 21 "level_5" 22 "level_6" 23 "level_7" 24 "level_8" 25 "level_9" 26 "level_10" 27 "level_11" 28 "level_12" 29 "level_13" 30 "level_14" 31 "level_15" 64 "Restore" ;
VAL_ 868 SetMgrAdsHPPBckGrLear 0 "invalid" 1 "Off" 2 "ON" 7 "Restore" ;
VAL_ 868 SetMgrAdsHPPSwtSts 0 "invalid" 1 "Off" 2 "ON" 7 "Restore" ;
VAL_ 868 SetMgrAdsIntelgntSpdSwt 0 "invalid" 1 "Off" 2 "On" 7 "Restore" ;
VAL_ 868 SetMgrAdsLaneChgCnfmSwt 0 "invalid" 1 "LaneChangeRecommended" 2 "autonomousLaneChange" 7 "Restore" ;
VAL_ 868 SetMgrAdsLDWPSwt 0 "invalid" 1 "Off" 2 "Warning" 3 "Warning_Prevention" 7 "Restore" ;
VAL_ 868 SetMgrAdsLDWPWarnTypSwt 0 "invalid" 1 "Audio" 2 "Haptic" 7 "Restore" ;
VAL_ 868 SetMgrAdsMAISwtSts 0 "default" 1 "unavailable" 2 "Off" 3 "On" 7 "restore" ;
VAL_ 868 SetMgrAdsModSwt 0 "invalid" 1 "ACC_Mode" 2 "LCC_Mode" 3 "NOA_Mode" 7 "Restore" ;
VAL_ 868 SetMgrAdsNOAHWSwtSts 0 "invalid" 1 "Off" 2 "ON" 7 "Restore" ;
VAL_ 868 SetMgrAdsNOAOddSwt 0 "invalid" 1 "Highway" 2 "Urban_road" 3 "Highway_and_Urban_road" 7 "Restore" ;
VAL_ 868 SetMgrAdsParkAudModSwt 0 "invalid" 1 "Off" 2 "Normal" 3 "Simple" 7 "Restore" ;
VAL_ 868 SetMgrAdsParkSpdSwtSts 0 "invalid" 1 "Standard" 2 "Fast" 7 "Restore" ;
VAL_ 868 SetMgrAdsPcntgeSpdlvlSwt 0 "invalid" 1 "level_-10" 2 "level_-9" 3 "level_-8" 4 "level_-7" 5 "level_-6" 6 "level_-5" 7 "level_-4" 8 "level_-3" 9 "level_-2" 10 "level_-1" 11 "level_0" 12 "level_1" 13 "level_2" 14 "level_3" 15 "level_4" 16 "level_5" 17 "level_6" 18 "level_7" 19 "level_8" 20 "level_9" 21 "level_10" 34 "Restore" ;
VAL_ 868 SetMgrAdsPltSwtSts 0 "invalid" 1 "Off" 2 "ON" 7 "Restore" ;
VAL_ 868 SetMgrAdsPntCldSwt 0 "invalid" 1 "Off" 2 "ON" 7 "Restore" ;
VAL_ 868 SetMgrAdsRCWSwt 0 "invalid" 1 "Off" 2 "ON" 7 "Restore" ;
VAL_ 868 SetMgrAdsTLASwt 0 "default" 2 "Off" 3 "On" 7 "Restore" ;
VAL_ 868 SetMgrAdsTrfcLiCtrlSwt 0 "invalid" 1 "Off" 2 "On" 7 "Restore" ;
VAL_ 868 SetMgrAdsVehDetourSwt 0 "invalid" 1 "Off" 2 "On" 7 "Restore" ;
VAL_ 868 SetMgrAdsVehSpdDvtnModSwt 0 "invalid" 1 "fixed_speed_mode" 2 "percentage_speed_mode" 7 "Restore" ;
VAL_ 868 SetMgrDrvrSeldDstLvl 0 "NoGapSet" 1 "DistanceLevel1" 2 "DistanceLevel2" 3 "DistanceLevel3" 4 "DistanceLevel4" 5 "DistanceLevel5" 7 "Restore" ;
VAL_ 914 TotOdoAcrt 16777215 "Invaild" ;
VAL_ 914 TotOdoAcrtLvlM -2147483648 "Invaild" ;
VAL_ 914 TotOdoAcrtLvlMVld 0 "Valid" 1 "Invalid" ;
VAL_ 914 TotOdoAcrtVld 0 "Valid" 1 "Invalid" ;
VAL_ 932 ADSAEBFCWSwtSet 0 "No_Command" 1 "Off" 2 "early" 3 "middle" 4 "late" ;
VAL_ 932 ADSAESESSSwtSet 0 "No_Command" 1 "Off" 2 "On" ;
VAL_ 932 ADSAPPOpenReq 0 "No_Command" 1 "Request" 2 "Reserved" 3 "Reserved" ;
VAL_ 932 ADSBSDLCASwtSet 0 "No_command" 1 "Off" 2 "AudWarning" 3 "HptcWarning" 4 "LightWarning" ;
VAL_ 932 ADSDOWSwtSet 0 "No_Command" 1 "Off" 2 "Warning" 3 "Delay_open" ;
VAL_ 932 ADSPMAEBSwtSet 0 "No_Command" 1 "Off" 2 "On" ;
VAL_ 932 ADSRCWSwtSet 0 "No_Command" 1 "Off" 2 "On" ;
VAL_ 932 ADSTLASwtSet 0 "No_Command" 1 "Off" 2 "On" ;
VAL_ 932 ADSVcCtrlSwtSet 0 "No_command" 1 "Off" 2 "ON" ;
VAL_ 932 APASwtSet 0 "No_Command" 1 "Off" 2 "On" ;
VAL_ 932 AVPSwtSet 0 "No_Command" 1 "Off" 2 "On" ;
VAL_ 932 DCD2RDParkinChoseButton 0 "None" 1 "Chose_2rd_Park_in" 2 "Chose_No" ;
VAL_ 932 DCDACCInitSpdSwtSet 0 "No_command" 1 "Current_Veh_Spd" 2 "Current_Spd_Limit" ;
VAL_ 932 DCDAdsAutoTurnLiSwtSet 0 "NoCommand" 1 "Off" 2 "On" ;
VAL_ 932 DCDAdsIntelgntSpdSwtSet 0 "No_Command" 1 "Off" 2 "On" ;
VAL_ 932 DCDADSMAISwtSet 0 "No_Command" 1 "Off" 2 "On" ;
VAL_ 932 DCDAdsModSwtSet 0 "No_Command" 1 "ACC_Mode" 2 "LCC_Mode" 3 "NOA_Mode" ;
VAL_ 932 DCDAdsNOAOddSwtSet 0 "No_Command" 1 "Highway" 2 "Urban_road" 3 "Highway_and_Urban_road" ;
VAL_ 932 DCDADSRCTABSwtSet 0 "No_Command" 1 "OFF" 2 "Warning" 3 "warning_and_brake" ;
VAL_ 932 DCDAdsTrfcLiCtrlSwtSet 0 "No_Command" 1 "Off" 2 "On" ;
VAL_ 932 DCDADSVcCtrlDstSet 0 "No_Command" 1 "Up" 2 "Down" 3 "Reserved" ;
VAL_ 932 DCDADSVcCtrlSpdSet 0 "No_Command" 1 "Up" 2 "Down" 3 "Reserved" ;
VAL_ 932 DCDAdsVehDeturSwtSet 0 "Default" 1 "Off" 2 "On" ;
VAL_ 932 DCDAPAButton 0 "No_Request" 1 "Start_APA" 2 "Stop_APA(Reserved)" ;
VAL_ 932 DCDAPAParkOutButton 0 "No_Request" 1 "Start_ParkOut" 2 "Stop_ParkOut" 3 "Reserved" ;
VAL_ 932 DCDAPAParkOutDireSelect 0 "No_Park_Slot" 1 "Cross_FrontLeft_Out" 2 "Cross_FrontVertical_Out" 3 "Cross_FrontRight_Out" 4 "Parallel_FrontLeft_Out" 5 "Parallel_FrontRight_Out" 6 "Tilted_FrontLeft_Out" 7 "Tilted_FrontVertical_Out" 8 "Tilted_FrontRight_Out" 9 "Cross_RearLeft_Out" 10 "Cross_RearVertical_Out" 11 "Cross_RearRight_Out" 12 "Tilted_RearLeft_Out" 13 "Tilted_RearVertical_Out" 14 "Tilted_RearRight_Out" 15 "Reserved" ;
VAL_ 932 DCDAPAParkSlotSelect 0 "None" 1 "Left_ID1" 2 "Left_ID2" 3 "Left_ID3" 4 "Left_ID4" 5 "Left_ID5" 6 "Left_ID6" 7 "Left_ID7" 8 "Left_ID8" 9 "Right_ID1" 10 "Right_ID2" 11 "Right_ID3" 12 "Right_ID4" 13 "Right_ID5" 14 "Right_ID6" 15 "Right_ID7" 16 "Right_ID8" ;
VAL_ 932 DCDAPAPIPOReq 0 "None" 1 "APA_Req" 2 "APA_POC_Req(Reserved)" ;
VAL_ 932 DCDAPAQuitReq 0 "No_Req" 1 "Quit_Req" ;
VAL_ 932 DCDAPAVcCtl 0 "No_Command" 1 "Request_APA" 2 "Quit_APA" 3 "Request_APAParkOut" 4 "Quit_APAParkOut" 5 "Request_APAParkIn" 6 "Quit_APAParkIn" 7 "Reserved" ;
VAL_ 932 DCDAudModSwtSet 0 "No_Command" 1 "Off" 2 "Escort" 3 "Normal" 4 "Simple" ;
VAL_ 932 DCDAutoVehCustExperImprvProgSwt 0 "No_command" 1 "Off" 2 "On" ;
VAL_ 932 DCDAutoVehSrvAuthntSwt 0 "No_Command" 1 "revoke_authorization" 2 "authorize" ;
VAL_ 932 DCDBackMapDfltParkSlotReq 0 "NoCommand" 1 "UseBackMapDfltParkSlotRequest" ;
VAL_ 932 DCDFxdSpdModValSwtSet 0 "No_Command" 1 "level_-15" 2 "level_-14" 3 "level_-13" 4 "level_-12" 5 "level_-11" 6 "level_-10" 7 "level_-9" 8 "level_-8" 9 "level_-7" 10 "level_-6" 11 "level_-5" 12 "level_-4" 13 "level_-3" 14 "level_-2" 15 "level_-1" 16 "level_0" 17 "level_1" 18 "level_2" 19 "level_3" 20 "level_4" 21 "level_5" 22 "level_6" 23 "level_7" 24 "level_8" 25 "level_9" 26 "level_10" 27 "level_11" 28 "level_12" 29 "level_13" 30 "level_14" 31 "level_15" ;
VAL_ 932 DCDHPPBckGrLearSwtSet 0 "No_command" 1 "Off" 2 "ON" ;
VAL_ 932 DCDHPPBckGrPathAutDoLoSet 0 "No_command" 1 "Off" 2 "ON" ;
VAL_ 932 DCDHPPChoseSaveRoute 0 "No_Command" 1 "Save" 2 "NotSave" ;
VAL_ 932 DCDHPPLnVcReq 0 "No_Command" 1 "Request_Learn_HPP" ;
VAL_ 932 DCDHPPLrnReq 0 "NoDemand" 1 "HPP_Learn_Request" 2 "HPP_Learn_Continue_Request" 3 "HPP_Learn_Finish_Request" 4 "HPP_Learn_Cancel_Request" ;
VAL_ 932 DCDHPPParkAlTheWay 0 "NoCommand" 1 "HPPParkAlTheWayRequest" 2 "QuitHPPParkAlTheWayRequest" ;
VAL_ 932 DCDHPPParkingButton 0 "No_Command" 1 "HPP_StartParking_Request" ;
VAL_ 932 DCDHPPPrkReq 0 "NoDemand" 1 "HPP_Start_Request" 2 "HPP_Recover_Request" 3 "HPP_Quit_Request" ;
VAL_ 932 DCDLdwLdpWarnTypSwtSet 0 "No_Command" 1 "Audio" 2 "Haptic" ;
VAL_ 932 DCDLVPwrSwtSet 0 "No_command" 1 "Off" 2 "ON" ;
VAL_ 932 DCDParkAudModSwtSet 0 "No_Command" 1 "Off" 2 "Normal" 3 "Simple" ;
VAL_ 932 DCDParkSpdSwtSet 0 "No_Command" 1 "Standard" 2 "Fast" 3 "Reserved_1" 4 "Reserved_2" 5 "Reserved_3" 6 "Reserved_4" ;
VAL_ 932 DCDPcntgeSpdModValSwtSet 0 "No_Command" 1 "level_-10" 2 "level_-9" 3 "level_-8" 4 "level_-7" 5 "level_-6" 6 "level_-5" 7 "level_-4" 8 "level_-3" 9 "level_-2" 10 "level_-1" 11 "level_0" 12 "level_1" 13 "level_2" 14 "level_3" 15 "level_4" 16 "level_5" 17 "level_6" 18 "level_7" 19 "level_8" 20 "level_9" 21 "level_10" ;
VAL_ 932 DCDPntCldSwtSet 0 "No_Command" 1 "Off" 2 "On" ;
VAL_ 932 DCDTouchdSpdTyp 0 "No_command" 1 "Current_Veh_Spd_touched" 2 "Current_Spd_Limit_touched" ;
VAL_ 932 HPPSwtSet 0 "No_Command" 1 "Off" 2 "On" ;
VAL_ 932 HwNOASwtSet 0 "No_Command" 1 "Off" 2 "On" ;
VAL_ 932 LdwLdpSwtSet 0 "No_Command" 1 "OFF" 2 "Warning" 3 "Warning_Prevention" ;
VAL_ 932 LidarCloudMode 0 "default" 1 "open_succeed" 2 "open_failure" 3 "close_succeed" 4 "close_failure" ;
VAL_ 932 NoaLcSwtSet 0 "No_Command" 1 "Lane_change_recommended" 2 "Autonomous_lane_change" ;
VAL_ 932 OutdoorPakinModeReq 0 "None" 1 "Req_Close_Door" 2 "Close_Door_Cancell" 3 "Req_Outdoor_Confirm" 4 "Outdoor_Confirm" 5 "Reserved_1" 6 "Reserved_2" 7 "Reserved_3" ;
VAL_ 932 PltSwtALCSet 0 "No_Command" 1 "Off" 2 "ALC" ;
VAL_ 932 PltSwtSet 0 "No_Command" 1 "Off" 2 "Pilot" ;
VAL_ 932 ScrnTouchdFuncChange 0 "default" 1 "NOA_to_Pilot" 2 "Pilot_to_NOA" ;
VAL_ 932 ScrnTouchdLaneChange 0 "default" 1 "LaneChangeCancel" ;
VAL_ 932 ScrnTouchdSpd 255 "invalid" ;
VAL_ 932 ScrnTouchdSpdTyp 0 "default" 1 "Current_Spd_Limit_touched" 2 "Current_Spd_Disp_touched" ;
VAL_ 932 VehSpdDvtionModSwtSet 0 "No_Command" 1 "fixed_speed_mode" 2 "percentage_speed_mode" ;
VAL_ 208 LockgCenLockTrigSrc 0 "NoTrigSrc" 1 "RKE_lock_or_unlock" 2 "Keyless_lock_or_unlock" 3 "Interior_buttons_lock_or_unlock" 4 "Speed_lock" 5 "Relocking_lock" 6 "NFC_lock_or_unlock" 7 "Telematics_lock_or_unlock" 8 "Crash_unlock" 9 "Approach_unlock" 10 "Walk_away_lock" 11 "Inside_Others_Unlock_or_lock" 12 "Outside_others_Unlock_or_lock" 13 "RPA_Unlock_or_lock" 14 "Thermal_Run_Away_Unlock" ;
VAL_ 208 LockgDrvrDoorLockCmd 0 "Idle" 1 "Unlock" 2 "Lock" 3 "Crash_unlock" ;
VAL_ 1312 VCCDChassisCanfdActiveWakeup 0 "passive_wakeup" 1 "active_Wakeup" ;
VAL_ 1312 VCCDChassisCanfdRepeatMsgReq 0 "not_requested" 1 "requested" ;
VAL_ 1312 VCCDChassisCanfdRepeatMsgSt 0 "Not_in_Repeat_Message_State" 1 "In_Repeat_Message_State" ;
SIG_GROUP_ 341 HPPAVPSteerReqSigGrp 1 : HPPAVPRecoverIndCtrl HPPAVPSteerReqSigGrpChks HPPAVPSteerReqSigGrpCntr HPPAVPSteerWhlAglReqVal HPPAVPSteerWhlCtrlReqSts;
SIG_GROUP_ 341 ParkSteerWhlAngReqSigGrp 1 : ParkEPSLateralCtrlTypeFrmADD ParkRecoverIndCtrlFrmADD ParkSteerWhlAglReqValFrmADD ParkSteerWhlAngReqSigGrpChks ParkSteerWhlAngReqSigGrpCntr ParkSteerWhlCtrlReqStsFrmADD;
SIG_GROUP_ 341 PASBrkFrmADDSigGrp 1 : ParkAPBReqMainFrmADD PASBrkFcnModMainFrmADD PASBrkFrmADDSigGrpChks PASBrkFrmADDSigGrpCntr PASEmgyBrkReqMainFrmADD PASLoLimForAccrCmftMainFrmADD PASMaxAllwdJerkOfAccrMainFrmADD PASMinAllwdJerkOfAccrMainFrmADD PASRemaDstMainFrmADD PASReqAccCtrlEnaMainFrmADD PASReqBrkPrfeMainFrmADD PASReqDclUtiStslMainFrmADD PASReqDrvOffMainFrmADD PASShdModReqMainFrmADD PASUpprLimForAccrCmftMainFrmADD PASVlcTarAccFromPASMainFrmADD;
SIG_GROUP_ 769 ADSwtStsSigGrp 1 : ACCInitSpdSwtFbFrmADD ACCInitSpdSwtUnavlRsnFrmADD ADSAEBFCWSwtFbFrmADD ADSAEBSwtUnavlRsnFrmADD ADSAESESSSwtFbFrmADD ADSAudModSwtStsFrmADD ADSBSDLCASwtFbFrmADD ADSBSDLCASwtUnavlRsnFrmADD ADSDOWSwtFbFrmADD ADSDOWSwtUnavlRsnFrmADD ADSELKSwtFbFrmADD ADSELKSwtUnavlRsnFrmADD ADSLDPWarnTypSwtUnavlRsnFrmADD ADSLDWPSwtFbFrmADD ADSLDWPSwtUnavlRsnFrmADD ADSLDWPWarnTypSwtFbFrmADD ADSParkAudModSwtStsFrmADD ADSRCTABSwtFbFrmADD ADSRCTABSwtUnavlRsnFrmADD ADSRCWSwtFbFrmADD ADSRCWSwtUnavlRsnFrmADD ADSwtStsSigGrpChks ADSwtStsSigGrpCntr ALCSwtStsFrmADD ALCSwtUnavlRsnFrmADD FxdSpdModValSwtStsFrmADD LaneChgCnfmSwtStsFrmADD LowPwrSwtFbFrmADD LowPwrSwtUnavlRsnFrmADD LowPwrWarnFrmADD NOACtySwtStsFrmADD NOAHWSwtStsFrmADD NOASwtUnavlRsnFrmADD PcntgeSpdModValSwtStsFrmADD PltSwtStsFrmADD PltSwtUnavlRsnFrmADD PntCldSwtFbFrmADD PntCldSwtUnavlRsnFrmADD PrivacyModIniStsFrmADD PrivacyModSwtFbFrmADD VehSpdDvtionModSwtStsFrmADD;
SIG_GROUP_ 131 SynMsgADD2Radar 1 : ChecksumADD2Radar OfsTimeNSecADD2Radar OfsTimeSecADD2Radar SyncMsgOvsADD2Radar SyncMsgSequenceCounterADD2Radar SyncMsgSgwADDtoRadar SyncMsgSyncTimeADD2Radar SyncMsgTimeDomainADD2Radar SyncMsgTypeADD2Radar;
SIG_GROUP_ 177 DrvFcn2FrmADDSigGrp 1 : DrvAxTarEnaMainFrmADD DrvAxTarLowerComfBandMainFrmADD DrvAxTarReqMainFrmADD DrvAxTarUpperComfBandMainFrmADD DrvBrakePreferredMainFrmADD DrvCtrlAvailabilityMainFrmADD DrvdAxTarLowerLimitMainFrmADD DrvdAxTarUpperLimitMainFrmADD DrvDriveAwayReqMainFrmADD DrvFcn2FrmADDSigGrpChks DrvFcn2FrmADDSigGrpCntr DrvReqModeMainFrmADD DrvReqTypeMainFrmADD DrvSecureReqMainFrmADD DrvShutdownModeMainFrmADD DrvUseUpperComfBandMainFrmADD DrvVehStopReqMainFrmADD;
SIG_GROUP_ 177 DrvFcn3FrmADDSigGrp 1 : ADSABALvlFrmADD ADSABAReqFrmADD ADSABPReqFrmADD ADSAEBReqFrmADD ADSAEBTarDecelFrmADD ADSAWBAESLvlFrmADD ADSAWBAESReqFrmADD DrvFcn3FrmADDSigGrpChks DrvFcn3FrmADDSigGrpCntr;
SIG_GROUP_ 177 DrvFcn4FrmADDSigGrp 1 : ADSMAIAccrPerReqFrmADD ADSMAIAccrPerReqVldFrmADD ADSMAIReqFrmADD ADSMAIReqVldFrmADD DrvFcn4FrmADDSigGrpChks DrvFcn4FrmADDSigGrpCntr;
SIG_GROUP_ 177 DrvSteerWhlReqFrmADDSigGrp 1 : ADSVibActvFrmADD DrvPinStrAglReqStsFrmADD DrvPinStrAglReqValFrmADD DrvPrecsReqFrmADD DrvSteerWhlReqFrmADDSigGrpChks DrvSteerWhlReqFrmADDSigGrpCntr DrvSteerWhlTqLimFrmADD;
SIG_GROUP_ 193 ADSBCSTqReq 1 : ADASGearFcnModMainFrmADD ADASParkDrvFcnModMainFrmADD ADASParkDrvModOverrideFrmADD ADASParkDrvVehWheelTqEnaFrmADD ADASParkDrvVehWheelTqReqFrmADD ADSAVHReqFrmADD ADSBCSTqReqChks ADSBCSTqReqCntr ADSEPBReqMainFrmADD ADSReqModeMainFrmADD ADSTqTarEnaMainTypeFrmADD ADSTqTarReqMainFrmADD;
SIG_GROUP_ 237 ADSWarnRemdSigGrp 1 : ADSWarnRemdSigGrpChks ADSWarnRemdSigGrpCntr CNOAAlrtWarnLv1FrmADD CNOAAlrtWarnLv3FrmADD CNOAIntrctvCompntTypFrmADD CNOARemd2FrmADD CNOARemdFrmADD DistLvlLmtDispFrmADD DrvAlrtWarnLv1FrmADD DrvAlrtWarnLv2FrmADD DrvAlrtWarnLv3FrmADD DrvLatIcnDispStsFrmADD DrvLongIcnDispFrmADD DrvRemd2FrmADD DrvRemdFrmADD DrvrSelTarSpdFrmADD DrvSteerWhlBtnLi DrvStlDispFrmADD IntrctvCompntTypFrmADD LaneChangeModFrmADD ScrnDrvFuncTypFrmADD SpdLvlLmtDispFrmADD TarSpdSetMothodFrmADD;
SIG_GROUP_ 237 DrvFcn1FrmADDSigGrp 1 : ADSACCStsFrmADD DrvFcn1FrmADDSigGrpChks DrvFcn1FrmADDSigGrpCntr DrvFltStsFrmADD DrvFltStsVldFrmADD;
SIG_GROUP_ 425 LonAccrSigGrp 1 : LonAccr LonAccrSigGrpChks LonAccrSigGrpCntr LonSnsrSt;
SIG_GROUP_ 426 LatAccrYawRateSigGrp 1 : LatAccr LatAccrSt LatAccrYawRateSigGrpChks LatAccrYawRateSigGrpCntr YawRate YawRateSnsrSt;
SIG_GROUP_ 848 ACUWarnLampStsSigGrp 1 : ACUWarnLampSts ACUWarnLampStsSigGrpChks ACUWarnLampStsSigGrpCntr;
SIG_GROUP_ 849 ImpctEvntStsSigGrp 1 : ImpctEvntSts ImpctEvntStsSigGrpChks ImpctEvntStsSigGrpCntr;
SIG_GROUP_ 336 BcpSysStsSigGrp 1 : APBAplAvlBCP APBRelAvlBCP BCPBrkLiIllmnReq BCPBrkSysWarnText BCPMstCylP BCPMstCylPVld BCPSimulatorP BCPSimulatorPVld BCPSysSts BcpSysStsSigGrpChks BcpSysStsSigGrpCntr BrkFldWarn BrkFldWarnVld BrkPedlAppld BrkPedlAppldVld BrkPedlPerct BrkPedlPerctVld InpRodStk InpRodStkVld;
SIG_GROUP_ 336 BrkAssSigGrp 1 : ABAActv ABAAvl APBStsBkp BrkAssSigGrpChks BrkAssSigGrpCntr HBAActv HBAAvl;
SIG_GROUP_ 337 BcsBasicFcnSigGrp 1 : APBAplAvlBCS APBErrDetd APBRelAvlBCS APBSts AVHAvl AVHSts BcsBasicFcnSigGrpChks BcsBasicFcnSigGrpCntr CDPActv CDPAvl DrvOffTqThd DSTActv DSTSteerTqReq HHCActv HHCAvl SCMActv SCMAvl;
SIG_GROUP_ 337 BcsExtdFcnSigGrp 1 : ABPActv ABPAvl AEBActv AEBAvl AWBActv AWBAvl BcsExtdFcnSigGrpChks BcsExtdFcnSigGrpCntr EBAActv;
SIG_GROUP_ 337 BcsSysCtrSigGrp 1 : ABSActv ABSErrDetd APBTxtDip BCSBrkSysWarnText BcsSysCtrSigGrpChks BcsSysCtrSigGrpCntr BrkLiIllmnReq BrkSysWarnLamp CSTSts EBDActv EBDErrDetd EmgyBrkLiReq ESCErrDetd ESCIntvLamp ESCPataLamp ESCSwitchAvl EstimdSumOfVehHydBrkEachWhl HBBActive HBBSts HBCActv HDCAvl HDCCtrlSts HRBActv HRBAvl HydBrkFExist MstCylPCmp MstCylPVld TCSActv VDCActv VehStandStillIndcr VehStandStillIndcrVld;
SIG_GROUP_ 338 ApcFcnSigGrp 1 : APAActrAvl APCActvVehHld APCDrvrBrkOvrdFlg APCFailrSts ApcFcnSigGrpChks ApcFcnSigGrpCntr APCSts RPAAVPActrAvl;
SIG_GROUP_ 338 BcsTqCtrlSigGrp 1 : BCSLgtCtrlPtTarTq BCSLgtCtrlPtTarTqEna BcsTqCtrlSigGrpChks BcsTqCtrlSigGrpCntr BiasMaxFrntAxle BiasMaxReAxle CstRgnBlendSts CstRgnBlendTqReqFA CstRgnBlendTqReqRA DrgTqCtrlActvFA DrgTqCtrlActvRA PtTqRednActvFA PtTqRednActvRA TarRdcdPtTqFA TarRdcdPtTqRA TarRecuTqReq TarRecuTqReqSts;
SIG_GROUP_ 352 BcsDrvMonSigGrp 1 : BcsDrvMonSigGrpChks BcsDrvMonSigGrpCntr BrkDiscTFrntLe BrkDiscTFrntRi BrkDiscTReLe BrkDiscTReRi BrkDiscTSts BrkDiscTStsAval RgnTqCorrnOffs1 RgnTqCorrnOffs2 RgnTqCorrnOffs3 RgnTqCorrnOffs4 RgnTqCorrnOffs5 RgnTqCorrnOffs6 RgnTqCorrnOffs7 WhlPEstimdFrntLe WhlPEstimdFrntLeVld WhlPEstimdFrntRi WhlPEstimdFrntRiVld WhlPEstimdReLe WhlPEstimdReLeVld WhlPEstimdReRi WhlPEstimdReRiVld;
SIG_GROUP_ 179 AdcFcnSigGrp 1 : AdcFcnSigGrpChks AdcFcnSigGrpCntr BCSActrActvForADC BCSActrAvlStsForADC BCSActrAvlStsForADCL3 BCSActrRampOffStsForADC BCSActrVldForADC;
SIG_GROUP_ 179 WhlStsSigGrp 1 : VehSpd VehSpdVld WhlDirFrntLe WhlDirFrntLeVld WhlDirFrntRi WhlDirFrntRiVld WhlDirReLe WhlDirReLeVld WhlDirReRi WhlDirReRiVld WhlDstTiStampFrntLe WhlDstTiStampFrntRi WhlDstTiStampReLe WhlDstTiStampReRi WhlSpdEdgeFrntLe WhlSpdEdgeFrntLeVld WhlSpdEdgeFrntRi WhlSpdEdgeFrntRiVld WhlSpdEdgeReLe WhlSpdEdgeReLeVld WhlSpdEdgeReRi WhlSpdEdgeReRiVld WhlSpdFrntLe WhlSpdFrntLeVld WhlSpdFrntRi WhlSpdFrntRiVld WhlSpdReLe WhlSpdReLeVld WhlSpdReRi WhlSpdReRiVld WhlStsSigGrpChks WhlStsSigGrpCntr;
SIG_GROUP_ 226 BcsAdsFcnSigGrp 1 : BcsAdsFcnSigGrpChks BcsAdsFcnSigGrpCntr BCSBrkTqActForADS BCSBrkTqReqADSDominantForADS BCSTqActrActvForADS BCSTqDrvReqBrkForADS BCSTqHumanActrAvlStsForADS BCSTqL3ActrAvlStsForADS BCSTqUnmannedActrAvlStsForADS;
SIG_GROUP_ 579 BattSocRawSigGrp 1 : BattSocRaw BattSocRawSigGrpChks BattSocRawSigGrpCntr;
SIG_GROUP_ 579 BattURawSigGrp 1 : BattURaw BattURawSigGrpChks BattURawSigGrpCntr;
SIG_GROUP_ 353 EPSAVPHPPCtrlStsSigGrp 1 : AVPHPPCtrlAvlSts AVPHPPCtrSts AVPHPPReqFbSts AVPHPPReqFltSts EPSAVPHPPCtrlStsSigGrpChks EPSAVPHPPCtrlStsSigGrpCntr;
SIG_GROUP_ 353 FailrStsSigGrp 1 : FailrSts FailrStsSigGrpChks FailrStsSigGrpCntr;
SIG_GROUP_ 353 PasReqSigGrp 1 : PASReqFbSts PASReqFltSts PasReqSigGrpChks PasReqSigGrpCntr;
SIG_GROUP_ 181 AdasReqCtrlADDSigGrp 1 : AdasReqCtrlADDSigGrpChks AdasReqCtrlADDSigGrpCntr ADASReqFbStsADD ADASReqFltStsADD ADASReqOvlySteerWhlTqADD ADASReqOvlyTqADD DrvrSteerActvADD SteerWhlVibStsADD;
SIG_GROUP_ 181 PinionSteerSigGrp 1 : PinionAglSpdV2C PinionSteerAgl PinionSteerAglSpd PinionSteerAglSpdVld PinionSteerAglSpdVldV2C PinionSteerAglV2C PinionSteerAglVld PinionSteerAglVldV2C PinionSteerSigGrpChks PinionSteerSigGrpCntr SteerWhlTq SteerWhlTqVld;
SIG_GROUP_ 343 SpclRoadSurfTypSigGrp 1 : SpclRoadSurfTypSigGrpChks SpclRoadSurfTypSigGrpCntr VCULatSlopForDisp VCULgtSlopForDisp VCUSpclRoadSurfTypForDisp;
SIG_GROUP_ 481 LVPwrSplyBattErrStsSigGrp 1 : LVPwrSplyBattErrSts LVPwrSplyBattErrStsSigGrpChks LVPwrSplyBattErrStsSigGrpCntr;
SIG_GROUP_ 481 LVPwrSplyHiErrStsSigGrp 1 : LVPwrSplyDCDCErrSts LVPwrSplyHiErrSts LVPwrSplyHiErrStsSigGrpChks LVPwrSplyHiErrStsSigGrpCntr;
SIG_GROUP_ 481 LVPwrSplyLoErrStsSigGrp 1 : LVPwrSplyLoErrSts LVPwrSplyLoErrStsSigGrpChks LVPwrSplyLoErrStsSigGrpCntr;
SIG_GROUP_ 481 ModAllwdSigGrp 1 : VCUAccrPrmSetAllwd VCUBatModAllwd VCUDrvModRgnPrmSts VCUExtmECOModStReq VCURgnPrmSetAllwd VCUSteerAsstPrmSetAllwd VCUSuspDampgPrmSetAllwd VCUSuspLvlgPrm1Allwd VCUSuspLvlgPrm2Allwd VCUSuspLvlgPrm3Allwd VCUSuspLvlgPrm4Allwd VCUSuspLvlgPrm5Allwd VCUWashModEntryAllwd VCUWashModExtAllwd;
SIG_GROUP_ 144 PwrModSigGrp 1 : PwrModSigGrpChks PwrModSigGrpCntr PwrModSts PwrModVld;
SIG_GROUP_ 144 VCUActGearSigGrp 1 : VCUActGearLvr VCUActGearLvrVld VCUActGearSigGrpChks VCUActGearSigGrpCntr;
SIG_GROUP_ 144 VcuInpSigGrp 1 : VCUAccrPedlRat VCUAccrPedlRatVld VCUDrvOffFcnLim VCUFrntEmTqRdy VCUGearLvrAvail VcuInpSigGrpChks VcuInpSigGrpCntr VCUPrkgBtnPsd VCUReEmTqRdy VCURgnTqCorrnFac VCUShifterMoveFlg VCUStsModCst VCUTarGearLvr VCUTarGearLvrVld VCUVirtAccrPedl VCUVirtAccrPedlVld;
SIG_GROUP_ 195 LampSigGrpTwo 1 : ActiveOfADB ActnOfDayRunngLampLe ActnOfDayRunngLampRi ActnOfLedFrntPosnLamp ActnOfLedHiBeam ActnOfParkLampLe ActnOfParkLampRi FarewellFuncSet LampSigGrp2Chks LampSigGrp2Cntr SBLDmValSetLe SBLDmValSetRi SegmtDirCtrlSet WelcomeFuncSet;
SIG_GROUP_ 195 WipSpdReqSigGrp 1 : WipSpdReqHi WipSpdReqLo WipSpdReqSigGrpChks WipSpdReqSigGrpCntr;
SIG_GROUP_ 198 VcuEgyMonSigGrp 1 : VCUCstFlg VCUCstRgnTqReq VCUCstRgnTqReqFA VCUCstRgnTqReqRA VcuEgyMonSigGrpChks VcuEgyMonSigGrpCntr VCUHydTqReq VCUHydTqReqVld VCUMaxRgnTqAvl VCUMaxRgnTqAvlFA VCUMaxRgnTqAvlFAVld VCUMaxRgnTqAvlRA VCUMaxRgnTqAvlRAVld VCUMaxRgnTqAvlVld;
SIG_GROUP_ 198 VcuInp3SigGrp 1 : VCUADASDrvrWhlTqReq VCUADASTorqueAvailableSt VCUADASTqModeFeedback VcuInp3SigGrpChks VcuInp3SigGrpCntr;
SIG_GROUP_ 396 LRRSnsrWarnSigGrp 1 : LRRSnsrStsFrmSFC LRRSnsrWarnSigGrpChks LRRSnsrWarnSigGrpCntr;
SIG_GROUP_ 434 PwrRelsMotDrvStsGrp 1 : DoorDrvrPwrRelsMotDrvSts PwrRelsMotDrvStsGrpChks PwrRelsMotDrvStsGrpCntr;
SIG_GROUP_ 368 RLSRBrkSigGrp 1 : RLSRBrkSigGrpChks RLSRBrkSigGrpCntr RLSRRCTBBrkReqFrmSFC RLSRRCTBTarDecelFrmSFC;
SIG_GROUP_ 391 RLSRWarnSigGrp 1 : RLSRBSDLCAStsFrmSFC RLSRBSDLCASwtFbFrmSFC RLSRBSDLCASwtUnavlRsnFrmSFC RLSRBSDLCAWarnReqFrmSFC RLSRDOWStsFrmSFC RLSRDOWSwtFbFrmSFC RLSRDOWSwtUnavlRsnFrmSFC RLSRDOWWarnReqFrFrmSFC RLSRDOWWarnReqReFrmSFC RLSRRCTABSwtFbFrmSFC RLSRRCTABSwtUnavlRsnFrmSFC RLSRRCTAStsFrmSFC RLSRRCTAWarnReqFrmSFC RLSRRCTBStsFrmSFC RLSRRCTBWarnReqFrmSFC RLSRRCWStsFrmSFC RLSRRCWSwtFbFrmSFC RLSRRCWSwtUnavlRsnFrmSFC RLSRRCWWarnReqFrmSFC RLSRWarnSigGrpChks RLSRWarnSigGrpCntr;
SIG_GROUP_ 701 RLSRSnsrWarnSigGrp 1 : RLSRSnsrStsFrmSFC RLSRSnsrWarnSigGrpChks RLSRSnsrWarnSigGrpCntr;
SIG_GROUP_ 383 RRSRBrkSigGrp 1 : RRSRBrkSigGrpChks RRSRBrkSigGrpCntr RRSRRCTBBrkReqFrmSFC RRSRRCTBTarDecelFrmSFC;
SIG_GROUP_ 392 RRSRWarnSigGrp 1 : RRSRBSDLCAStsFrmSFC RRSRBSDLCASwtFbFrmSFC RRSRBSDLCASwtUnavlRsnFrmSFC RRSRBSDLCAWarnReqFrmSFC RRSRDOWStsFrmSFC RRSRDOWSwtFbFrmSFC RRSRDOWSwtUnavlRsnFrmSFC RRSRDOWWarnReqFrFrmSFC RRSRDOWWarnReqReFrmSFC RRSRRCTABSwtFbFrmSFC RRSRRCTABSwtUnavlRsnFrmSFC RRSRRCTAStsFrmSFC RRSRRCTAWarnReqFrmSFC RRSRRCTBStsFrmSFC RRSRRCTBWarnReqFrmSFC RRSRRCWStsFrmSFC RRSRRCWSwtFbFrmSFC RRSRRCWSwtUnavlRsnFrmSFC RRSRRCWWarnReqFrmSFC RRSRWarnSigGrpChks RRSRWarnSigGrpCntr;
SIG_GROUP_ 523 RRSRSnsrWarnSigGrp 1 : RRSRSnsrStsFrmSFC RRSRSnsrWarnSigGrpChks RRSRSnsrWarnSigGrpCntr;
SIG_GROUP_ 182 CurHeiSigGrp 1 : CurHeiSigGrpChks CurHeiSigGrpCntr FrntLeCurHei FrntLeCurHeiSts FrntRiCurHei FrntRiCurHeiSts ReLeCurHei ReLeCurHeiSts ReRiCurHei ReRiCurHeiSts;
SIG_GROUP_ 419 SwtIndcrRawSigGrp 1 : SwtIndcrRaw SwtIndcrRawSigGrpChks SwtIndcrRawSigGrpCntr;
SIG_GROUP_ 720 DCDDMSSigGrp 1 : DCDDMSCameraFltSts DCDDMSdstrctnSts DCDDMSfatgSts DCDDMSSigGrpChks DCDDMSSigGrpCntr DCDDMSSysFltSts;
SIG_GROUP_ 833 DCDNavSigGrp 1 : DCDAdCode DCDCameraSpdLim DCDNavSts DCDRoadClass DCDRoadFacSpdLim DCDRoadType DCDTrfcSts;
SIG_GROUP_ 833 LrnStsSigGrp 1 : ALCLrnSts AVPLrnSts HPPLrnSts LrnStsSigGrpChks LrnStsSigGrpCntr NOACtyLrnSts NOAHWLrnSts PltLrnSts;
SIG_GROUP_ 837 DCDUserIDSigGrp 1 : DCDAcctMod DCDCloudSysnc DCDUserIDBytePos0 DCDUserIDBytePos1 DCDUserIDBytePos10 DCDUserIDBytePos11 DCDUserIDBytePos12 DCDUserIDBytePos13 DCDUserIDBytePos14 DCDUserIDBytePos15 DCDUserIDBytePos2 DCDUserIDBytePos3 DCDUserIDBytePos4 DCDUserIDBytePos5 DCDUserIDBytePos6 DCDUserIDBytePos7 DCDUserIDBytePos8 DCDUserIDBytePos9;
SIG_GROUP_ 932 APARPADrvrReqSigGrp 1 : DCD2RDParkinChoseButton DCDAPAButton DCDAPAParkOutDireSelect DCDAPAParkSlotSelect DCDAPAPIPOReq DCDAPAQuitReq;
SIG_GROUP_ 932 AVPHPPDrvrReqSigGrp 1 : ADSAPPOpenReq DCDBackMapDfltParkSlotReq DCDHPPChoseSaveRoute DCDHPPLrnReq DCDHPPParkAlTheWay DCDHPPParkingButton DCDHPPPrkReq;
